VERSION ""

NS_ :

BS_:

BU_: ETH

BO_ 864 VCLEFT_alertMatrix: 8 Vector__XXX
 SG_ VCLEFT_matrixIndex M : 0|4@1+ (1,0) [0|0] "" Vector__XXX
 SG_ VCLEFT_a001_WatchdogReset m0 : 4|1@1+ (1,0) [0|0] "" Vector__XXX
 SG_ VCLEFT_a061_XCPConnected m1 : 4|1@1+ (1,0) [0|0] "" Vector__XXX
 SG_ VCLEFT_a181_rearDoorLatchRehome m3 : 4|1@1+ (1,0) [0|0] "" Vector__XXX
 SG_ VCLEFT_a241_seatHeatMIAFront m4 : 4|1@1+ (1,0) [0|0] "" Vector__XXX
 SG_ VCLEFT_a301_swcOverVoltage m5 : 4|1@1+ (1,0) [0|0] "" Vector__XXX
 SG_ VCLEFT_a361_stationaryThresholdsIncorrect m6 : 4|1@1+ (1,0) [0|0] "" Vector__XXX
 SG_ VCLEFT_a481_vnf1048SelfTestFailure m8 : 4|1@1+ (1,0) [0|0] "" Vector__XXX
 SG_ VCLEFT_a002_PowerLossReset m0 : 5|1@1+ (1,0) [0|0] "" Vector__XXX
 SG_ VCLEFT_a062_XCPWasConnected m1 : 5|1@1+ (1,0) [0|0] "" Vector__XXX
 SG_ VCLEFT_a122_ICR_MIA m2 : 5|1@1+ (1,0) [0|0] "" Vector__XXX
 SG_ VCLEFT_a182_emergencyLatchRel m3 : 5|1@1+ (1,0) [0|0] "" Vector__XXX
 SG_ VCLEFT_a242_seatHeatIRearL m4 : 5|1@1+ (1,0) [0|0] "" Vector__XXX
 SG_ VCLEFT_a302_blowerGeneralFault m5 : 5|1@1+ (1,0) [0|0] "" Vector__XXX
 SG_ VCLEFT_a362_movingThresholdsIncorrect m6 : 5|1@1+ (1,0) [0|0] "" Vector__XXX
 SG_ VCLEFT_a482_NCV77XXFault m8 : 5|1@1+ (1,0) [0|0] "" Vector__XXX
 SG_ VCLEFT_a003_SWAssertion m0 : 6|1@1+ (1,0) [0|0] "" Vector__XXX
 SG_ VCLEFT_a063_SwitchFault m1 : 6|1@1+ (1,0) [0|0] "" Vector__XXX
 SG_ VCLEFT_a123_AID_MIA m2 : 6|1@1+ (1,0) [0|0] "" Vector__XXX
 SG_ VCLEFT_a183_doorStateFactoryTest m3 : 6|1@1+ (1,0) [0|0] "" Vector__XXX
 SG_ VCLEFT_a243_seatHeatShortRearL m4 : 6|1@1+ (1,0) [0|0] "" Vector__XXX
 SG_ VCLEFT_a303_eFuseMgmtWindowLift m5 : 6|1@1+ (1,0) [0|0] "" Vector__XXX
 SG_ VCLEFT_a363_liftgateOpenAngleSetReq m6 : 6|1@1+ (1,0) [0|0] "" Vector__XXX
 SG_ VCLEFT_a483_leftTurnLightFaultUser m8 : 6|1@1+ (1,0) [0|0] "" Vector__XXX
 SG_ VCLEFT_a064_busSleepReqTimeout m1 : 7|1@1+ (1,0) [0|0] "" Vector__XXX
 SG_ VCLEFT_a244_seatHeatMIARearL m4 : 7|1@1+ (1,0) [0|0] "" Vector__XXX
 SG_ VCLEFT_a304_frontIntHandleUnexpectedVoltage m5 : 7|1@1+ (1,0) [0|0] "" Vector__XXX
 SG_ VCLEFT_a484_leftBrakeLightFaultUser m8 : 7|1@1+ (1,0) [0|0] "" Vector__XXX
 SG_ VCLEFT_a005_CANTXError m0 : 8|1@1+ (1,0) [0|0] "" Vector__XXX
 SG_ VCLEFT_a065_emiosIsrRateLimitedDbg m1 : 8|1@1+ (1,0) [0|0] "" Vector__XXX
 SG_ VCLEFT_a185_summonAborted m3 : 8|1@1+ (1,0) [0|0] "" Vector__XXX
 SG_ VCLEFT_a245_seatHeatIRearC m4 : 8|1@1+ (1,0) [0|0] "" Vector__XXX
 SG_ VCLEFT_a305_rearIntHandleUnexpectedVoltage m5 : 8|1@1+ (1,0) [0|0] "" Vector__XXX
 SG_ VCLEFT_a365_pitchUnlatchDisabled m6 : 8|1@1+ (1,0) [0|0] "" Vector__XXX
 SG_ VCLEFT_a545_LVBatteryTypeUnknown m9 : 8|1@1+ (1,0) [0|0] "" Vector__XXX
 SG_ VCLEFT_a006_CANTX_cyclicError m0 : 9|1@1+ (1,0) [0|0] "" Vector__XXX
 SG_ VCLEFT_a066_emiosIsrShortPeriodDetectedDbg m1 : 9|1@1+ (1,0) [0|0] "" Vector__XXX
 SG_ VCLEFT_a186_latchReleaseFailedF m3 : 9|1@1+ (1,0) [0|0] "" Vector__XXX
 SG_ VCLEFT_a246_seatHeatShortRearC m4 : 9|1@1+ (1,0) [0|0] "" Vector__XXX
 SG_ VCLEFT_a306_handleDisconnectedF m5 : 9|1@1+ (1,0) [0|0] "" Vector__XXX
 SG_ VCLEFT_a426_seatAbuseMotorWarn m7 : 9|1@1+ (1,0) [0|0] "" Vector__XXX
 SG_ VCLEFT_a546_mirrorFoldTypeChanged m9 : 9|1@1+ (1,0) [0|0] "" Vector__XXX
 SG_ VCLEFT_a187_latchReleaseFailedR m3 : 10|1@1+ (1,0) [0|0] "" Vector__XXX
 SG_ VCLEFT_a247_seatHeatMIARearC m4 : 10|1@1+ (1,0) [0|0] "" Vector__XXX
 SG_ VCLEFT_a307_handleDisconnectedR m5 : 10|1@1+ (1,0) [0|0] "" Vector__XXX
 SG_ VCLEFT_a427_seatAbuseMotorStop m7 : 10|1@1+ (1,0) [0|0] "" Vector__XXX
 SG_ VCLEFT_a188_latchUnableToRearmF m3 : 11|1@1+ (1,0) [0|0] "" Vector__XXX
 SG_ VCLEFT_a248_seatHeatIRearR m4 : 11|1@1+ (1,0) [0|0] "" Vector__XXX
 SG_ VCLEFT_a308_sirenMIA m5 : 11|1@1+ (1,0) [0|0] "" Vector__XXX
 SG_ VCLEFT_a428_seatAbuseBufferWarn m7 : 11|1@1+ (1,0) [0|0] "" Vector__XXX
 SG_ VCLEFT_a129_blowerICLatchFault m2 : 12|1@1+ (1,0) [0|0] "" Vector__XXX
 SG_ VCLEFT_a189_latchUnableToRearmR m3 : 12|1@1+ (1,0) [0|0] "" Vector__XXX
 SG_ VCLEFT_a249_seatHeatShortRearR m4 : 12|1@1+ (1,0) [0|0] "" Vector__XXX
 SG_ VCLEFT_a309_brakeSwitchFaulted m5 : 12|1@1+ (1,0) [0|0] "" Vector__XXX
 SG_ VCLEFT_a429_seatAbuseBufferFull m7 : 12|1@1+ (1,0) [0|0] "" Vector__XXX
 SG_ VCLEFT_a010_ExtSupplyVoltError m0 : 13|1@1+ (1,0) [0|0] "" Vector__XXX
 SG_ VCLEFT_a130_blowerICWarning m2 : 13|1@1+ (1,0) [0|0] "" Vector__XXX
 SG_ VCLEFT_a190_eFuseMgmtVbatFused m3 : 13|1@1+ (1,0) [0|0] "" Vector__XXX
 SG_ VCLEFT_a250_seatHeatMIARearR m4 : 13|1@1+ (1,0) [0|0] "" Vector__XXX
 SG_ VCLEFT_a310_mirrorFoldStall m5 : 13|1@1+ (1,0) [0|0] "" Vector__XXX
 SG_ VCLEFT_a370_seat2RowPitchUnlatched m6 : 13|1@1+ (1,0) [0|0] "" Vector__XXX
 SG_ VCLEFT_a490_vehicleOccupiedOnOTAStart m8 : 13|1@1+ (1,0) [0|0] "" Vector__XXX
 SG_ VCLEFT_a550_ambientTempDelta m9 : 13|1@1+ (1,0) [0|0] "" Vector__XXX
 SG_ VCLEFT_a131_blowerICTransFault m2 : 14|1@1+ (1,0) [0|0] "" Vector__XXX
 SG_ VCLEFT_a191_TLCOvercurrent m3 : 14|1@1+ (1,0) [0|0] "" Vector__XXX
 SG_ VCLEFT_a251_seatUncalTrack m4 : 14|1@1+ (1,0) [0|0] "" Vector__XXX
 SG_ VCLEFT_a311_leftBrakeLightFault m5 : 14|1@1+ (1,0) [0|0] "" Vector__XXX
 SG_ VCLEFT_a371_seat2RowTrackUnlatched m6 : 14|1@1+ (1,0) [0|0] "" Vector__XXX
 SG_ VCLEFT_a551_interiorDoorRequestInhibited m9 : 14|1@1+ (1,0) [0|0] "" Vector__XXX
 SG_ VCLEFT_a012_CPUReset m0 : 15|1@1+ (1,0) [0|0] "" Vector__XXX
 SG_ VCLEFT_a132_blowerSoftStall m2 : 15|1@1+ (1,0) [0|0] "" Vector__XXX
 SG_ VCLEFT_a192_blowerGeneralFault m3 : 15|1@1+ (1,0) [0|0] "" Vector__XXX
 SG_ VCLEFT_a252_seatUncalBack m4 : 15|1@1+ (1,0) [0|0] "" Vector__XXX
 SG_ VCLEFT_a312_leftTailLightFault m5 : 15|1@1+ (1,0) [0|0] "" Vector__XXX
 SG_ VCLEFT_a372_seat2RowBackrestUnlatched m6 : 15|1@1+ (1,0) [0|0] "" Vector__XXX
 SG_ VCLEFT_a013_AlertManagerFault m0 : 16|1@1+ (1,0) [0|0] "" Vector__XXX
 SG_ VCLEFT_a133_blowerLowRPMCBang m2 : 16|1@1+ (1,0) [0|0] "" Vector__XXX
 SG_ VCLEFT_a193_blowerMIA m3 : 16|1@1+ (1,0) [0|0] "" Vector__XXX
 SG_ VCLEFT_a253_seatUncalTilt m4 : 16|1@1+ (1,0) [0|0] "" Vector__XXX
 SG_ VCLEFT_a313_leftFootwellLightFault m5 : 16|1@1+ (1,0) [0|0] "" Vector__XXX
 SG_ VCLEFT_a373_windowSwOpenReqInDogMode m6 : 16|1@1+ (1,0) [0|0] "" Vector__XXX
 SG_ VCLEFT_a493_12vSocketFrontEFuseTrip m8 : 16|1@1+ (1,0) [0|0] "" Vector__XXX
 SG_ VCLEFT_a134_SteerColUpDownUnCal m2 : 17|1@1+ (1,0) [0|0] "" Vector__XXX
 SG_ VCLEFT_a254_seatUncalLift m4 : 17|1@1+ (1,0) [0|0] "" Vector__XXX
 SG_ VCLEFT_a314_leftMapPocketLightFault m5 : 17|1@1+ (1,0) [0|0] "" Vector__XXX
 SG_ VCLEFT_a374_trailerLightFaultModelY m6 : 17|1@1+ (1,0) [0|0] "" Vector__XXX
 SG_ VCLEFT_a494_12vSocketRearEFuseTrip m8 : 17|1@1+ (1,0) [0|0] "" Vector__XXX
 SG_ VCLEFT_a015_NVMMError m0 : 18|1@1+ (1,0) [0|0] "" Vector__XXX
 SG_ VCLEFT_a135_SteerColInOutUnCal m2 : 18|1@1+ (1,0) [0|0] "" Vector__XXX
 SG_ VCLEFT_a315_leftInteriorTrunkLightFault m5 : 18|1@1+ (1,0) [0|0] "" Vector__XXX
 SG_ VCLEFT_a375_windowPinchOverrideNudge m6 : 18|1@1+ (1,0) [0|0] "" Vector__XXX
 SG_ VCLEFT_a016_NVMMRecordError m0 : 19|1@1+ (1,0) [0|0] "" Vector__XXX
 SG_ VCLEFT_a136_brakeSwitchMismatch m2 : 19|1@1+ (1,0) [0|0] "" Vector__XXX
 SG_ VCLEFT_a196_VEHCANOverterminate m3 : 19|1@1+ (1,0) [0|0] "" Vector__XXX
 SG_ VCLEFT_a316_mirrorPrematureFoldStall m5 : 19|1@1+ (1,0) [0|0] "" Vector__XXX
 SG_ VCLEFT_a376_seat2RowBridgeCurrentExceeded m6 : 19|1@1+ (1,0) [0|0] "" Vector__XXX
 SG_ VCLEFT_a017_NVMMStatusDbg m0 : 20|1@1+ (1,0) [0|0] "" Vector__XXX
 SG_ VCLEFT_a137_VCSECPowerCycled m2 : 20|1@1+ (1,0) [0|0] "" Vector__XXX
 SG_ VCLEFT_a197_VEHCANUndertrminate m3 : 20|1@1+ (1,0) [0|0] "" Vector__XXX
 SG_ VCLEFT_a317_epbmLimpModeEnabled m5 : 20|1@1+ (1,0) [0|0] "" Vector__XXX
 SG_ VCLEFT_a617_APP_MIA m10 : 20|1@1+ (1,0) [0|0] "" Vector__XXX
 SG_ VCLEFT_a138_consoleDoorAssist m2 : 21|1@1+ (1,0) [0|0] "" Vector__XXX
 SG_ VCLEFT_a318_trailerIncorrectConfig m5 : 21|1@1+ (1,0) [0|0] "" Vector__XXX
 SG_ VCLEFT_a139_BLERearPowerCycled m2 : 22|1@1+ (1,0) [0|0] "" Vector__XXX
 SG_ VCLEFT_a259_latchDisarmDelayF m4 : 22|1@1+ (1,0) [0|0] "" Vector__XXX
 SG_ VCLEFT_a499_epbmInvalidateCdp m8 : 22|1@1+ (1,0) [0|0] "" Vector__XXX
 SG_ VCLEFT_a140_BLELeftPowerCycled m2 : 23|1@1+ (1,0) [0|0] "" Vector__XXX
 SG_ VCLEFT_a200_motorPhantomEncoder m3 : 23|1@1+ (1,0) [0|0] "" Vector__XXX
 SG_ VCLEFT_a260_latchDisarmDelayR m4 : 23|1@1+ (1,0) [0|0] "" Vector__XXX
 SG_ VCLEFT_a320_windowReportCrackedAtTrimClear m5 : 23|1@1+ (1,0) [0|0] "" Vector__XXX
 SG_ VCLEFT_a380_steerColThermalLimited m6 : 23|1@1+ (1,0) [0|0] "" Vector__XXX
 SG_ VCLEFT_a500_eFuseASICStateMismatch m8 : 23|1@1+ (1,0) [0|0] "" Vector__XXX
 SG_ VCLEFT_a021_TaskSchedulerError m0 : 24|1@1+ (1,0) [0|0] "" Vector__XXX
 SG_ VCLEFT_a141_12VAuxPowerTrip m2 : 24|1@1+ (1,0) [0|0] "" Vector__XXX
 SG_ VCLEFT_a201_motorDutyEncDisabl m3 : 24|1@1+ (1,0) [0|0] "" Vector__XXX
 SG_ VCLEFT_a261_emergencyLatchRelRear m4 : 24|1@1+ (1,0) [0|0] "" Vector__XXX
 SG_ VCLEFT_a321_windowRezeroedDebugF m5 : 24|1@1+ (1,0) [0|0] "" Vector__XXX
 SG_ VCLEFT_a381_pitchEstimation1 m6 : 24|1@1+ (1,0) [0|0] "" Vector__XXX
 SG_ VCLEFT_a501_vnf1048ConfigurationMismatch m8 : 24|1@1+ (1,0) [0|0] "" Vector__XXX
 SG_ VCLEFT_a022_TaskInitError m0 : 25|1@1+ (1,0) [0|0] "" Vector__XXX
 SG_ VCLEFT_a082_VCRIGHT_IPC_MIA m1 : 25|1@1+ (1,0) [0|0] "" Vector__XXX
 SG_ VCLEFT_a202_epbmUnderIStatic m3 : 25|1@1+ (1,0) [0|0] "" Vector__XXX
 SG_ VCLEFT_a322_windowRezeroedDebugR m5 : 25|1@1+ (1,0) [0|0] "" Vector__XXX
 SG_ VCLEFT_a382_pitchEstimation2 m6 : 25|1@1+ (1,0) [0|0] "" Vector__XXX
 SG_ VCLEFT_a083_VCLEFT_IPC_MIA m1 : 26|1@1+ (1,0) [0|0] "" Vector__XXX
 SG_ VCLEFT_a143_mirrorManuallyFolded m2 : 26|1@1+ (1,0) [0|0] "" Vector__XXX
 SG_ VCLEFT_a203_epbmOverIStatic m3 : 26|1@1+ (1,0) [0|0] "" Vector__XXX
 SG_ VCLEFT_a263_seatTrackStallDebug m4 : 26|1@1+ (1,0) [0|0] "" Vector__XXX
 SG_ VCLEFT_a323_mirrorCalibrated m5 : 26|1@1+ (1,0) [0|0] "" Vector__XXX
 SG_ VCLEFT_a383_steerColInOutMotorStallCurrent m6 : 26|1@1+ (1,0) [0|0] "" Vector__XXX
 SG_ VCLEFT_a084_TPMS_MIA m1 : 27|1@1+ (1,0) [0|0] "" Vector__XXX
 SG_ VCLEFT_a204_epbmUnderIDyn m3 : 27|1@1+ (1,0) [0|0] "" Vector__XXX
 SG_ VCLEFT_a264_seatBackStallDebug m4 : 27|1@1+ (1,0) [0|0] "" Vector__XXX
 SG_ VCLEFT_a324_mirrorHeatFault m5 : 27|1@1+ (1,0) [0|0] "" Vector__XXX
 SG_ VCLEFT_a384_steerColUpDownMotorStallCurrent m6 : 27|1@1+ (1,0) [0|0] "" Vector__XXX
 SG_ VCLEFT_a444_drv8703Fault m7 : 27|1@1+ (1,0) [0|0] "" Vector__XXX
 SG_ VCLEFT_a085_CCCM_MIA m1 : 28|1@1+ (1,0) [0|0] "" Vector__XXX
 SG_ VCLEFT_a145_brakeSwitchStuck m2 : 28|1@1+ (1,0) [0|0] "" Vector__XXX
 SG_ VCLEFT_a205_epbmOverIDyn m3 : 28|1@1+ (1,0) [0|0] "" Vector__XXX
 SG_ VCLEFT_a265_seatTiltStallDebug m4 : 28|1@1+ (1,0) [0|0] "" Vector__XXX
 SG_ VCLEFT_a325_hghtSnsrUnplgdFL m5 : 28|1@1+ (1,0) [0|0] "" Vector__XXX
 SG_ VCLEFT_a385_steerColInOutMotorUnderCurrent m6 : 28|1@1+ (1,0) [0|0] "" Vector__XXX
 SG_ VCLEFT_a445_drv8703SpiFaultDBG m7 : 28|1@1+ (1,0) [0|0] "" Vector__XXX
 SG_ VCLEFT_a086_VCBATT_MIA m1 : 29|1@1+ (1,0) [0|0] "" Vector__XXX
 SG_ VCLEFT_a206_epbWrongDirection m3 : 29|1@1+ (1,0) [0|0] "" Vector__XXX
 SG_ VCLEFT_a266_seatLiftStallDebug m4 : 29|1@1+ (1,0) [0|0] "" Vector__XXX
 SG_ VCLEFT_a326_hghtSnsrUnplgdRL m5 : 29|1@1+ (1,0) [0|0] "" Vector__XXX
 SG_ VCLEFT_a386_steerColUpDownMotorUnderCurrent m6 : 29|1@1+ (1,0) [0|0] "" Vector__XXX
 SG_ VCLEFT_a446_trailerAuxReversePower m7 : 29|1@1+ (1,0) [0|0] "" Vector__XXX
 SG_ VCLEFT_a087_DIREL_MIA m1 : 30|1@1+ (1,0) [0|0] "" Vector__XXX
 SG_ VCLEFT_a207_epbmEnableWrong m3 : 30|1@1+ (1,0) [0|0] "" Vector__XXX
 SG_ VCLEFT_a267_seatTrackHCEncStlDbg m4 : 30|1@1+ (1,0) [0|0] "" Vector__XXX
 SG_ VCLEFT_a327_hghtSnsrFaultFL m5 : 30|1@1+ (1,0) [0|0] "" Vector__XXX
 SG_ VCLEFT_a387_steerColInOutMotorEncoderStalled m6 : 30|1@1+ (1,0) [0|0] "" Vector__XXX
 SG_ VCLEFT_a447_steeringColInOutEndstopCal m7 : 30|1@1+ (1,0) [0|0] "" Vector__XXX
 SG_ VCLEFT_a088_DIRER_MIA m1 : 31|1@1+ (1,0) [0|0] "" Vector__XXX
 SG_ VCLEFT_a208_epbFaulted m3 : 31|1@1+ (1,0) [0|0] "" Vector__XXX
 SG_ VCLEFT_a268_seatBackHCEncStlDbg m4 : 31|1@1+ (1,0) [0|0] "" Vector__XXX
 SG_ VCLEFT_a328_hghtSnsrFaultRL m5 : 31|1@1+ (1,0) [0|0] "" Vector__XXX
 SG_ VCLEFT_a388_steerColUpDownMotorEncoderStalled m6 : 31|1@1+ (1,0) [0|0] "" Vector__XXX
 SG_ VCLEFT_a448_steeringColUpDownEndstopCal m7 : 31|1@1+ (1,0) [0|0] "" Vector__XXX
 SG_ VCLEFT_a029_CoreDump m0 : 32|1@1+ (1,0) [0|0] "" Vector__XXX
 SG_ VCLEFT_a089_IBST_MIA m1 : 32|1@1+ (1,0) [0|0] "" Vector__XXX
 SG_ VCLEFT_a209_epbStateMisTime m3 : 32|1@1+ (1,0) [0|0] "" Vector__XXX
 SG_ VCLEFT_a269_seatTiltHCEncStlDbg m4 : 32|1@1+ (1,0) [0|0] "" Vector__XXX
 SG_ VCLEFT_a329_noRideHeightCalib m5 : 32|1@1+ (1,0) [0|0] "" Vector__XXX
 SG_ VCLEFT_a389_steerColInOutEncoderOutOfRange m6 : 32|1@1+ (1,0) [0|0] "" Vector__XXX
 SG_ VCLEFT_a030_ECULogUploadRequest m0 : 33|1@1+ (1,0) [0|0] "" Vector__XXX
 SG_ VCLEFT_a090_APS_MIA m1 : 33|1@1+ (1,0) [0|0] "" Vector__XXX
 SG_ VCLEFT_a150_windowPinchFront m2 : 33|1@1+ (1,0) [0|0] "" Vector__XXX
 SG_ VCLEFT_a210_epbStateTime m3 : 33|1@1+ (1,0) [0|0] "" Vector__XXX
 SG_ VCLEFT_a270_seatLiftHCEncStlDbg m4 : 33|1@1+ (1,0) [0|0] "" Vector__XXX
 SG_ VCLEFT_a330_shortDropFailedF m5 : 33|1@1+ (1,0) [0|0] "" Vector__XXX
 SG_ VCLEFT_a390_steerColUpDownEncoderOutOfRange m6 : 33|1@1+ (1,0) [0|0] "" Vector__XXX
 SG_ VCLEFT_a570_seatHeatDisabledF m9 : 33|1@1+ (1,0) [0|0] "" Vector__XXX
 SG_ VCLEFT_a031_UDSActive m0 : 34|1@1+ (1,0) [0|0] "" Vector__XXX
 SG_ VCLEFT_a091_CMPD_MIA m1 : 34|1@1+ (1,0) [0|0] "" Vector__XXX
 SG_ VCLEFT_a151_windowPinchRear m2 : 34|1@1+ (1,0) [0|0] "" Vector__XXX
 SG_ VCLEFT_a211_epbmUnderIStaticNew m3 : 34|1@1+ (1,0) [0|0] "" Vector__XXX
 SG_ VCLEFT_a331_shortDropFailedR m5 : 34|1@1+ (1,0) [0|0] "" Vector__XXX
 SG_ VCLEFT_a391_pitchEstimationImplausible m6 : 34|1@1+ (1,0) [0|0] "" Vector__XXX
 SG_ VCLEFT_a451_wirelessChargerMIA m7 : 34|1@1+ (1,0) [0|0] "" Vector__XXX
 SG_ VCLEFT_a571_seatHeatDisabledRearL m9 : 34|1@1+ (1,0) [0|0] "" Vector__XXX
 SG_ VCLEFT_a092_VCSEATD_MIA m1 : 35|1@1+ (1,0) [0|0] "" Vector__XXX
 SG_ VCLEFT_a152_windowUncalFront m2 : 35|1@1+ (1,0) [0|0] "" Vector__XXX
 SG_ VCLEFT_a212_epbmOverIStaticNew m3 : 35|1@1+ (1,0) [0|0] "" Vector__XXX
 SG_ VCLEFT_a272_vhclPwrStateMsmtch m4 : 35|1@1+ (1,0) [0|0] "" Vector__XXX
 SG_ VCLEFT_a332_intrusionSensorMIA m5 : 35|1@1+ (1,0) [0|0] "" Vector__XXX
 SG_ VCLEFT_a392_pitchEstimationGPSImprovedReinit m6 : 35|1@1+ (1,0) [0|0] "" Vector__XXX
 SG_ VCLEFT_a572_seatHeatDisabledRearC m9 : 35|1@1+ (1,0) [0|0] "" Vector__XXX
 SG_ VCLEFT_a093_VCSEATP_MIA m1 : 36|1@1+ (1,0) [0|0] "" Vector__XXX
 SG_ VCLEFT_a153_windowUncalRear m2 : 36|1@1+ (1,0) [0|0] "" Vector__XXX
 SG_ VCLEFT_a213_epbmUnderIDynNew m3 : 36|1@1+ (1,0) [0|0] "" Vector__XXX
 SG_ VCLEFT_a273_handleStuckActiveF m4 : 36|1@1+ (1,0) [0|0] "" Vector__XXX
 SG_ VCLEFT_a333_overheadConsoleMIA m5 : 36|1@1+ (1,0) [0|0] "" Vector__XXX
 SG_ VCLEFT_a393_pitchEstimationNoGPSFusion m6 : 36|1@1+ (1,0) [0|0] "" Vector__XXX
 SG_ VCLEFT_a453_liftgatePinchDetected m7 : 36|1@1+ (1,0) [0|0] "" Vector__XXX
 SG_ VCLEFT_a573_seatHeatDisabledRearR m9 : 36|1@1+ (1,0) [0|0] "" Vector__XXX
 SG_ VCLEFT_a094_EPAS3P_MIA m1 : 37|1@1+ (1,0) [0|0] "" Vector__XXX
 SG_ VCLEFT_a154_windowThermalFront m2 : 37|1@1+ (1,0) [0|0] "" Vector__XXX
 SG_ VCLEFT_a214_epbmOverIDynNew m3 : 37|1@1+ (1,0) [0|0] "" Vector__XXX
 SG_ VCLEFT_a274_handleStuckActiveR m4 : 37|1@1+ (1,0) [0|0] "" Vector__XXX
 SG_ VCLEFT_a334_overheadConsoleInternalFault m5 : 37|1@1+ (1,0) [0|0] "" Vector__XXX
 SG_ VCLEFT_a454_wirelessChargerFault m7 : 37|1@1+ (1,0) [0|0] "" Vector__XXX
 SG_ VCLEFT_a095_CHG_MIA m1 : 38|1@1+ (1,0) [0|0] "" Vector__XXX
 SG_ VCLEFT_a155_windowThermalRear m2 : 38|1@1+ (1,0) [0|0] "" Vector__XXX
 SG_ VCLEFT_a215_currentDesyncWarning m3 : 38|1@1+ (1,0) [0|0] "" Vector__XXX
 SG_ VCLEFT_a275_leftTurnLightFault m4 : 38|1@1+ (1,0) [0|0] "" Vector__XXX
 SG_ VCLEFT_a335_intrusionSensorInternalFault m5 : 38|1@1+ (1,0) [0|0] "" Vector__XXX
 SG_ VCLEFT_a455_liftgateUnexpectedShutfaceSwPressed m7 : 38|1@1+ (1,0) [0|0] "" Vector__XXX
 SG_ VCLEFT_a096_OCS1P_MIA m1 : 39|1@1+ (1,0) [0|0] "" Vector__XXX
 SG_ VCLEFT_a156_windowNoInputFront m2 : 39|1@1+ (1,0) [0|0] "" Vector__XXX
 SG_ VCLEFT_a216_SPI_MIA_debugData1 m3 : 39|1@1+ (1,0) [0|0] "" Vector__XXX
 SG_ VCLEFT_a276_mirrorDebug m4 : 39|1@1+ (1,0) [0|0] "" Vector__XXX
 SG_ VCLEFT_a336_windowDropRevThermalF m5 : 39|1@1+ (1,0) [0|0] "" Vector__XXX
 SG_ VCLEFT_a097_CMP_MIA m1 : 40|1@1+ (1,0) [0|0] "" Vector__XXX
 SG_ VCLEFT_a157_windowNoInputRear m2 : 40|1@1+ (1,0) [0|0] "" Vector__XXX
 SG_ VCLEFT_a217_SPI_MIA_debugData2 m3 : 40|1@1+ (1,0) [0|0] "" Vector__XXX
 SG_ VCLEFT_a277_BLELeftUnderVoltage m4 : 40|1@1+ (1,0) [0|0] "" Vector__XXX
 SG_ VCLEFT_a337_windowDropRevThermalR m5 : 40|1@1+ (1,0) [0|0] "" Vector__XXX
 SG_ VCLEFT_a098_DIR_MIA m1 : 41|1@1+ (1,0) [0|0] "" Vector__XXX
 SG_ VCLEFT_a158_windowPinchOverideF m2 : 41|1@1+ (1,0) [0|0] "" Vector__XXX
 SG_ VCLEFT_a218_motorDriverFault m3 : 41|1@1+ (1,0) [0|0] "" Vector__XXX
 SG_ VCLEFT_a278_BLERearUnderVoltage m4 : 41|1@1+ (1,0) [0|0] "" Vector__XXX
 SG_ VCLEFT_a338_trailerLightControllerMIA m5 : 41|1@1+ (1,0) [0|0] "" Vector__XXX
 SG_ VCLEFT_a099_PARK_MIA m1 : 42|1@1+ (1,0) [0|0] "" Vector__XXX
 SG_ VCLEFT_a159_windowPinchOverideR m2 : 42|1@1+ (1,0) [0|0] "" Vector__XXX
 SG_ VCLEFT_a219_motorCurrentDropout m3 : 42|1@1+ (1,0) [0|0] "" Vector__XXX
 SG_ VCLEFT_a279_VCSECUnderVoltage m4 : 42|1@1+ (1,0) [0|0] "" Vector__XXX
 SG_ VCLEFT_a339_trailerLeftTurnLightNotDetected m5 : 42|1@1+ (1,0) [0|0] "" Vector__XXX
 SG_ VCLEFT_a100_CANbus_MIA m1 : 43|1@1+ (1,0) [0|0] "" Vector__XXX
 SG_ VCLEFT_a160_windowUndercurrentF m2 : 43|1@1+ (1,0) [0|0] "" Vector__XXX
 SG_ VCLEFT_a280_latchDidNotDisarmF m4 : 43|1@1+ (1,0) [0|0] "" Vector__XXX
 SG_ VCLEFT_a340_trailerRightTurnLightNotDetected m5 : 43|1@1+ (1,0) [0|0] "" Vector__XXX
 SG_ VCLEFT_a520_configMismatch m8 : 43|1@1+ (1,0) [0|0] "" Vector__XXX
 SG_ VCLEFT_a041_HighCPULoad m0 : 44|1@1+ (1,0) [0|0] "" Vector__XXX
 SG_ VCLEFT_a101_PM_MIA m1 : 44|1@1+ (1,0) [0|0] "" Vector__XXX
 SG_ VCLEFT_a161_windowUndercurrentR m2 : 44|1@1+ (1,0) [0|0] "" Vector__XXX
 SG_ VCLEFT_a281_latchDidNotDisarmR m4 : 44|1@1+ (1,0) [0|0] "" Vector__XXX
 SG_ VCLEFT_a341_trailerLightFault m5 : 44|1@1+ (1,0) [0|0] "" Vector__XXX
 SG_ VCLEFT_a521_seatHeatPadUnexpectedVoltage m8 : 44|1@1+ (1,0) [0|0] "" Vector__XXX
 SG_ VCLEFT_a042_HighStackUsage m0 : 45|1@1+ (1,0) [0|0] "" Vector__XXX
 SG_ VCLEFT_a102_PTC_MIA m1 : 45|1@1+ (1,0) [0|0] "" Vector__XXX
 SG_ VCLEFT_a162_windowEncoderStallF m2 : 45|1@1+ (1,0) [0|0] "" Vector__XXX
 SG_ VCLEFT_a282_latchUnexpectedArmF m4 : 45|1@1+ (1,0) [0|0] "" Vector__XXX
 SG_ VCLEFT_a342_trailerLightControllerFault m5 : 45|1@1+ (1,0) [0|0] "" Vector__XXX
 SG_ VCLEFT_a522_trailerLightUnexpectedVoltage m8 : 45|1@1+ (1,0) [0|0] "" Vector__XXX
 SG_ VCLEFT_a043_Task1msError m0 : 46|1@1+ (1,0) [0|0] "" Vector__XXX
 SG_ VCLEFT_a103_CP_MIA m1 : 46|1@1+ (1,0) [0|0] "" Vector__XXX
 SG_ VCLEFT_a163_windowEncoderStallR m2 : 46|1@1+ (1,0) [0|0] "" Vector__XXX
 SG_ VCLEFT_a283_latchUnexpectedArmR m4 : 46|1@1+ (1,0) [0|0] "" Vector__XXX
 SG_ VCLEFT_a523_eFuseThresholdsIncorrect m8 : 46|1@1+ (1,0) [0|0] "" Vector__XXX
 SG_ VCLEFT_a583_doorRemoteUnlatchedFront m9 : 46|1@1+ (1,0) [0|0] "" Vector__XXX
 SG_ VCLEFT_a044_Task10msError m0 : 47|1@1+ (1,0) [0|0] "" Vector__XXX
 SG_ VCLEFT_a104_DAS_MIA m1 : 47|1@1+ (1,0) [0|0] "" Vector__XXX
 SG_ VCLEFT_a164_windowFactoryTest m2 : 47|1@1+ (1,0) [0|0] "" Vector__XXX
 SG_ VCLEFT_a224_seatEncStallTrack m3 : 47|1@1+ (1,0) [0|0] "" Vector__XXX
 SG_ VCLEFT_a284_blowerFbkSanity m4 : 47|1@1+ (1,0) [0|0] "" Vector__XXX
 SG_ VCLEFT_a584_doorRemoteUnlatchedRear m9 : 47|1@1+ (1,0) [0|0] "" Vector__XXX
 SG_ VCLEFT_a045_Task100msError m0 : 48|1@1+ (1,0) [0|0] "" Vector__XXX
 SG_ VCLEFT_a105_TAS_MIA m1 : 48|1@1+ (1,0) [0|0] "" Vector__XXX
 SG_ VCLEFT_a165_windowFactoryTest2 m2 : 48|1@1+ (1,0) [0|0] "" Vector__XXX
 SG_ VCLEFT_a225_seatEncStallBack m3 : 48|1@1+ (1,0) [0|0] "" Vector__XXX
 SG_ VCLEFT_a285_blowerChipComms m4 : 48|1@1+ (1,0) [0|0] "" Vector__XXX
 SG_ VCLEFT_a345_chargePortPowerCycling m5 : 48|1@1+ (1,0) [0|0] "" Vector__XXX
 SG_ VCLEFT_a525_LVBatterySWMisconfiguration m8 : 48|1@1+ (1,0) [0|0] "" Vector__XXX
 SG_ VCLEFT_a585_doorRemoteUnlatchFailedFront m9 : 48|1@1+ (1,0) [0|0] "" Vector__XXX
 SG_ VCLEFT_a046_Task1000msError m0 : 49|1@1+ (1,0) [0|0] "" Vector__XXX
 SG_ VCLEFT_a106_PCS_MIA m1 : 49|1@1+ (1,0) [0|0] "" Vector__XXX
 SG_ VCLEFT_a166_windowDebug m2 : 49|1@1+ (1,0) [0|0] "" Vector__XXX
 SG_ VCLEFT_a226_seatEncStallTilt m3 : 49|1@1+ (1,0) [0|0] "" Vector__XXX
 SG_ VCLEFT_a286_windowSpeedInvalidF m4 : 49|1@1+ (1,0) [0|0] "" Vector__XXX
 SG_ VCLEFT_a346_eFuseMgmtVbatFused2 m5 : 49|1@1+ (1,0) [0|0] "" Vector__XXX
 SG_ VCLEFT_a526_pcbaOverTemperature m8 : 49|1@1+ (1,0) [0|0] "" Vector__XXX
 SG_ VCLEFT_a586_doorRemoteUnlatchFailedRear m9 : 49|1@1+ (1,0) [0|0] "" Vector__XXX
 SG_ VCLEFT_a107_BMS_MIA m1 : 50|1@1+ (1,0) [0|0] "" Vector__XXX
 SG_ VCLEFT_a167_windowDebugPinchF m2 : 50|1@1+ (1,0) [0|0] "" Vector__XXX
 SG_ VCLEFT_a227_seatEncStallLift m3 : 50|1@1+ (1,0) [0|0] "" Vector__XXX
 SG_ VCLEFT_a287_windowSpeedInvalidR m4 : 50|1@1+ (1,0) [0|0] "" Vector__XXX
 SG_ VCLEFT_a347_nonContMonitorClearedDBG m5 : 50|1@1+ (1,0) [0|0] "" Vector__XXX
 SG_ VCLEFT_a527_continuousFeedUnexpectedVoltage m8 : 50|1@1+ (1,0) [0|0] "" Vector__XXX
 SG_ VCLEFT_a108_DIF_MIA m1 : 51|1@1+ (1,0) [0|0] "" Vector__XXX
 SG_ VCLEFT_a168_windowDebugPinchR m2 : 51|1@1+ (1,0) [0|0] "" Vector__XXX
 SG_ VCLEFT_a228_seatEncOverTrack m3 : 51|1@1+ (1,0) [0|0] "" Vector__XXX
 SG_ VCLEFT_a288_handlePWMPeriodF m4 : 51|1@1+ (1,0) [0|0] "" Vector__XXX
 SG_ VCLEFT_a348_CPSleepOvercurrent m5 : 51|1@1+ (1,0) [0|0] "" Vector__XXX
 SG_ VCLEFT_a528_unableToRunStuckOnTest m8 : 51|1@1+ (1,0) [0|0] "" Vector__XXX
 SG_ VCLEFT_a109_RCM_MIA m1 : 52|1@1+ (1,0) [0|0] "" Vector__XXX
 SG_ VCLEFT_a169_windowCurrentPeakF m2 : 52|1@1+ (1,0) [0|0] "" Vector__XXX
 SG_ VCLEFT_a229_seatEncOverBack m3 : 52|1@1+ (1,0) [0|0] "" Vector__XXX
 SG_ VCLEFT_a289_handlePWMPeriodR m4 : 52|1@1+ (1,0) [0|0] "" Vector__XXX
 SG_ VCLEFT_a349_CPSleepUndervoltage m5 : 52|1@1+ (1,0) [0|0] "" Vector__XXX
 SG_ VCLEFT_a110_GTW_MIA m1 : 53|1@1+ (1,0) [0|0] "" Vector__XXX
 SG_ VCLEFT_a170_windowCurrentPeakR m2 : 53|1@1+ (1,0) [0|0] "" Vector__XXX
 SG_ VCLEFT_a230_seatEncOverTilt m3 : 53|1@1+ (1,0) [0|0] "" Vector__XXX
 SG_ VCLEFT_a290_occupancyFaultedFront m4 : 53|1@1+ (1,0) [0|0] "" Vector__XXX
 SG_ VCLEFT_a350_ensOutOfRange m5 : 53|1@1+ (1,0) [0|0] "" Vector__XXX
 SG_ VCLEFT_a111_EPBR_MIA m1 : 54|1@1+ (1,0) [0|0] "" Vector__XXX
 SG_ VCLEFT_a231_seatEncOverLift m3 : 54|1@1+ (1,0) [0|0] "" Vector__XXX
 SG_ VCLEFT_a291_buckleFaultedFront m4 : 54|1@1+ (1,0) [0|0] "" Vector__XXX
 SG_ VCLEFT_a351_debugLiftgateCurrentSpike m5 : 54|1@1+ (1,0) [0|0] "" Vector__XXX
 SG_ VCLEFT_a112_EPBL_MIA m1 : 55|1@1+ (1,0) [0|0] "" Vector__XXX
 SG_ VCLEFT_a172_SPI_MIA m2 : 55|1@1+ (1,0) [0|0] "" Vector__XXX
 SG_ VCLEFT_a232_seatCurrUnderTrack m3 : 55|1@1+ (1,0) [0|0] "" Vector__XXX
 SG_ VCLEFT_a292_occupancyFaultedRearL m4 : 55|1@1+ (1,0) [0|0] "" Vector__XXX
 SG_ VCLEFT_a352_liftgateClosingLatchEntryFailed m5 : 55|1@1+ (1,0) [0|0] "" Vector__XXX
 SG_ VCLEFT_a113_UI_MIA m1 : 56|1@1+ (1,0) [0|0] "" Vector__XXX
 SG_ VCLEFT_a173_windowBtnDoorOpen m2 : 56|1@1+ (1,0) [0|0] "" Vector__XXX
 SG_ VCLEFT_a233_seatCurrUnderBack m3 : 56|1@1+ (1,0) [0|0] "" Vector__XXX
 SG_ VCLEFT_a293_occupancyFaultedRearC m4 : 56|1@1+ (1,0) [0|0] "" Vector__XXX
 SG_ VCLEFT_a353_eFuseMgmtSteeringColumn m5 : 56|1@1+ (1,0) [0|0] "" Vector__XXX
 SG_ VCLEFT_a114_ESP_MIA m1 : 57|1@1+ (1,0) [0|0] "" Vector__XXX
 SG_ VCLEFT_a234_seatCurrUnderTilt m3 : 57|1@1+ (1,0) [0|0] "" Vector__XXX
 SG_ VCLEFT_a294_occupancyFaultedRearR m4 : 57|1@1+ (1,0) [0|0] "" Vector__XXX
 SG_ VCLEFT_a354_eFuseMgmtLiftGate m5 : 57|1@1+ (1,0) [0|0] "" Vector__XXX
 SG_ VCLEFT_a115_VCSEC_MIA m1 : 58|1@1+ (1,0) [0|0] "" Vector__XXX
 SG_ VCLEFT_a175_windowSealDefectFront m2 : 58|1@1+ (1,0) [0|0] "" Vector__XXX
 SG_ VCLEFT_a235_seatCurrUnderLift m3 : 58|1@1+ (1,0) [0|0] "" Vector__XXX
 SG_ VCLEFT_a295_buckleFaultedRearL m4 : 58|1@1+ (1,0) [0|0] "" Vector__XXX
 SG_ VCLEFT_a355_liftgateUnexpectedStop m5 : 58|1@1+ (1,0) [0|0] "" Vector__XXX
 SG_ VCLEFT_a116_VCRIGHT_MIA m1 : 59|1@1+ (1,0) [0|0] "" Vector__XXX
 SG_ VCLEFT_a176_windowSealDefectRear m2 : 59|1@1+ (1,0) [0|0] "" Vector__XXX
 SG_ VCLEFT_a236_lumbarOverPresA m3 : 59|1@1+ (1,0) [0|0] "" Vector__XXX
 SG_ VCLEFT_a296_buckleFaultedRearC m4 : 59|1@1+ (1,0) [0|0] "" Vector__XXX
 SG_ VCLEFT_a356_liftgateFactoryTest m5 : 59|1@1+ (1,0) [0|0] "" Vector__XXX
 SG_ VCLEFT_a536_trunkFoldFlatSwitchFault m8 : 59|1@1+ (1,0) [0|0] "" Vector__XXX
 SG_ VCLEFT_a057_HVP_MIA m0 : 60|1@1+ (1,0) [0|0] "" Vector__XXX
 SG_ VCLEFT_a117_VCLEFT_MIA m1 : 60|1@1+ (1,0) [0|0] "" Vector__XXX
 SG_ VCLEFT_a237_lumbarOverPresB m3 : 60|1@1+ (1,0) [0|0] "" Vector__XXX
 SG_ VCLEFT_a297_seatBelowMinPumpTmp m4 : 60|1@1+ (1,0) [0|0] "" Vector__XXX
 SG_ VCLEFT_a357_liftgateUncalibrated m5 : 60|1@1+ (1,0) [0|0] "" Vector__XXX
 SG_ VCLEFT_a058_inputRHighSyncDebug m0 : 61|1@1+ (1,0) [0|0] "" Vector__XXX
 SG_ VCLEFT_a118_VCFRONT_MIA m1 : 61|1@1+ (1,0) [0|0] "" Vector__XXX
 SG_ VCLEFT_a238_lumbarValveMIA m3 : 61|1@1+ (1,0) [0|0] "" Vector__XXX
 SG_ VCLEFT_a358_debugLiftgateCurrentDropout m5 : 61|1@1+ (1,0) [0|0] "" Vector__XXX
 SG_ VCLEFT_a478_BPillarCameraHeaterFault m7 : 61|1@1+ (1,0) [0|0] "" Vector__XXX
 SG_ VCLEFT_a059_inputResistanceHigh m0 : 62|1@1+ (1,0) [0|0] "" Vector__XXX
 SG_ VCLEFT_a119_SCCM_MIA m1 : 62|1@1+ (1,0) [0|0] "" Vector__XXX
 SG_ VCLEFT_a239_seatHeatIFront m3 : 62|1@1+ (1,0) [0|0] "" Vector__XXX
 SG_ VCLEFT_a299_swcMIA m4 : 62|1@1+ (1,0) [0|0] "" Vector__XXX
 SG_ VCLEFT_a359_liftgateLatchExitNoPositionChange m5 : 62|1@1+ (1,0) [0|0] "" Vector__XXX
 SG_ VCLEFT_a599_LVBatteryTypeUnsupported m9 : 62|1@1+ (1,0) [0|0] "" Vector__XXX
 SG_ VCLEFT_a060_engineeringBuild m0 : 63|1@1+ (1,0) [0|0] "" Vector__XXX
 SG_ VCLEFT_a120_DI_DRIVE_MIA m1 : 63|1@1+ (1,0) [0|0] "" Vector__XXX
 SG_ VCLEFT_a180_frontDoorLatchRehome m2 : 63|1@1+ (1,0) [0|0] "" Vector__XXX
 SG_ VCLEFT_a240_seatHeatShortFront m3 : 63|1@1+ (1,0) [0|0] "" Vector__XXX
 SG_ VCLEFT_a300_swcUnderVoltage m4 : 63|1@1+ (1,0) [0|0] "" Vector__XXX
 SG_ VCLEFT_a360_detectedStationaryWhileMoving m5 : 63|1@1+ (1,0) [0|0] "" Vector__XXX
 SG_ VCLEFT_a480_vnf1048Fault m7 : 63|1@1+ (1,0) [0|0] "" Vector__XXX

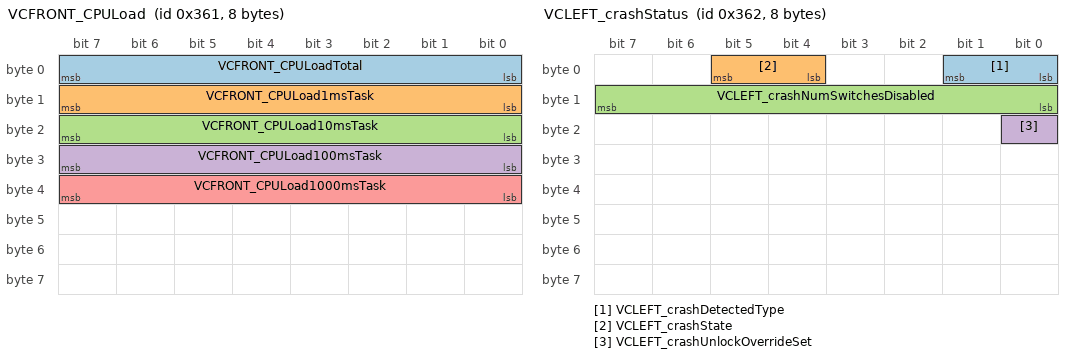
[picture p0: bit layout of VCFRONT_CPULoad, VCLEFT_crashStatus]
BO_ 865 VCFRONT_CPULoad: 8 Vector__XXX
 SG_ VCFRONT_CPULoadTotal : 0|8@1+ (1,0) [0|0] "" Vector__XXX
 SG_ VCFRONT_CPULoad1msTask : 8|8@1+ (1,0) [0|0] "" Vector__XXX
 SG_ VCFRONT_CPULoad10msTask : 16|8@1+ (1,0) [0|0] "" Vector__XXX
 SG_ VCFRONT_CPULoad100msTask : 24|8@1+ (1,0) [0|0] "" Vector__XXX
 SG_ VCFRONT_CPULoad1000msTask : 32|8@1+ (1,0) [0|0] "" Vector__XXX

BO_ 866 VCLEFT_crashStatus: 8 Vector__XXX
 SG_ VCLEFT_crashDetectedType : 0|2@1+ (1,0) [0|0] "" Vector__XXX
 SG_ VCLEFT_crashState : 4|2@1+ (1,0) [0|0] "" Vector__XXX
 SG_ VCLEFT_crashNumSwitchesDisabled : 8|8@1+ (1,0) [0|0] "" Vector__XXX
 SG_ VCLEFT_crashUnlockOverrideSet : 16|1@1+ (1,0) [0|0] "" Vector__XXX

BO_ 867 CMP_info: 8 Vector__XXX
 SG_ CMP_infoIndex M : 0|8@1+ (1,0) [0|0] "" Vector__XXX
 SG_ CMP_infoBootUdsProtoVersion m20 : 8|8@1+ (1,0) [0|0] "" Vector__XXX
 SG_ CMP_infoBuildType m10 : 8|8@1+ (1,0) [0|0] "" Vector__XXX
 SG_ CMP_infoPlatformType m13 : 8|8@1+ (1,0) [0|0] "" Vector__XXX
 SG_ CMP_infoBuildConfigId m10 : 16|16@1+ (1,0) [0|0] "" Vector__XXX
 SG_ CMP_infoPcbaId m11 : 16|8@1+ (1,0) [0|0] "" Vector__XXX
 SG_ CMP_infoAssemblyId m11 : 24|8@1+ (1,0) [0|0] "" Vector__XXX
 SG_ CMP_infoAppCrc m13 : 32|32@1+ (1,0) [0|0] "" Vector__XXX
 SG_ CMP_infoBootCrc m20 : 32|32@1+ (1,0) [0|0] "" Vector__XXX
 SG_ CMP_infoHardwareId m10 : 32|16@1+ (1,0) [0|0] "" Vector__XXX
 SG_ CMP_infoUsageId m11 : 32|16@1+ (1,0) [0|0] "" Vector__XXX
 SG_ CMP_infoComponentId m10 : 48|16@1+ (1,0) [0|0] "" Vector__XXX
 SG_ CMP_infoSubUsageId m11 : 48|16@1+ (1,0) [0|0] "" Vector__XXX

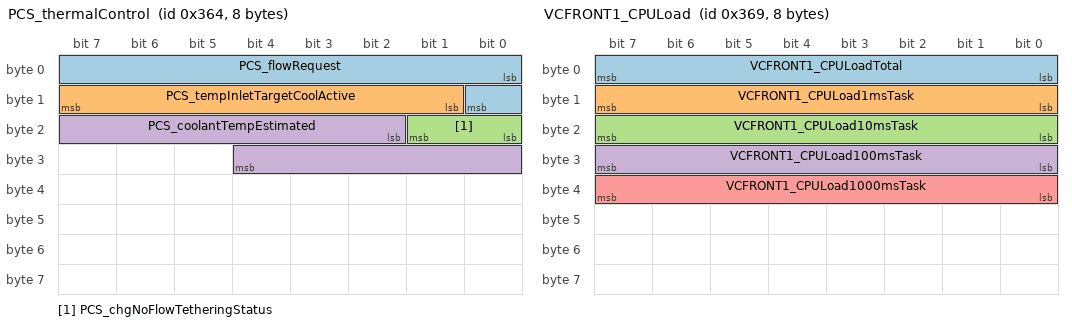
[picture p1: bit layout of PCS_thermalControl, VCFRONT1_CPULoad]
BO_ 868 PCS_thermalControl: 8 Vector__XXX
 SG_ PCS_flowRequest : 0|9@1+ (0.1,0) [0|0] "" Vector__XXX
 SG_ PCS_tempInletTargetCoolActive : 9|7@1+ (1,0) [0|0] "" Vector__XXX
 SG_ PCS_chgNoFlowTetheringStatus : 16|2@1+ (1,0) [0|0] "" Vector__XXX
 SG_ PCS_coolantTempEstimated : 18|11@1- (0.1,40) [0|0] "" Vector__XXX

BO_ 869 SCS_alertMatrix1: 8 Vector__XXX
 SG_ SCS_a001_hwDSPfault : 0|1@1+ (1,0) [0|0] "" Vector__XXX
 SG_ SCS_a002_hwIbatOC : 1|1@1+ (1,0) [0|0] "" Vector__XXX
 SG_ SCS_a003_hwCordOT : 2|1@1+ (1,0) [0|0] "" Vector__XXX
 SG_ SCS_a004_hwVbusOV : 3|1@1+ (1,0) [0|0] "" Vector__XXX
 SG_ SCS_a005_hwHVIL : 4|1@1+ (1,0) [0|0] "" Vector__XXX
 SG_ SCS_a006_hwWeld_V1 : 5|1@1+ (1,0) [0|0] "" Vector__XXX
 SG_ SCS_a007_hwWeld_V2 : 6|1@1+ (1,0) [0|0] "" Vector__XXX
 SG_ SCS_a008_hwIllegalCntrShoot : 7|1@1+ (1,0) [0|0] "" Vector__XXX
 SG_ SCS_a009_hwOpen_V1 : 8|1@1+ (1,0) [0|0] "" Vector__XXX
 SG_ SCS_a010_hwOpen_V2 : 9|1@1+ (1,0) [0|0] "" Vector__XXX
 SG_ SCS_a011_hwIllegalCntrCmdV1 : 10|1@1+ (1,0) [0|0] "" Vector__XXX
 SG_ SCS_a012_hwIllegalCntrCmdV2 : 11|1@1+ (1,0) [0|0] "" Vector__XXX
 SG_ SCS_a013_cordTempHiFoldBk : 12|1@1+ (1,0) [0|0] "" Vector__XXX
 SG_ SCS_a014_coolantTempHiFoldBk : 13|1@1+ (1,0) [0|0] "" Vector__XXX
 SG_ SCS_a015_cpldRationality : 14|1@1+ (1,0) [0|0] "" Vector__XXX
 SG_ SCS_a016_unusedHW16 : 15|1@1+ (1,0) [0|0] "" Vector__XXX
 SG_ SCS_a017_unusedHW17 : 16|1@1+ (1,0) [0|0] "" Vector__XXX
 SG_ SCS_a018_unusedHW18 : 17|1@1+ (1,0) [0|0] "" Vector__XXX
 SG_ SCS_a019_unusedHW19 : 18|1@1+ (1,0) [0|0] "" Vector__XXX
 SG_ SCS_a020_unusedHW20 : 19|1@1+ (1,0) [0|0] "" Vector__XXX
 SG_ SCS_a021_unusedHW21 : 20|1@1+ (1,0) [0|0] "" Vector__XXX
 SG_ SCS_a024_emergencyShutdown : 23|1@1+ (1,0) [0|0] "" Vector__XXX
 SG_ SCS_a025_internalIsolationFault : 24|1@1+ (1,0) [0|0] "" Vector__XXX
 SG_ SCS_a026_internalIsolationLow : 25|1@1+ (1,0) [0|0] "" Vector__XXX
 SG_ SCS_a027_externalIsolationLow : 26|1@1+ (1,0) [0|0] "" Vector__XXX
 SG_ SCS_a028_isolationRationality : 27|1@1+ (1,0) [0|0] "" Vector__XXX
 SG_ SCS_a029_VbatOV : 28|1@1+ (1,0) [0|0] "" Vector__XXX
 SG_ SCS_a030_VbusOV : 29|1@1+ (1,0) [0|0] "" Vector__XXX
 SG_ SCS_a031_IbatOC : 30|1@1+ (1,0) [0|0] "" Vector__XXX
 SG_ SCS_a032_VBatRationality : 31|1@1+ (1,0) [0|0] "" Vector__XXX
 SG_ SCS_a033_VBusRationality : 32|1@1+ (1,0) [0|0] "" Vector__XXX
 SG_ SCS_a034_IBatRationality : 33|1@1+ (1,0) [0|0] "" Vector__XXX
 SG_ SCS_a035_unexpectedVbusBehavior : 34|1@1+ (1,0) [0|0] "" Vector__XXX
 SG_ SCS_a036_internalContactorWelded : 35|1@1+ (1,0) [0|0] "" Vector__XXX
 SG_ SCS_a037_outputContactorWelded : 36|1@1+ (1,0) [0|0] "" Vector__XXX
 SG_ SCS_a038_contactorFailedOpen : 37|1@1+ (1,0) [0|0] "" Vector__XXX
 SG_ SCS_a039_ibatRegulation : 38|1@1+ (1,0) [0|0] "" Vector__XXX
 SG_ SCS_a040_plus12VOutOfRange : 39|1@1+ (1,0) [0|0] "" Vector__XXX
 SG_ SCS_a041_minus12VOutOfRange : 40|1@1+ (1,0) [0|0] "" Vector__XXX
 SG_ SCS_a042_pilotOutOfRange : 41|1@1+ (1,0) [0|0] "" Vector__XXX
 SG_ SCS_a043_pilotRationality : 42|1@1+ (1,0) [0|0] "" Vector__XXX
 SG_ SCS_a044_proximityRationality : 43|1@1+ (1,0) [0|0] "" Vector__XXX
 SG_ SCS_a045_pcbaOT : 44|1@1+ (1,0) [0|0] "" Vector__XXX
 SG_ SCS_a046_coolantOT : 45|1@1+ (1,0) [0|0] "" Vector__XXX
 SG_ SCS_a047_cordOT : 46|1@1+ (1,0) [0|0] "" Vector__XXX
 SG_ SCS_a048_ambientOT : 47|1@1+ (1,0) [0|0] "" Vector__XXX
 SG_ SCS_a049_pcbaTempRationality : 48|1@1+ (1,0) [0|0] "" Vector__XXX
 SG_ SCS_a050_coolantTempRationality : 49|1@1+ (1,0) [0|0] "" Vector__XXX
 SG_ SCS_a051_cordTempRationality : 50|1@1+ (1,0) [0|0] "" Vector__XXX
 SG_ SCS_a052_ambientTempRationality : 51|1@1+ (1,0) [0|0] "" Vector__XXX
 SG_ SCS_a053_unexpectedThermalBehavi : 52|1@1+ (1,0) [0|0] "" Vector__XXX
 SG_ SCS_a054_pumpRegulation : 53|1@1+ (1,0) [0|0] "" Vector__XXX
 SG_ SCS_a055_coolantLevelLow : 54|1@1+ (1,0) [0|0] "" Vector__XXX
 SG_ SCS_a056_stateTransitionDenied : 55|1@1+ (1,0) [0|0] "" Vector__XXX
 SG_ SCS_a057_watchdogReset : 56|1@1+ (1,0) [0|0] "" Vector__XXX
 SG_ SCS_a058_adcRef : 57|1@1+ (1,0) [0|0] "" Vector__XXX
 SG_ SCS_a059_memoryError : 58|1@1+ (1,0) [0|0] "" Vector__XXX
 SG_ SCS_a060_swHVIL : 59|1@1+ (1,0) [0|0] "" Vector__XXX
 SG_ SCS_a061_postOutOfService : 60|1@1+ (1,0) [0|0] "" Vector__XXX
 SG_ SCS_a062_unused : 61|1@1+ (1,0) [0|0] "" Vector__XXX
 SG_ SCS_a063_canRationality : 62|1@1+ (1,0) [0|0] "" Vector__XXX
 SG_ SCS_a064_vehicleCommandTimeout : 63|1@1+ (1,0) [0|0] "" Vector__XXX

BO_ 870 CMPD_info: 12 Vector__XXX
 SG_ CMPD_infoIndex M : 0|8@1+ (1,0) [0|0] "" Vector__XXX
 SG_ CMPD_infoBootUdsProtoVersion m20 : 8|8@1+ (1,0) [0|0] "" Vector__XXX
 SG_ CMPD_infoBuildType m10 : 8|8@1+ (1,0) [0|0] "" Vector__XXX
 SG_ CMPD_infoPlatformType m13 : 8|8@1+ (1,0) [0|0] "" Vector__XXX
 SG_ CMPD_infoBuildConfigId m10 : 16|16@1+ (1,0) [0|0] "" Vector__XXX
 SG_ CMPD_infoPcbaId m11 : 16|8@1+ (1,0) [0|0] "" Vector__XXX
 SG_ CMPD_infoAssemblyId m11 : 24|8@1+ (1,0) [0|0] "" Vector__XXX
 SG_ CMPD_infoBootCrc m20 : 32|32@1+ (1,0) [0|0] "" Vector__XXX
 SG_ CMPD_infoHardwareId m10 : 32|16@1+ (1,0) [0|0] "" Vector__XXX
 SG_ CMPD_infoUsageId m11 : 32|16@1+ (1,0) [0|0] "" Vector__XXX
 SG_ CMPD_infoAppCrc m13 : 39|32@0+ (1,0) [0|0] "" Vector__XXX
 SG_ CMPD_infoComponentId m10 : 48|16@1+ (1,0) [0|0] "" Vector__XXX
 SG_ CMPD_infoSubUsageId m11 : 48|16@1+ (1,0) [0|0] "" Vector__XXX

BO_ 871 DI_alertMatrix1: 8 Vector__XXX
 SG_ DI_a001_frunkSpeedLimitActive : 0|1@1+ (1,0) [0|0] "" Vector__XXX
 SG_ DI_a002_parkButtonDuringStalkReq : 1|1@1+ (1,0) [0|0] "" Vector__XXX
 SG_ DI_a005_stalkPanicked : 4|1@1+ (1,0) [0|0] "" Vector__XXX
 SG_ DI_a010_unintendedReset : 9|1@1+ (1,0) [0|0] "" Vector__XXX
 SG_ DI_a012_accel5VSupply : 11|1@1+ (1,0) [0|0] "" Vector__XXX
 SG_ DI_a013_eccError : 12|1@1+ (1,0) [0|0] "" Vector__XXX
 SG_ DI_a015_immobilizer : 14|1@1+ (1,0) [0|0] "" Vector__XXX
 SG_ DI_a016_parkRequestByPM : 15|1@1+ (1,0) [0|0] "" Vector__XXX
 SG_ DI_a017_hwPedalMonitor : 16|1@1+ (1,0) [0|0] "" Vector__XXX
 SG_ DI_a018_hwLVSupplyUV : 17|1@1+ (1,0) [0|0] "" Vector__XXX
 SG_ DI_a019_hwAccelPedalPower : 18|1@1+ (1,0) [0|0] "" Vector__XXX
 SG_ DI_a021_packOvervoltage : 20|1@1+ (1,0) [0|0] "" Vector__XXX
 SG_ DI_a022_hw5vSupplyUV : 21|1@1+ (1,0) [0|0] "" Vector__XXX
 SG_ DI_a023_carNotParked : 22|1@1+ (1,0) [0|0] "" Vector__XXX
 SG_ DI_a024_holdNForNeutral : 23|1@1+ (1,0) [0|0] "" Vector__XXX
 SG_ DI_a025_regenBackfillUnavailable : 24|1@1+ (1,0) [0|0] "" Vector__XXX
 SG_ DI_a026_parkPressedWithHighAPedal : 25|1@1+ (1,0) [0|0] "" Vector__XXX
 SG_ DI_a027_steeringAngleOffsetService : 26|1@1+ (1,0) [0|0] "" Vector__XXX
 SG_ DI_a031_closureAccelerationLimit : 30|1@1+ (1,0) [0|0] "" Vector__XXX
 SG_ DI_a036_sysStandbyUnitLimitedWait : 35|1@1+ (1,0) [0|0] "" Vector__XXX
 SG_ DI_a040_difMIA : 39|1@1+ (1,0) [0|0] "" Vector__XXX
 SG_ DI_a041_driverBrakeApplyStuck : 40|1@1+ (1,0) [0|0] "" Vector__XXX
 SG_ DI_a042_pmfMIA : 41|1@1+ (1,0) [0|0] "" Vector__XXX
 SG_ DI_a043_pmrMIA : 42|1@1+ (1,0) [0|0] "" Vector__XXX
 SG_ DI_a048_ecuLogAvailable : 47|1@1+ (1,0) [0|0] "" Vector__XXX
 SG_ DI_a051_batteryOvercurrent : 50|1@1+ (1,0) [0|0] "" Vector__XXX
 SG_ DI_a052_dirMIA : 51|1@1+ (1,0) [0|0] "" Vector__XXX
 SG_ DI_a053_canDataBusC : 52|1@1+ (1,0) [0|0] "" Vector__XXX
 SG_ DI_a054_canOverrunBusC : 53|1@1+ (1,0) [0|0] "" Vector__XXX
 SG_ DI_a055_canHardwareBusC : 54|1@1+ (1,0) [0|0] "" Vector__XXX
 SG_ DI_a056_canDataBusD : 55|1@1+ (1,0) [0|0] "" Vector__XXX
 SG_ DI_a057_canOverrunBusD : 56|1@1+ (1,0) [0|0] "" Vector__XXX
 SG_ DI_a058_canHardwareBusD : 57|1@1+ (1,0) [0|0] "" Vector__XXX
 SG_ DI_a059_canDataBusE : 58|1@1+ (1,0) [0|0] "" Vector__XXX
 SG_ DI_a060_canOverrunBusE : 59|1@1+ (1,0) [0|0] "" Vector__XXX
 SG_ DI_a061_canHardwareBusE : 60|1@1+ (1,0) [0|0] "" Vector__XXX
 SG_ DI_a062_systemLimpMode : 61|1@1+ (1,0) [0|0] "" Vector__XXX
 SG_ DI_a063_systemGracefulPowerOff : 62|1@1+ (1,0) [0|0] "" Vector__XXX
 SG_ DI_a064_pmsrmUnitMiaWithHvDown : 63|1@1+ (1,0) [0|0] "" Vector__XXX

BO_ 872 DI_alertMatrix2: 8 Vector__XXX
 SG_ DI_a065_canHardwareBusB : 0|1@1+ (1,0) [0|0] "" Vector__XXX
 SG_ DI_a066_canDataBusB : 1|1@1+ (1,0) [0|0] "" Vector__XXX
 SG_ DI_a067_canOverrunBusB : 2|1@1+ (1,0) [0|0] "" Vector__XXX
 SG_ DI_a068_secondaryWheelSpeedIrrational : 3|1@1+ (1,0) [0|0] "" Vector__XXX
 SG_ DI_a070_udsTransactionInitiated : 5|1@1+ (1,0) [0|0] "" Vector__XXX
 SG_ DI_a074_unintendedResetAutoshift : 9|1@1+ (1,0) [0|0] "" Vector__XXX
 SG_ DI_a076_lvSupplyOV : 11|1@1+ (1,0) [0|0] "" Vector__XXX
 SG_ DI_a077_lvSupplyUV : 12|1@1+ (1,0) [0|0] "" Vector__XXX
 SG_ DI_a078_adcRefLow : 13|1@1+ (1,0) [0|0] "" Vector__XXX
 SG_ DI_a079_adcRefHigh : 14|1@1+ (1,0) [0|0] "" Vector__XXX
 SG_ DI_a080_accelSynch : 15|1@1+ (1,0) [0|0] "" Vector__XXX
 SG_ DI_a081_accelTrack1 : 16|1@1+ (1,0) [0|0] "" Vector__XXX
 SG_ DI_a082_accelTrack2 : 17|1@1+ (1,0) [0|0] "" Vector__XXX
 SG_ DI_a083_brakePedalSensor : 18|1@1+ (1,0) [0|0] "" Vector__XXX
 SG_ DI_a084_eccTestData0 : 19|1@1+ (1,0) [0|0] "" Vector__XXX
 SG_ DI_a085_proximityInEnable : 20|1@1+ (1,0) [0|0] "" Vector__XXX
 SG_ DI_a087_gtwMIA : 22|1@1+ (1,0) [0|0] "" Vector__XXX
 SG_ DI_a088_uiMIA : 23|1@1+ (1,0) [0|0] "" Vector__XXX
 SG_ DI_a089_sccmMIA : 24|1@1+ (1,0) [0|0] "" Vector__XXX
 SG_ DI_a090_pmMIA : 25|1@1+ (1,0) [0|0] "" Vector__XXX
 SG_ DI_a091_espMIA : 26|1@1+ (1,0) [0|0] "" Vector__XXX
 SG_ DI_a092_bmsMIA : 27|1@1+ (1,0) [0|0] "" Vector__XXX
 SG_ DI_a093_canHardwareBusA : 28|1@1+ (1,0) [0|0] "" Vector__XXX
 SG_ DI_a094_canDataBusA : 29|1@1+ (1,0) [0|0] "" Vector__XXX
 SG_ DI_a095_canOverrunBusA : 30|1@1+ (1,0) [0|0] "" Vector__XXX
 SG_ DI_a096_memoryError : 31|1@1+ (1,0) [0|0] "" Vector__XXX
 SG_ DI_a097_eepromError : 32|1@1+ (1,0) [0|0] "" Vector__XXX
 SG_ DI_a098_eepromManagerError : 33|1@1+ (1,0) [0|0] "" Vector__XXX
 SG_ DI_a099_threadOverrun : 34|1@1+ (1,0) [0|0] "" Vector__XXX
 SG_ DI_a100_nvramError : 35|1@1+ (1,0) [0|0] "" Vector__XXX
 SG_ DI_a101_eccTestData1 : 36|1@1+ (1,0) [0|0] "" Vector__XXX
 SG_ DI_a104_proximityIrrational : 39|1@1+ (1,0) [0|0] "" Vector__XXX
 SG_ DI_a105_cpMIA : 40|1@1+ (1,0) [0|0] "" Vector__XXX
 SG_ DI_a108_appMIA : 43|1@1+ (1,0) [0|0] "" Vector__XXX
 SG_ DI_a110_brakeMIA : 45|1@1+ (1,0) [0|0] "" Vector__XXX
 SG_ DI_a112_accelTrack1Incons : 47|1@1+ (1,0) [0|0] "" Vector__XXX
 SG_ DI_a113_lowBrakeMCPressure : 48|1@1+ (1,0) [0|0] "" Vector__XXX
 SG_ DI_a118_diImmobilizedForFactoryFailsafe : 53|1@1+ (1,0) [0|0] "" Vector__XXX
 SG_ DI_a122_highStackUsage : 57|1@1+ (1,0) [0|0] "" Vector__XXX
 SG_ DI_a124_cruiseFault : 59|1@1+ (1,0) [0|0] "" Vector__XXX
 SG_ DI_a125_noBatteryPower : 60|1@1+ (1,0) [0|0] "" Vector__XXX

BO_ 873 VCFRONT1_CPULoad: 8 Vector__XXX
 SG_ VCFRONT1_CPULoadTotal : 0|8@1+ (1,0) [0|0] "" Vector__XXX
 SG_ VCFRONT1_CPULoad1msTask : 8|8@1+ (1,0) [0|0] "" Vector__XXX
 SG_ VCFRONT1_CPULoad10msTask : 16|8@1+ (1,0) [0|0] "" Vector__XXX
 SG_ VCFRONT1_CPULoad100msTask : 24|8@1+ (1,0) [0|0] "" Vector__XXX
 SG_ VCFRONT1_CPULoad1000msTask : 32|8@1+ (1,0) [0|0] "" Vector__XXX

BO_ 875 DI_alertMatrix3: 8 Vector__XXX
 SG_ DI_a129_epbNotApplied : 0|1@1+ (1,0) [0|0] "" Vector__XXX
 SG_ DI_a130_aebFault : 1|1@1+ (1,0) [0|0] "" Vector__XXX
 SG_ DI_a131_highSpeedWearLimit : 2|1@1+ (1,0) [0|0] "" Vector__XXX
 SG_ DI_a133_vehicleHoldTimedOut : 4|1@1+ (1,0) [0|0] "" Vector__XXX
 SG_ DI_a134_wheelSpeedIrrational : 5|1@1+ (1,0) [0|0] "" Vector__XXX
 SG_ DI_a135_vehicleHoldFault : 6|1@1+ (1,0) [0|0] "" Vector__XXX
 SG_ DI_a137_noCapableDriveUnits : 8|1@1+ (1,0) [0|0] "" Vector__XXX
 SG_ DI_a138_frontUnitDisabled : 9|1@1+ (1,0) [0|0] "" Vector__XXX
 SG_ DI_a139_rearUnitDisabled : 10|1@1+ (1,0) [0|0] "" Vector__XXX
 SG_ DI_a140_ptcMIA : 11|1@1+ (1,0) [0|0] "" Vector__XXX
 SG_ DI_a141_dasMIA : 12|1@1+ (1,0) [0|0] "" Vector__XXX
 SG_ DI_a142_potholeDetected : 13|1@1+ (1,0) [0|0] "" Vector__XXX
 SG_ DI_a143_mcuLimitActive : 14|1@1+ (1,0) [0|0] "" Vector__XXX
 SG_ DI_a144_configMismatch : 15|1@1+ (1,0) [0|0] "" Vector__XXX
 SG_ DI_a146_pbrkPanicEpbFault : 17|1@1+ (1,0) [0|0] "" Vector__XXX
 SG_ DI_a154_vdcRearSteering : 25|1@1+ (1,0) [0|0] "" Vector__XXX
 SG_ DI_a155_vcfrontMIA : 26|1@1+ (1,0) [0|0] "" Vector__XXX
 SG_ DI_a157_rcmMIA : 28|1@1+ (1,0) [0|0] "" Vector__XXX
 SG_ DI_a158_ibstMIA : 29|1@1+ (1,0) [0|0] "" Vector__XXX
 SG_ DI_a159_cruiseSelfCheck : 30|1@1+ (1,0) [0|0] "" Vector__XXX
 SG_ DI_a160_fastLearnComplete : 31|1@1+ (1,0) [0|0] "" Vector__XXX
 SG_ DI_a161_epas3pMIA : 32|1@1+ (1,0) [0|0] "" Vector__XXX
 SG_ DI_a162_shiftDenied : 33|1@1+ (1,0) [0|0] "" Vector__XXX
 SG_ DI_a163_shiftMotorSpeed : 34|1@1+ (1,0) [0|0] "" Vector__XXX
 SG_ DI_a164_brakeOverride : 35|1@1+ (1,0) [0|0] "" Vector__XXX
 SG_ DI_a165_cruiseCancelled : 36|1@1+ (1,0) [0|0] "" Vector__XXX
 SG_ DI_a166_driverLeft : 37|1@1+ (1,0) [0|0] "" Vector__XXX
 SG_ DI_a167_keyNotAuthenticated : 38|1@1+ (1,0) [0|0] "" Vector__XXX
 SG_ DI_a168_proximityDriveDenial : 39|1@1+ (1,0) [0|0] "" Vector__XXX
 SG_ DI_a169_regenOffOverride : 40|1@1+ (1,0) [0|0] "" Vector__XXX
 SG_ DI_a170_tireConfigUpdated : 41|1@1+ (1,0) [0|0] "" Vector__XXX
 SG_ DI_a171_driveRailNotRequested : 42|1@1+ (1,0) [0|0] "" Vector__XXX
 SG_ DI_a172_accelPressedInNP : 43|1@1+ (1,0) [0|0] "" Vector__XXX
 SG_ DI_a173_bothPedalsPressed : 44|1@1+ (1,0) [0|0] "" Vector__XXX
 SG_ DI_a174_notOkToStartDrive : 45|1@1+ (1,0) [0|0] "" Vector__XXX
 SG_ DI_a175_crsNotAvailable : 46|1@1+ (1,0) [0|0] "" Vector__XXX
 SG_ DI_a176_EBRreleased : 47|1@1+ (1,0) [0|0] "" Vector__XXX
 SG_ DI_a177_tireFitmentChanged : 48|1@1+ (1,0) [0|0] "" Vector__XXX
 SG_ DI_a178_steeringAngleOffsetFault : 49|1@1+ (1,0) [0|0] "" Vector__XXX
 SG_ DI_a179_steeringAngleOffsetWarning : 50|1@1+ (1,0) [0|0] "" Vector__XXX
 SG_ DI_a180_crsSeatbeltUnbuckled : 51|1@1+ (1,0) [0|0] "" Vector__XXX
 SG_ DI_a181_rearMotorMode : 52|1@1+ (1,0) [0|0] "" Vector__XXX
 SG_ DI_a182_frontMotorMode : 53|1@1+ (1,0) [0|0] "" Vector__XXX
 SG_ DI_a183_holdReleaseRqrd : 54|1@1+ (1,0) [0|0] "" Vector__XXX
 SG_ DI_a184_autoparkCanceled : 55|1@1+ (1,0) [0|0] "" Vector__XXX
 SG_ DI_a185_autoparkAborted : 56|1@1+ (1,0) [0|0] "" Vector__XXX
 SG_ DI_a186_brakeStand : 57|1@1+ (1,0) [0|0] "" Vector__XXX
 SG_ DI_a187_pedalMisapplication : 58|1@1+ (1,0) [0|0] "" Vector__XXX
 SG_ DI_a188_tireRotationRecommendedGhosted : 59|1@1+ (1,0) [0|0] "" Vector__XXX
 SG_ DI_a189_garageShiftWithPedal : 60|1@1+ (1,0) [0|0] "" Vector__XXX
 SG_ DI_a190_tireRotationRecommended : 61|1@1+ (1,0) [0|0] "" Vector__XXX
 SG_ DI_a191_brakeShiftReq : 62|1@1+ (1,0) [0|0] "" Vector__XXX
 SG_ DI_a192_invalidOdometer : 63|1@1+ (1,0) [0|0] "" Vector__XXX

BO_ 878 DI_alertMatrix4: 8 Vector__XXX
 SG_ DI_a193_vdcBrakeTorqueFr : 0|1@1+ (1,0) [0|0] "" Vector__XXX
 SG_ DI_a194_vdcBrakeTorqueRe : 1|1@1+ (1,0) [0|0] "" Vector__XXX
 SG_ DI_a195_vdcEspSlipFr : 2|1@1+ (1,0) [0|0] "" Vector__XXX
 SG_ DI_a196_vdcEspSlipRe : 3|1@1+ (1,0) [0|0] "" Vector__XXX
 SG_ DI_a197_vdcEspWheelSaturations : 4|1@1+ (1,0) [0|0] "" Vector__XXX
 SG_ DI_a198_vdcEspMCPressAndSteering : 5|1@1+ (1,0) [0|0] "" Vector__XXX
 SG_ DI_a199_vdcFaulted : 6|1@1+ (1,0) [0|0] "" Vector__XXX
 SG_ DI_a200_vdcModelBasedPlausibility : 7|1@1+ (1,0) [0|0] "" Vector__XXX
 SG_ DI_a201_decelTorqueLimited : 8|1@1+ (1,0) [0|0] "" Vector__XXX
 SG_ DI_a202_excessHeatUnavailable : 9|1@1+ (1,0) [0|0] "" Vector__XXX
 SG_ DI_a203_TCReducedByADD : 10|1@1+ (1,0) [0|0] "" Vector__XXX
 SG_ DI_a204_vdcRcmLongitudinal : 11|1@1+ (1,0) [0|0] "" Vector__XXX
 SG_ DI_a205_vdcRcmLateral : 12|1@1+ (1,0) [0|0] "" Vector__XXX
 SG_ DI_a206_vdcRcmVertical : 13|1@1+ (1,0) [0|0] "" Vector__XXX
 SG_ DI_a207_vdcPowertrainTorque_dif : 14|1@1+ (1,0) [0|0] "" Vector__XXX
 SG_ DI_a208_vdcPowertrainTorque_dir : 15|1@1+ (1,0) [0|0] "" Vector__XXX
 SG_ DI_a210_vdcOtherControllerStates : 17|1@1+ (1,0) [0|0] "" Vector__XXX
 SG_ DI_a211_vdcMotorSpeed_dif : 18|1@1+ (1,0) [0|0] "" Vector__XXX
 SG_ DI_a212_vdcWheelRotations : 19|1@1+ (1,0) [0|0] "" Vector__XXX
 SG_ DI_a213_lowMuProbabilityChange : 20|1@1+ (1,0) [0|0] "" Vector__XXX
 SG_ DI_a214_vdcWheelSpeedFr : 21|1@1+ (1,0) [0|0] "" Vector__XXX
 SG_ DI_a215_vdcWheelSpeedRe : 22|1@1+ (1,0) [0|0] "" Vector__XXX
 SG_ DI_a216_vdcMBPAlmostTripped : 23|1@1+ (1,0) [0|0] "" Vector__XXX
 SG_ DI_a217_vdcOutputIrrational : 24|1@1+ (1,0) [0|0] "" Vector__XXX
 SG_ DI_a218_vdcOSPreControlActive : 25|1@1+ (1,0) [0|0] "" Vector__XXX
 SG_ DI_a219_vdcOversteerdMzActive : 26|1@1+ (1,0) [0|0] "" Vector__XXX
 SG_ DI_a220_vdcUndersteerDecelActive : 27|1@1+ (1,0) [0|0] "" Vector__XXX
 SG_ DI_a221_vdcUndersteerdMzActive : 28|1@1+ (1,0) [0|0] "" Vector__XXX
 SG_ DI_a222_vdcDisabled : 29|1@1+ (1,0) [0|0] "" Vector__XXX
 SG_ DI_a223_tractionControlDisabled : 30|1@1+ (1,0) [0|0] "" Vector__XXX
 SG_ DI_a224_brakeOverTemp : 31|1@1+ (1,0) [0|0] "" Vector__XXX
 SG_ DI_a226_sysStartConditionNotMet : 33|1@1+ (1,0) [0|0] "" Vector__XXX
 SG_ DI_a227_contactorsNotClosed : 34|1@1+ (1,0) [0|0] "" Vector__XXX
 SG_ DI_a228_brakeTempEstUnavailable : 35|1@1+ (1,0) [0|0] "" Vector__XXX
 SG_ DI_a230_cmpMIA : 37|1@1+ (1,0) [0|0] "" Vector__XXX
 SG_ DI_a231_softSystemLimpMode : 38|1@1+ (1,0) [0|0] "" Vector__XXX
 SG_ DI_a232_velocityEstimatorDegraded : 39|1@1+ (1,0) [0|0] "" Vector__XXX
 SG_ DI_a233_frontWheelImpactDetected : 40|1@1+ (1,0) [0|0] "" Vector__XXX
 SG_ DI_a235_trackModeActive : 42|1@1+ (1,0) [0|0] "" Vector__XXX
 SG_ DI_a236_tasMIA : 43|1@1+ (1,0) [0|0] "" Vector__XXX
 SG_ DI_a237_undersideAbuse : 44|1@1+ (1,0) [0|0] "" Vector__XXX
 SG_ DI_a238_secondaryCollisionMitigationActive : 45|1@1+ (1,0) [0|0] "" Vector__XXX
 SG_ DI_a239_neutralRequestByPM : 46|1@1+ (1,0) [0|0] "" Vector__XXX
 SG_ DI_a240_torqueSplitStuck : 47|1@1+ (1,0) [0|0] "" Vector__XXX
 SG_ DI_a241_vdcMotorSpeed_dir : 48|1@1+ (1,0) [0|0] "" Vector__XXX
 SG_ DI_a242_vdcTrailerSwayDetected : 49|1@1+ (1,0) [0|0] "" Vector__XXX
 SG_ DI_a244_vseRLSMassMismatch : 51|1@1+ (1,0) [0|0] "" Vector__XXX
 SG_ DI_a245_opdReducedWithoutEbr : 52|1@1+ (1,0) [0|0] "" Vector__XXX
 SG_ DI_a246_opdUnavailable : 53|1@1+ (1,0) [0|0] "" Vector__XXX
 SG_ DI_a248_vdcPreControlHighDynamicActive : 55|1@1+ (1,0) [0|0] "" Vector__XXX
 SG_ DI_a249_spinDownLearningInProgress : 56|1@1+ (1,0) [0|0] "" Vector__XXX
 SG_ DI_a250_tasSpeedLimitActive : 57|1@1+ (1,0) [0|0] "" Vector__XXX
 SG_ DI_a251_diPowerOnStateMismatch : 58|1@1+ (1,0) [0|0] "" Vector__XXX
 SG_ DI_a253_accelSynchWarn : 60|1@1+ (1,0) [0|0] "" Vector__XXX
 SG_ DI_a254_vehicleStuckDetected : 61|1@1+ (1,0) [0|0] "" Vector__XXX
 SG_ DI_a255_manualRecoveryMode : 62|1@1+ (1,0) [0|0] "" Vector__XXX

BO_ 880 SCS_alertMatrix2: 8 Vector__XXX
 SG_ SCS_a065_vBatRationalityStage1 : 0|1@1+ (1,0) [0|0] "" Vector__XXX
 SG_ SCS_a066_vBatRationalityStage2 : 1|1@1+ (1,0) [0|0] "" Vector__XXX
 SG_ SCS_a067_vBatRationalityStage3 : 2|1@1+ (1,0) [0|0] "" Vector__XXX
 SG_ SCS_a068_vBatRationalityStage4 : 3|1@1+ (1,0) [0|0] "" Vector__XXX
 SG_ SCS_a069_vStageRationalityV1 : 4|1@1+ (1,0) [0|0] "" Vector__XXX
 SG_ SCS_a070_vStageRationalityV2 : 5|1@1+ (1,0) [0|0] "" Vector__XXX
 SG_ SCS_a071_chargerMIA : 6|1@1+ (1,0) [0|0] "" Vector__XXX
 SG_ SCS_a072_gtwMIA : 7|1@1+ (1,0) [0|0] "" Vector__XXX
 SG_ SCS_a073_lccMIA : 8|1@1+ (1,0) [0|0] "" Vector__XXX
 SG_ SCS_a074_isoVDiffHi : 9|1@1+ (1,0) [0|0] "" Vector__XXX
 SG_ SCS_a075_unused75 : 10|1@1+ (1,0) [0|0] "" Vector__XXX
 SG_ SCS_a076_bmsMIA : 11|1@1+ (1,0) [0|0] "" Vector__XXX
 SG_ SCS_a077_unexpectedVbatBehavior : 12|1@1+ (1,0) [0|0] "" Vector__XXX
 SG_ SCS_a078_voltageMatchTimeout : 13|1@1+ (1,0) [0|0] "" Vector__XXX
 SG_ SCS_a079_unexpectedVbat : 14|1@1+ (1,0) [0|0] "" Vector__XXX
 SG_ SCS_a080_lccFaulted : 15|1@1+ (1,0) [0|0] "" Vector__XXX
 SG_ SCS_a081_rmsInputVoltageHigh : 16|1@1+ (1,0) [0|0] "" Vector__XXX
 SG_ SCS_a082_VbatUV : 17|1@1+ (1,0) [0|0] "" Vector__XXX
 SG_ SCS_a083_chargeCurrentLimited : 18|1@1+ (1,0) [0|0] "" Vector__XXX
 SG_ SCS_a084_unused84 : 19|1@1+ (1,0) [0|0] "" Vector__XXX
 SG_ SCS_a085_unused85 : 20|1@1+ (1,0) [0|0] "" Vector__XXX
 SG_ SCS_a086_lccResetDetected : 21|1@1+ (1,0) [0|0] "" Vector__XXX
 SG_ SCS_a087_posCordTempRationality : 22|1@1+ (1,0) [0|0] "" Vector__XXX
 SG_ SCS_a088_negCordTempRationality : 23|1@1+ (1,0) [0|0] "" Vector__XXX
 SG_ SCS_a089_posCordOT : 24|1@1+ (1,0) [0|0] "" Vector__XXX
 SG_ SCS_a090_negCordOT : 25|1@1+ (1,0) [0|0] "" Vector__XXX
 SG_ SCS_a091_voltageRiseDetection : 26|1@1+ (1,0) [0|0] "" Vector__XXX
 SG_ SCS_a092_cabEnableDeasserted : 27|1@1+ (1,0) [0|0] "" Vector__XXX
 SG_ SCS_a093_unused93 : 28|1@1+ (1,0) [0|0] "" Vector__XXX
 SG_ SCS_a094_unused94 : 29|1@1+ (1,0) [0|0] "" Vector__XXX
 SG_ SCS_a095_unused95 : 30|1@1+ (1,0) [0|0] "" Vector__XXX
 SG_ SCS_a096_unused96 : 31|1@1+ (1,0) [0|0] "" Vector__XXX
 SG_ SCS_a097_unused97 : 32|1@1+ (1,0) [0|0] "" Vector__XXX
 SG_ SCS_a098_unused98 : 33|1@1+ (1,0) [0|0] "" Vector__XXX
 SG_ SCS_a099_unused99 : 34|1@1+ (1,0) [0|0] "" Vector__XXX
 SG_ SCS_a100_unused100 : 35|1@1+ (1,0) [0|0] "" Vector__XXX
 SG_ SCS_a101_unused101 : 36|1@1+ (1,0) [0|0] "" Vector__XXX
 SG_ SCS_a102_unused102 : 37|1@1+ (1,0) [0|0] "" Vector__XXX
 SG_ SCS_a103_unused103 : 38|1@1+ (1,0) [0|0] "" Vector__XXX
 SG_ SCS_a104_unused104 : 39|1@1+ (1,0) [0|0] "" Vector__XXX
 SG_ SCS_a105_unused105 : 40|1@1+ (1,0) [0|0] "" Vector__XXX
 SG_ SCS_a106_unused106 : 41|1@1+ (1,0) [0|0] "" Vector__XXX
 SG_ SCS_a107_unused107 : 42|1@1+ (1,0) [0|0] "" Vector__XXX
 SG_ SCS_a108_unused108 : 43|1@1+ (1,0) [0|0] "" Vector__XXX
 SG_ SCS_a109_unused109 : 44|1@1+ (1,0) [0|0] "" Vector__XXX
 SG_ SCS_a110_unused110 : 45|1@1+ (1,0) [0|0] "" Vector__XXX
 SG_ SCS_a111_unused111 : 46|1@1+ (1,0) [0|0] "" Vector__XXX
 SG_ SCS_a112_unused112 : 47|1@1+ (1,0) [0|0] "" Vector__XXX
 SG_ SCS_a113_unused113 : 48|1@1+ (1,0) [0|0] "" Vector__XXX
 SG_ SCS_a114_unused114 : 49|1@1+ (1,0) [0|0] "" Vector__XXX
 SG_ SCS_a115_unused115 : 50|1@1+ (1,0) [0|0] "" Vector__XXX
 SG_ SCS_a116_unused116 : 51|1@1+ (1,0) [0|0] "" Vector__XXX
 SG_ SCS_a117_unused117 : 52|1@1+ (1,0) [0|0] "" Vector__XXX
 SG_ SCS_a118_unused118 : 53|1@1+ (1,0) [0|0] "" Vector__XXX
 SG_ SCS_a119_unused119 : 54|1@1+ (1,0) [0|0] "" Vector__XXX
 SG_ SCS_a120_unused120 : 55|1@1+ (1,0) [0|0] "" Vector__XXX
 SG_ SCS_a121_unused121 : 56|1@1+ (1,0) [0|0] "" Vector__XXX
 SG_ SCS_a122_unused122 : 57|1@1+ (1,0) [0|0] "" Vector__XXX
 SG_ SCS_a123_unused123 : 58|1@1+ (1,0) [0|0] "" Vector__XXX
 SG_ SCS_a124_unused124 : 59|1@1+ (1,0) [0|0] "" Vector__XXX
 SG_ SCS_a125_unused125 : 60|1@1+ (1,0) [0|0] "" Vector__XXX
 SG_ SCS_a126_unused126 : 61|1@1+ (1,0) [0|0] "" Vector__XXX
 SG_ SCS_a127_unused127 : 62|1@1+ (1,0) [0|0] "" Vector__XXX
 SG_ SCS_a128_unused128 : 63|1@1+ (1,0) [0|0] "" Vector__XXX

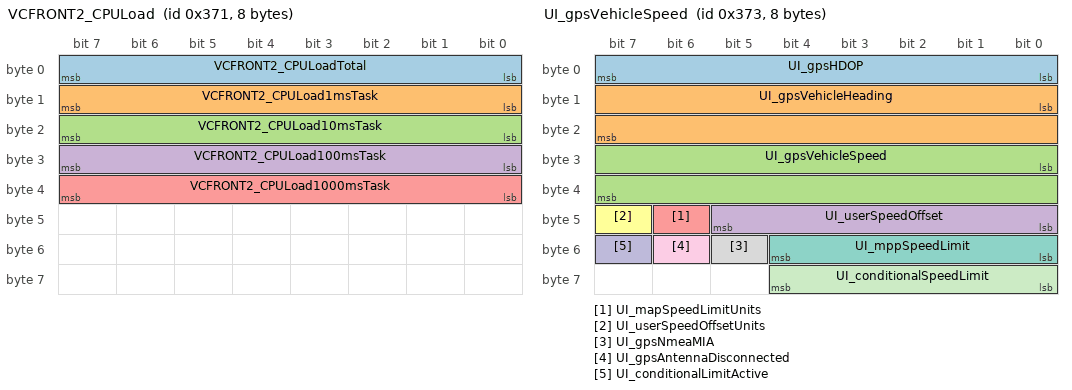
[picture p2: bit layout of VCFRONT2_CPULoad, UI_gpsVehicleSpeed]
BO_ 881 VCFRONT2_CPULoad: 8 Vector__XXX
 SG_ VCFRONT2_CPULoadTotal : 0|8@1+ (1,0) [0|0] "" Vector__XXX
 SG_ VCFRONT2_CPULoad1msTask : 8|8@1+ (1,0) [0|0] "" Vector__XXX
 SG_ VCFRONT2_CPULoad10msTask : 16|8@1+ (1,0) [0|0] "" Vector__XXX
 SG_ VCFRONT2_CPULoad100msTask : 24|8@1+ (1,0) [0|0] "" Vector__XXX
 SG_ VCFRONT2_CPULoad1000msTask : 32|8@1+ (1,0) [0|0] "" Vector__XXX

BO_ 882 BMS_log1: 8 Vector__XXX
 SG_ BMS_log1MuxId M : 0|8@1+ (1,0) [0|0] "" Vector__XXX
 SG_ BMS_1HzTask_cpuUsage m0 : 8|14@1+ (0.01,0) [0|0] "" Vector__XXX
 SG_ BMS_appIdleTask_cpuUsage m2 : 8|14@1+ (0.01,0) [0|0] "" Vector__XXX
 SG_ BMS_avgSleepCurrent m12 : 8|15@1- (0.2,0) [0|0] "" Vector__XXX
 SG_ BMS_balanceState m3 : 8|4@1+ (1,0) [0|0] "" Vector__XXX
 SG_ BMS_chgEndEvseChargeType m9 : 8|2@1+ (1,0) [0|0] "" Vector__XXX
 SG_ BMS_chgTerminationVMode m10 : 8|1@1+ (1,0) [0|0] "" Vector__XXX
 SG_ BMS_cpuLoad m1 : 8|14@1+ (0.01,0) [0|0] "" Vector__XXX
 SG_ BMS_dcChargeVoltageLimit m5 : 8|12@1+ (0.14650226075946277,0) [0|0] "" Vector__XXX
 SG_ BMS_energyMaxPredictedBrickTemp m13 : 8|8@1+ (1,-50) [0|0] "" Vector__XXX
 SG_ BMS_energyWalkMaxPackCurrent m14 : 8|16@1- (0.1,0) [0|0] "" Vector__XXX
 SG_ BMS_minModeledPackTemp m6 : 8|11@1+ (0.1,-50) [0|0] "" Vector__XXX
 SG_ BMS_modeledThermistorTemp1 m7 : 8|11@1+ (0.1,-50) [0|0] "" Vector__XXX
 SG_ BMS_modeledThermistorTemp6 m8 : 8|11@1+ (0.1,-50) [0|0] "" Vector__XXX
 SG_ BMS_packPower m11 : 8|16@1- (0.02,0) [0|0] "" Vector__XXX
 SG_ BMS_chgPhase m10 : 9|2@1+ (1,0) [0|0] "" Vector__XXX
 SG_ BMS_chgRequestTerminatedCount m9 : 10|4@1+ (1,0) [0|0] "" Vector__XXX
 SG_ BMS_hystRatio m10 : 11|10@1+ (0.001,0) [0|0] "" Vector__XXX
 SG_ BMS_vshTestNeeded m3 : 12|1@1+ (1,0) [0|0] "" Vector__XXX
 SG_ BMS_vshTestAllowed m3 : 13|1@1+ (1,0) [0|0] "" Vector__XXX
 SG_ BMS_vshFailure m3 : 14|1@1+ (1,0) [0|0] "" Vector__XXX
 SG_ BMS_fcCtrCleaningActiveNow m3 : 15|1@1+ (1,0) [0|0] "" Vector__XXX
 SG_ BMS_chgEndChargeState m9 : 16|4@1+ (1,0) [0|0] "" Vector__XXX
 SG_ BMS_energyTempGradientAtMaxTemp m13 : 16|9@1+ (0.1,0) [0|0] "" Vector__XXX
 SG_ BMS_pcsIsolatorEnabled m3 : 16|1@1+ (1,0) [0|0] "" Vector__XXX
 SG_ BMS_powerTransferStatus m4 : 16|4@1+ (1,0) [0|0] "" Vector__XXX
 SG_ BMS_pcsIsolatorSwitchGood m3 : 17|1@1+ (1,0) [0|0] "" Vector__XXX
 SG_ BMS_alphaState m3 : 18|3@1+ (1,0) [0|0] "" Vector__XXX
 SG_ BMS_maxModeledPackTemp m6 : 19|11@1+ (0.1,-50) [0|0] "" Vector__XXX
 SG_ BMS_modeledThermistorTemp2 m7 : 19|11@1+ (0.1,-50) [0|0] "" Vector__XXX
 SG_ BMS_modeledThermistorTemp7 m8 : 19|11@1+ (0.1,-50) [0|0] "" Vector__XXX
 SG_ BMS_chgEndBmsPowerTransferStatus m9 : 20|4@1+ (1,0) [0|0] "" Vector__XXX
 SG_ BMS_dcChargePowerLimit m5 : 20|12@1- (1,0) [0|0] "" Vector__XXX
 SG_ BMS_extDcPrechargeVoltageLimit m4 : 20|12@1+ (0.14650226075946277,0) [0|0] "" Vector__XXX
 SG_ BMS_hystRatioError m10 : 21|10@1+ (0.001,0) [0|0] "" Vector__XXX
 SG_ BMS_10HzTask_cpuUsage m0 : 22|14@1+ (0.01,0) [0|0] "" Vector__XXX
 SG_ BMS_cpuUsage_canRx m2 : 22|14@1+ (0.01,0) [0|0] "" Vector__XXX
 SG_ BMS_cpuUsage_vehTx m1 : 22|14@1+ (0.01,0) [0|0] "" Vector__XXX
 SG_ BMS_avgSleepPower m12 : 24|12@1+ (0.01,-40.95) [0|0] "" Vector__XXX
 SG_ BMS_chgEndCpPowerTransferStatus m9 : 24|3@1+ (1,0) [0|0] "" Vector__XXX
 SG_ BMS_energyWalkMaxVehiclePower m14 : 24|11@1- (1,500) [0|0] "" Vector__XXX
 SG_ BMS_feimState m3 : 24|4@1+ (1,0) [0|0] "" Vector__XXX
 SG_ BMS_maxOcvVsTempShift m11 : 24|13@1- (0.01,0) [0|0] "" Vector__XXX
 SG_ BMS_energyWalkMaxSoc m13 : 25|10@1+ (0.1,0) [0|0] "" Vector__XXX
 SG_ BMS_chgEndPcsPowerTransferStatus m9 : 27|2@1+ (1,0) [0|0] "" Vector__XXX
 SG_ BMS_bandoThmModelState m3 : 28|4@1+ (1,0) [0|0] "" Vector__XXX
 SG_ BMS_modeledThermistorTemp3 m7 : 30|11@1+ (0.1,-50) [0|0] "" Vector__XXX
 SG_ BMS_modeledThermistorTemp8 m8 : 30|11@1+ (0.1,-50) [0|0] "" Vector__XXX
 SG_ BMS_acRealPowerRequest m5 : 32|16@1- (0.002,0) [0|0] "" Vector__XXX
 SG_ BMS_avgModeledPackTemp m6 : 32|11@1+ (0.1,-50) [0|0] "" Vector__XXX
 SG_ BMS_chargeLimitReason_evseCurrentLimit m3 : 32|1@1+ (1,0) [0|0] "" Vector__XXX
 SG_ BMS_dcChargeCurrentRequest m4 : 32|14@1- (0.25,0) [0|0] "" Vector__XXX
 SG_ BMS_voltageRegState m10 : 32|2@1+ (1,0) [0|0] "" Vector__XXX
 SG_ BMS_chargeLimitReason_evseDeratingActive m3 : 33|1@1+ (1,0) [0|0] "" Vector__XXX
 SG_ BMS_chargeLimitReason_evsePowerLimit m3 : 34|1@1+ (1,0) [0|0] "" Vector__XXX
 SG_ BMS_chargeLimitReason_rampUpComplete m3 : 35|1@1+ (1,0) [0|0] "" Vector__XXX
 SG_ BMS_energyWalkMinSoc m13 : 35|10@1+ (0.1,0) [0|0] "" Vector__XXX
 SG_ BMS_gridFormCpState m14 : 35|4@1+ (1,0) [0|0] "" Vector__XXX
 SG_ BMS_100HzTask_cpuUsage m0 : 36|14@1+ (0.01,0) [0|0] "" Vector__XXX
 SG_ BMS_appNvramTask_cpuUsage m2 : 36|14@1+ (0.01,0) [0|0] "" Vector__XXX
 SG_ BMS_chargeLimitReason_socHigh m3 : 36|1@1+ (1,0) [0|0] "" Vector__XXX
 SG_ BMS_chgEndCpShutdownRequest m9 : 36|2@1+ (1,0) [0|0] "" Vector__XXX
 SG_ BMS_cpuUsage_hvsTx m1 : 36|14@1+ (0.01,0) [0|0] "" Vector__XXX
 SG_ BMS_chargeLimitReason_shadow m3 : 37|3@1+ (1,0) [0|0] "" Vector__XXX
 SG_ BMS_chgEndPcsShutdownRequest m9 : 38|2@1+ (1,0) [0|0] "" Vector__XXX
 SG_ BMS_battTempPct m14 : 40|8@1+ (0.4,0) [0|0] "" Vector__XXX
 SG_ BMS_chargeLimitReason_vehicleLimit m3 : 40|1@1+ (1,0) [0|0] "" Vector__XXX
 SG_ BMS_chgEndBatteryChargeRequest m9 : 40|1@1+ (1,0) [0|0] "" Vector__XXX
 SG_ BMS_estimatedEvsePower m10 : 40|16@1- (0.02,0) [0|0] "" Vector__XXX
 SG_ BMS_socMaxBrickId m11 : 40|8@1+ (1,1) [0|0] "" Vector__XXX
 SG_ BMS_chgEndDcEvseCompatible m9 : 41|1@1+ (1,0) [0|0] "" Vector__XXX
 SG_ BMS_modeledThermistorTemp4 m7 : 41|11@1+ (0.1,-50) [0|0] "" Vector__XXX
 SG_ BMS_modeledThermistorTemp9 m8 : 41|11@1+ (0.1,-50) [0|0] "" Vector__XXX
 SG_ BMS_chgEndDisableUnderFailure m9 : 42|1@1+ (1,0) [0|0] "" Vector__XXX
 SG_ BMS_modeledCoolantOutletTemp m6 : 43|11@1+ (0.1,-50) [0|0] "" Vector__XXX
 SG_ BMS_modeledMissingCellMaxTemp m9 : 43|11@1+ (0.1,-50) [0|0] "" Vector__XXX
 SG_ BMS_chargeEnergyWalkState m13 : 45|2@1+ (1,0) [0|0] "" Vector__XXX
 SG_ BMS_dcChargeCurrentLimit m4 : 46|13@1- (0.5,0) [0|0] "" Vector__XXX
 SG_ BMS_maxExtIsoFcLinkV m5 : 48|13@1+ (0.13429373702844585,0) [0|0] "" Vector__XXX
 SG_ BMS_packVoltage m13 : 48|16@1+ (0.01,0) [0|0] "" Vector__XXX
 SG_ BMS_socMinBrickId m11 : 48|8@1+ (1,1) [0|0] "" Vector__XXX
 SG_ BMS_1kHzTask_cpuUsage m0 : 50|14@1+ (0.01,0) [0|0] "" Vector__XXX
 SG_ BMS_cpuLoadRaw m2 : 50|14@1+ (0.01,0) [0|0] "" Vector__XXX
 SG_ BMS_cpuUsage_hviTx m1 : 50|14@1+ (0.01,0) [0|0] "" Vector__XXX
 SG_ BMS_modeledThermistorTemp10 m8 : 52|11@1+ (0.1,-50) [0|0] "" Vector__XXX
 SG_ BMS_modeledThermistorTemp5 m7 : 52|11@1+ (0.1,-50) [0|0] "" Vector__XXX
 SG_ BMS_maxModuleTempGradient m6 : 54|9@1+ (0.1,0) [0|0] "" Vector__XXX
 SG_ BMS_logChargeStatus m9 : 56|3@1+ (1,0) [0|0] "" Vector__XXX
 SG_ BMS_rippleHeatPowerDissipation m11 : 56|8@1+ (0.05,0) [0|0] "" Vector__XXX
 SG_ BMS_voltageRegulationBrickVTarget m10 : 56|8@1+ (0.01,2.5) [0|0] "" Vector__XXX
 SG_ BMS_chgEndShutdownReason m9 : 59|4@1+ (1,0) [0|0] "" Vector__XXX
 SG_ BMS_dcDischargeEnabled m4 : 59|1@1+ (1,0) [0|0] "" Vector__XXX
 SG_ BMS_rippleChargeRetryCount m4 : 60|3@1+ (1,0) [0|0] "" Vector__XXX

BO_ 883 UI_gpsVehicleSpeed: 8 Vector__XXX
 SG_ UI_gpsHDOP : 0|8@1+ (0.1,0) [0|0] "" Vector__XXX
 SG_ UI_gpsVehicleHeading : 8|16@1+ (0.0078125,0) [0|0] "" Vector__XXX
 SG_ UI_gpsVehicleSpeed : 24|16@1+ (0.00390625,0) [0|0] "" Vector__XXX
 SG_ UI_userSpeedOffset : 40|6@1+ (1,-30) [0|0] "" Vector__XXX
 SG_ UI_mapSpeedLimitUnits : 46|1@1+ (1,0) [0|0] "" Vector__XXX
 SG_ UI_userSpeedOffsetUnits : 47|1@1+ (1,0) [0|0] "" Vector__XXX
 SG_ UI_mppSpeedLimit : 48|5@1+ (5,0) [0|0] "" Vector__XXX
 SG_ UI_gpsNmeaMIA : 53|1@1+ (1,0) [0|0] "" Vector__XXX
 SG_ UI_gpsAntennaDisconnected : 54|1@1+ (1,0) [0|0] "" Vector__XXX
 SG_ UI_conditionalLimitActive : 55|1@1+ (1,0) [0|0] "" Vector__XXX
 SG_ UI_conditionalSpeedLimit : 56|5@1+ (5,0) [0|0] "" Vector__XXX

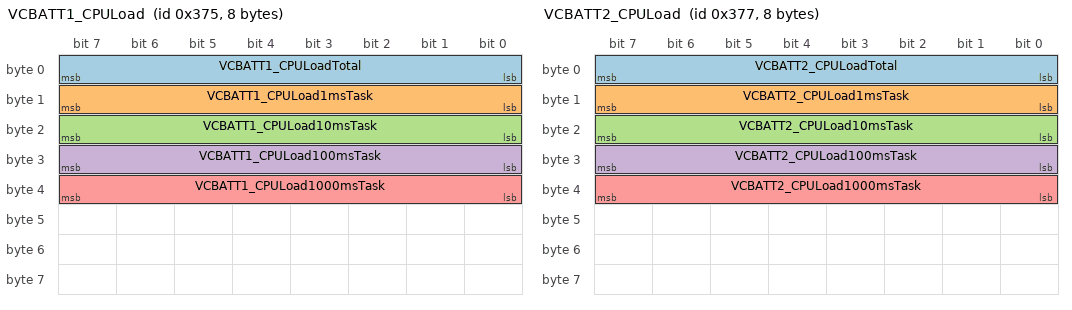
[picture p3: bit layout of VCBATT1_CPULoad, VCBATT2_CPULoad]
BO_ 885 VCBATT1_CPULoad: 8 Vector__XXX
 SG_ VCBATT1_CPULoadTotal : 0|8@1+ (1,0) [0|0] "" Vector__XXX
 SG_ VCBATT1_CPULoad1msTask : 8|8@1+ (1,0) [0|0] "" Vector__XXX
 SG_ VCBATT1_CPULoad10msTask : 16|8@1+ (1,0) [0|0] "" Vector__XXX
 SG_ VCBATT1_CPULoad100msTask : 24|8@1+ (1,0) [0|0] "" Vector__XXX
 SG_ VCBATT1_CPULoad1000msTask : 32|8@1+ (1,0) [0|0] "" Vector__XXX

BO_ 886 DIF_temperature: 8 Vector__XXX
 SG_ DIF_tempIndex M : 0|3@1+ (1,0) [0|0] "" Vector__XXX
 SG_ DIF_currentWeibullMiles m3 : 3|16@1+ (8,0) [0|0] "" Vector__XXX
 SG_ DIF_inverterTQF m0 : 3|2@1+ (1,0) [0|0] "" Vector__XXX
 SG_ DIF_fluidInTemp m2 : 8|8@1+ (1,-40) [0|0] "" Vector__XXX
 SG_ DIF_heatsink1Temp m1 : 8|8@1+ (1,-40) [0|0] "" Vector__XXX
 SG_ DIF_initialBurnInVehicleOdometer m4 : 8|32@1+ (0.001,0) [0|0] "" Vector__XXX
 SG_ DIF_pcbT m0 : 8|8@1+ (1,-40) [0|0] "" Vector__XXX
 SG_ DIF_heatsink2Temp m1 : 16|8@1+ (1,-40) [0|0] "" Vector__XXX
 SG_ DIF_inverterT m0 : 16|8@1+ (1,-40) [0|0] "" Vector__XXX
 SG_ DIF_normalFetBurnIn m2 : 16|16@1+ (0.00763,0) [0|0] "" Vector__XXX
 SG_ DIF_endOfServiceWeibullMiles m3 : 19|16@1+ (8,0) [0|0] "" Vector__XXX
 SG_ DIF_heatsink3Temp m1 : 24|8@1+ (1,-40) [0|0] "" Vector__XXX
 SG_ DIF_statorT m0 : 24|8@1+ (1,-40) [0|0] "" Vector__XXX
 SG_ DIF_additionalFetBurnIn m2 : 32|16@1+ (0.00763,0) [0|0] "" Vector__XXX
 SG_ DIF_dcCapT m0 : 32|8@1+ (1,-40) [0|0] "" Vector__XXX
 SG_ DIF_pcbTemp2 m1 : 32|8@1+ (1,-40) [0|0] "" Vector__XXX
 SG_ DIF_burnInDamageRatio m3 : 35|9@1+ (0.01,0) [0|0] "" Vector__XXX
 SG_ DIF_heatsinkT m0 : 40|8@1+ (1,-40) [0|0] "" Vector__XXX
 SG_ DIF_inverterHS2Est m4 : 40|8@1+ (1,-40) [0|0] "" Vector__XXX
 SG_ DIF_junctionTemp m1 : 40|8@1+ (1,-40) [0|0] "" Vector__XXX
 SG_ DIF_inverterSensorEst m3 : 44|8@1+ (1,-40) [0|0] "" Vector__XXX
 SG_ DIF_TPak1Temp m1 : 48|8@1+ (1,-40) [0|0] "" Vector__XXX
 SG_ DIF_inverterInletEst m4 : 48|8@1+ (1,-40) [0|0] "" Vector__XXX
 SG_ DIF_inverterTpct m0 : 48|8@1+ (0.4,0) [0|0] "" Vector__XXX
 SG_ DIF_inverterHS1Est m3 : 52|8@1+ (1,-40) [0|0] "" Vector__XXX
 SG_ DIF_TPak2Temp m1 : 56|8@1+ (1,-40) [0|0] "" Vector__XXX
 SG_ DIF_statorHousingTemp m4 : 56|8@1+ (1,-40) [0|0] "" Vector__XXX
 SG_ DIF_statorTpct m0 : 56|8@1+ (0.4,0) [0|0] "" Vector__XXX

BO_ 887 VCBATT2_CPULoad: 8 Vector__XXX
 SG_ VCBATT2_CPULoadTotal : 0|8@1+ (1,0) [0|0] "" Vector__XXX
 SG_ VCBATT2_CPULoad1msTask : 8|8@1+ (1,0) [0|0] "" Vector__XXX
 SG_ VCBATT2_CPULoad10msTask : 16|8@1+ (1,0) [0|0] "" Vector__XXX
 SG_ VCBATT2_CPULoad100msTask : 24|8@1+ (1,0) [0|0] "" Vector__XXX
 SG_ VCBATT2_CPULoad1000msTask : 32|8@1+ (1,0) [0|0] "" Vector__XXX

BO_ 889 VCSEC_BLERadioStatus: 8 Vector__XXX
 SG_ VCSEC_BLERadioStatusIndex M : 0|4@1+ (1,0) [0|0] "" Vector__XXX
 SG_ VCSEC_BLEDevicePacketCounter : 6|7@1+ (1,0) [0|0] "" Vector__XXX
 SG_ VCSEC_BLEAdvCounterC m7 : 13|16@1+ (1,0) [0|0] "" Vector__XXX
 SG_ VCSEC_BLEAdvStatusC m3 : 13|3@1+ (1,0) [0|0] "" Vector__XXX
 SG_ VCSEC_BLECPULoadC m3 : 16|7@1+ (1,0) [0|0] "" Vector__XXX
 SG_ VCSEC_BLECPULoadL m2 : 16|7@1+ (1,0) [0|0] "" Vector__XXX
 SG_ VCSEC_BLECPULoadRe m1 : 16|7@1+ (1,0) [0|0] "" Vector__XXX
 SG_ VCSEC_BLECPULoadRi m0 : 16|7@1+ (1,0) [0|0] "" Vector__XXX
 SG_ VCSEC_BLETimesScheduledL m6 : 16|8@1+ (1,0) [0|0] "" Vector__XXX
 SG_ VCSEC_BLETimesScheduledRe m5 : 16|8@1+ (1,0) [0|0] "" Vector__XXX
 SG_ VCSEC_BLETimesScheduledRi m4 : 16|8@1+ (1,0) [0|0] "" Vector__XXX
 SG_ VCSEC_totalEndpointNacksC m11 : 16|16@1+ (1,0) [0|0] "" Vector__XXX
 SG_ VCSEC_totalEndpointNacksL m10 : 16|16@1+ (1,0) [0|0] "" Vector__XXX
 SG_ VCSEC_totalEndpointNacksR m8 : 16|16@1+ (1,0) [0|0] "" Vector__XXX
 SG_ VCSEC_totalEndpointNacksRe m9 : 16|16@1+ (1,0) [0|0] "" Vector__XXX
 SG_ VCSEC_BLEHeapSizeC m3 : 24|14@1+ (1,0) [0|0] "" Vector__XXX
 SG_ VCSEC_BLEHeapSizeL m2 : 24|14@1+ (1,0) [0|0] "" Vector__XXX
 SG_ VCSEC_BLEHeapSizeRe m1 : 24|14@1+ (1,0) [0|0] "" Vector__XXX
 SG_ VCSEC_BLEHeapSizeRi m0 : 24|14@1+ (1,0) [0|0] "" Vector__XXX
 SG_ VCSEC_BLEPacketsReceivedL m6 : 24|8@1+ (1,0) [0|0] "" Vector__XXX
 SG_ VCSEC_BLEPacketsReceivedRe m5 : 24|8@1+ (1,0) [0|0] "" Vector__XXX
 SG_ VCSEC_BLEPacketsReceivedRi m4 : 24|8@1+ (1,0) [0|0] "" Vector__XXX
 SG_ VCSEC_BLERSSITrackingPercentC0 m7 : 32|4@1+ (8,0) [0|0] "" Vector__XXX
 SG_ VCSEC_BLEScheduleErrorsL m6 : 32|2@1+ (1,0) [0|0] "" Vector__XXX
 SG_ VCSEC_BLEScheduleErrorsRe m5 : 32|2@1+ (1,0) [0|0] "" Vector__XXX
 SG_ VCSEC_BLEScheduleErrorsRi m4 : 32|2@1+ (1,0) [0|0] "" Vector__XXX
 SG_ VCSEC_totalVCSECRetransmitsC m11 : 32|16@1+ (1,0) [0|0] "" Vector__XXX
 SG_ VCSEC_totalVCSECRetransmitsL m10 : 32|16@1+ (1,0) [0|0] "" Vector__XXX
 SG_ VCSEC_totalVCSECRetransmitsR m8 : 32|16@1+ (1,0) [0|0] "" Vector__XXX
 SG_ VCSEC_totalVCSECRetransmitsRe m9 : 32|16@1+ (1,0) [0|0] "" Vector__XXX
 SG_ VCSEC_BLEWhitelistEntriesL m6 : 34|4@1+ (1,0) [0|0] "" Vector__XXX
 SG_ VCSEC_BLEWhitelistEntriesRe m5 : 34|4@1+ (1,0) [0|0] "" Vector__XXX
 SG_ VCSEC_BLEWhitelistEntriesRi m4 : 34|4@1+ (1,0) [0|0] "" Vector__XXX
 SG_ VCSEC_BLERSSITrackingPercentC1 m7 : 36|4@1+ (8,0) [0|0] "" Vector__XXX
 SG_ VCSEC_BLENonWhitelistedScanEnabledL m6 : 38|1@1+ (1,0) [0|0] "" Vector__XXX
 SG_ VCSEC_BLENonWhitelistedScanEnabledRe m5 : 38|1@1+ (1,0) [0|0] "" Vector__XXX
 SG_ VCSEC_BLENonWhitelistedScanEnabledRi m4 : 38|1@1+ (1,0) [0|0] "" Vector__XXX
 SG_ VCSEC_connectionMonitorConnectionL0 m6 : 39|3@1+ (1,0) [0|0] "" Vector__XXX
 SG_ VCSEC_connectionMonitorConnectionRe0 m5 : 39|3@1+ (1,0) [0|0] "" Vector__XXX
 SG_ VCSEC_connectionMonitorConnectionRi0 m4 : 39|3@1+ (1,0) [0|0] "" Vector__XXX
 SG_ VCSEC_BLEHeapUsageC m3 : 40|7@1+ (1,0) [0|0] "" Vector__XXX
 SG_ VCSEC_BLEHeapUsageL m2 : 40|7@1+ (1,0) [0|0] "" Vector__XXX
 SG_ VCSEC_BLEHeapUsageRe m1 : 40|7@1+ (1,0) [0|0] "" Vector__XXX
 SG_ VCSEC_BLEHeapUsageRi m0 : 40|7@1+ (1,0) [0|0] "" Vector__XXX
 SG_ VCSEC_BLERSSITrackingPercentC2 m7 : 40|4@1+ (8,0) [0|0] "" Vector__XXX
 SG_ VCSEC_connectionMonitorConnectionL1 m6 : 42|3@1+ (1,0) [0|0] "" Vector__XXX
 SG_ VCSEC_connectionMonitorConnectionRe1 m5 : 42|3@1+ (1,0) [0|0] "" Vector__XXX
 SG_ VCSEC_connectionMonitorConnectionRi1 m4 : 42|3@1+ (1,0) [0|0] "" Vector__XXX
 SG_ VCSEC_BLENonWhitelistedScanEnabledC m7 : 44|1@1+ (1,0) [0|0] "" Vector__XXX
 SG_ VCSEC_BLEAdvPeriodC m7 : 45|11@1+ (1,0) [0|0] "" Vector__XXX
 SG_ VCSEC_connectionMonitorConnectionL2 m6 : 45|3@1+ (1,0) [0|0] "" Vector__XXX
 SG_ VCSEC_connectionMonitorConnectionRe2 m5 : 45|3@1+ (1,0) [0|0] "" Vector__XXX
 SG_ VCSEC_connectionMonitorConnectionRi2 m4 : 45|3@1+ (1,0) [0|0] "" Vector__XXX
 SG_ VCSEC_BLEHeapMaxUsageC m3 : 47|7@1+ (1,0) [0|0] "" Vector__XXX
 SG_ VCSEC_BLEHeapMaxUsageL m2 : 47|7@1+ (1,0) [0|0] "" Vector__XXX
 SG_ VCSEC_BLEHeapMaxUsageRe m1 : 47|7@1+ (1,0) [0|0] "" Vector__XXX
 SG_ VCSEC_BLEHeapMaxUsageRi m0 : 47|7@1+ (1,0) [0|0] "" Vector__XXX
 SG_ VCSEC_CMPeripheralMissingMatchL0 m6 : 48|8@1+ (1,0) [0|0] "" Vector__XXX
 SG_ VCSEC_CMPeripheralMissingMatchRe0 m5 : 48|8@1+ (1,0) [0|0] "" Vector__XXX
 SG_ VCSEC_CMPeripheralMissingMatchRi0 m4 : 48|8@1+ (1,0) [0|0] "" Vector__XXX
 SG_ VCSEC_queueSizeMaxC m11 : 48|8@1+ (1,0) [0|0] "" Vector__XXX
 SG_ VCSEC_queueSizeMaxL m10 : 48|8@1+ (1,0) [0|0] "" Vector__XXX
 SG_ VCSEC_queueSizeMaxR m8 : 48|8@1+ (1,0) [0|0] "" Vector__XXX
 SG_ VCSEC_queueSizeMaxRe m9 : 48|8@1+ (1,0) [0|0] "" Vector__XXX
 SG_ VCSEC_BLEGAPInitiatingConnectionC m7 : 56|1@1+ (1,0) [0|0] "" Vector__XXX
 SG_ VCSEC_CMPacketMatchL0 m6 : 56|8@1+ (1,0) [0|0] "" Vector__XXX
 SG_ VCSEC_CMPacketMatchRe0 m5 : 56|8@1+ (1,0) [0|0] "" Vector__XXX
 SG_ VCSEC_CMPacketMatchRi0 m4 : 56|8@1+ (1,0) [0|0] "" Vector__XXX
 SG_ VCSEC_queueLengthMaxC m11 : 56|8@1+ (1,0) [0|0] "" Vector__XXX
 SG_ VCSEC_queueLengthMaxL m10 : 56|8@1+ (1,0) [0|0] "" Vector__XXX
 SG_ VCSEC_queueLengthMaxR m8 : 56|8@1+ (1,0) [0|0] "" Vector__XXX
 SG_ VCSEC_queueLengthMaxRe m9 : 56|8@1+ (1,0) [0|0] "" Vector__XXX
 SG_ VCSEC_BLEGAPScanningC m7 : 57|1@1+ (1,0) [0|0] "" Vector__XXX
 SG_ VCSEC_BLEGAPAdvertisingC m7 : 58|1@1+ (1,0) [0|0] "" Vector__XXX

BO_ 890 VCSEC_ConnectionMonitor: 8 Vector__XXX
 SG_ VCSEC_BLEConnectionMonitorIndex M : 0|2@1+ (1,0) [0|0] "" Vector__XXX
 SG_ VCSEC_BLE0ConnInterval m3 : 2|10@1+ (1,0) [0|0] "" Vector__XXX
 SG_ VCSEC_BLERSSITrackingPercentL0 m2 : 4|4@1+ (8,0) [0|0] "" Vector__XXX
 SG_ VCSEC_BLERSSITrackingPercentR0 m0 : 4|4@1+ (8,0) [0|0] "" Vector__XXX
 SG_ VCSEC_BLERSSITrackingPercentRe0 m1 : 4|4@1+ (8,0) [0|0] "" Vector__XXX
 SG_ VCSEC_BLERSSITrackingPercentL1 m2 : 8|4@1+ (8,0) [0|0] "" Vector__XXX
 SG_ VCSEC_BLERSSITrackingPercentR1 m0 : 8|4@1+ (8,0) [0|0] "" Vector__XXX
 SG_ VCSEC_BLERSSITrackingPercentRe1 m1 : 8|4@1+ (8,0) [0|0] "" Vector__XXX
 SG_ VCSEC_BLE1ConnInterval m3 : 12|10@1+ (1,0) [0|0] "" Vector__XXX
 SG_ VCSEC_BLERSSITrackingPercentL2 m2 : 12|4@1+ (8,0) [0|0] "" Vector__XXX
 SG_ VCSEC_BLERSSITrackingPercentR2 m0 : 12|4@1+ (8,0) [0|0] "" Vector__XXX
 SG_ VCSEC_BLERSSITrackingPercentRe2 m1 : 12|4@1+ (8,0) [0|0] "" Vector__XXX
 SG_ VCSEC_CMEventNonEmptyPacketsL0 m2 : 16|8@1+ (1,0) [0|0] "" Vector__XXX
 SG_ VCSEC_CMEventNonEmptyPacketsR0 m1 : 16|8@1+ (1,0) [0|0] "" Vector__XXX
 SG_ VCSEC_CMEventNonEmptyPacketsRi0 m0 : 16|8@1+ (1,0) [0|0] "" Vector__XXX
 SG_ VCSEC_BLE2ConnInterval m3 : 22|10@1+ (1,0) [0|0] "" Vector__XXX
 SG_ VCSEC_CMEventSNNESNDeassertL0 m2 : 24|8@1+ (1,0) [0|0] "" Vector__XXX
 SG_ VCSEC_CMEventSNNESNDeassertR0 m1 : 24|8@1+ (1,0) [0|0] "" Vector__XXX
 SG_ VCSEC_CMEventSNNESNDeassertRi0 m0 : 24|8@1+ (1,0) [0|0] "" Vector__XXX
 SG_ VCSEC_CMEventNonMatchingPktCountL0 m2 : 32|8@1+ (1,0) [0|0] "" Vector__XXX
 SG_ VCSEC_CMEventNonMatchingPktCountR0 m1 : 32|8@1+ (1,0) [0|0] "" Vector__XXX
 SG_ VCSEC_CMEventNonMatchingPktCountRi0 m0 : 32|8@1+ (1,0) [0|0] "" Vector__XXX
 SG_ VCSEC_CMEventIncorrectChannelL0 m2 : 40|8@1+ (1,0) [0|0] "" Vector__XXX
 SG_ VCSEC_CMEventIncorrectChannelR0 m1 : 40|8@1+ (1,0) [0|0] "" Vector__XXX
 SG_ VCSEC_CMEventIncorrectChannelRi0 m0 : 40|8@1+ (1,0) [0|0] "" Vector__XXX
 SG_ VCSEC_CMEventOutsideWinL0 m2 : 48|8@1+ (1,0) [0|0] "" Vector__XXX
 SG_ VCSEC_CMEventOutsideWinR0 m1 : 48|8@1+ (1,0) [0|0] "" Vector__XXX
 SG_ VCSEC_CMEventOutsideWinRi0 m0 : 48|8@1+ (1,0) [0|0] "" Vector__XXX
 SG_ VCSEC_CMTimeSyncFailL0 m2 : 56|8@1+ (1,0) [0|0] "" Vector__XXX
 SG_ VCSEC_CMTimeSyncFailR0 m1 : 56|8@1+ (1,0) [0|0] "" Vector__XXX
 SG_ VCSEC_CMTimeSyncFailRi0 m0 : 56|8@1+ (1,0) [0|0] "" Vector__XXX

BO_ 893 CP_thermalStatus: 8 Vector__XXX
 SG_ CP_thermalStatusSelect M : 0|1@1+ (1,0) [0|0] "" Vector__XXX
 SG_ CP_dcPinTemperature m0 : 1|8@1+ (0.8039215686,-55) [0|0] "" Vector__XXX
 SG_ CP_pinTemperature1 m1 : 8|8@1+ (0.8039215686,-55) [0|0] "" Vector__XXX
 SG_ CP_dcPinTemperature2 m0 : 9|8@1+ (0.8039215686,-55) [0|0] "" Vector__XXX
 SG_ CP_pinTemperature2 m1 : 16|8@1+ (0.8039215686,-55) [0|0] "" Vector__XXX
 SG_ CP_acPinTemperature m0 : 17|8@1+ (0.8039215686,-55) [0|0] "" Vector__XXX
 SG_ CP_pinTemperature3 m1 : 24|8@1+ (0.8039215686,-55) [0|0] "" Vector__XXX
 SG_ CP_acPinTemperature2 m0 : 25|8@1+ (0.8039215686,-55) [0|0] "" Vector__XXX
 SG_ CP_pinTemperature4 m1 : 32|8@1+ (0.8039215686,-55) [0|0] "" Vector__XXX
 SG_ CP_pinTemp1Velocity m0 : 33|10@1- (0.15748,0) [0|0] "" Vector__XXX
 SG_ CP_pinTemp4Velocity m1 : 40|10@1- (0.15748,0) [0|0] "" Vector__XXX
 SG_ CP_pinTemp2Velocity m0 : 43|10@1- (0.15748,0) [0|0] "" Vector__XXX
 SG_ CP_pinTemp3Velocity m0 : 53|10@1- (0.15748,0) [0|0] "" Vector__XXX

BO_ 895 FC_alertMatrix3: 8 Vector__XXX
 SG_ FC_a129_CA_flyback_HW_OC : 0|1@1+ (1,0) [0|0] "" Vector__XXX
 SG_ FC_a130_CA_flyback_SW_OV : 1|1@1+ (1,0) [0|0] "" Vector__XXX
 SG_ FC_a131_CA_flyback_HW_OV : 2|1@1+ (1,0) [0|0] "" Vector__XXX
 SG_ FC_a132_CA_bmsMia : 3|1@1+ (1,0) [0|0] "" Vector__XXX
 SG_ FC_a133_CA_evseMia : 4|1@1+ (1,0) [0|0] "" Vector__XXX
 SG_ FC_a134_CA_vehTxBufOvf : 5|1@1+ (1,0) [0|0] "" Vector__XXX
 SG_ FC_a135_CA_vehRxBufOvf : 6|1@1+ (1,0) [0|0] "" Vector__XXX
 SG_ FC_a136_CA_evseTxBufOvf : 7|1@1+ (1,0) [0|0] "" Vector__XXX
 SG_ FC_a137_CA_evseRxBufOvf : 8|1@1+ (1,0) [0|0] "" Vector__XXX
 SG_ FC_a138_CA_hwProxTrip : 9|1@1+ (1,0) [0|0] "" Vector__XXX
 SG_ FC_a139_CA_ss2NotLow : 10|1@1+ (1,0) [0|0] "" Vector__XXX
 SG_ FC_a140_CA_bmsIncompatible : 11|1@1+ (1,0) [0|0] "" Vector__XXX
 SG_ FC_a141_CA_vehConn_OT : 12|1@1+ (1,0) [0|0] "" Vector__XXX
 SG_ FC_a142_CA_evseConn_OT : 13|1@1+ (1,0) [0|0] "" Vector__XXX
 SG_ FC_a143_CA_pcb_OT : 14|1@1+ (1,0) [0|0] "" Vector__XXX
 SG_ FC_a144_CA_flybackUnstable : 15|1@1+ (1,0) [0|0] "" Vector__XXX
 SG_ FC_a145_CA_flybackDataStale : 16|1@1+ (1,0) [0|0] "" Vector__XXX
 SG_ FC_a146_CA_flybackBusLoadHi : 17|1@1+ (1,0) [0|0] "" Vector__XXX
 SG_ FC_a147_CA_vehConn_UT : 18|1@1+ (1,0) [0|0] "" Vector__XXX
 SG_ FC_a148_CA_evseConn_UT : 19|1@1+ (1,0) [0|0] "" Vector__XXX
 SG_ FC_a149_CA_pcb_UT : 20|1@1+ (1,0) [0|0] "" Vector__XXX
 SG_ FC_a150_CA_vehToEvseDeltaHi : 21|1@1+ (1,0) [0|0] "" Vector__XXX
 SG_ FC_a151_CA_vehToEvseDeltaLo : 22|1@1+ (1,0) [0|0] "" Vector__XXX
 SG_ FC_a152_CA_vehToPcbDeltaHi : 23|1@1+ (1,0) [0|0] "" Vector__XXX
 SG_ FC_a153_CA_evseToPcbDeltaHi : 24|1@1+ (1,0) [0|0] "" Vector__XXX
 SG_ FC_a154_CA_vehToPcbDeltaLo : 25|1@1+ (1,0) [0|0] "" Vector__XXX
 SG_ FC_a155_CA_evseToPcbDeltaLo : 26|1@1+ (1,0) [0|0] "" Vector__XXX
 SG_ FC_a156_CA_flybackRunTimeout : 27|1@1+ (1,0) [0|0] "" Vector__XXX
 SG_ FC_a157_CA_unused : 28|1@1+ (1,0) [0|0] "" Vector__XXX
 SG_ FC_a158_CA_evseOverCurrent : 29|1@1+ (1,0) [0|0] "" Vector__XXX
 SG_ FC_a159_CA_wdtExpired : 30|1@1+ (1,0) [0|0] "" Vector__XXX
 SG_ FC_a160_CA_ss2Deasserted : 31|1@1+ (1,0) [0|0] "" Vector__XXX
 SG_ FC_a161_CA_vehTempHiFoldBk : 32|1@1+ (1,0) [0|0] "" Vector__XXX
 SG_ FC_a162_CA_evseTempHiFoldBk : 33|1@1+ (1,0) [0|0] "" Vector__XXX
 SG_ FC_a163_CA_pcbTempHiFoldBk : 34|1@1+ (1,0) [0|0] "" Vector__XXX
 SG_ FC_a164_CA_proxDisconnected : 35|1@1+ (1,0) [0|0] "" Vector__XXX
 SG_ FC_a165_CA_evseConnUnlocked : 36|1@1+ (1,0) [0|0] "" Vector__XXX
 SG_ FC_a166_CA_vehConnUnlocked : 37|1@1+ (1,0) [0|0] "" Vector__XXX
 SG_ FC_a167_CA_isoVoltageLow : 38|1@1+ (1,0) [0|0] "" Vector__XXX
 SG_ FC_a168_CA_proxTimeout : 39|1@1+ (1,0) [0|0] "" Vector__XXX
 SG_ FC_a169_CA_pilotAcceptTimeout : 40|1@1+ (1,0) [0|0] "" Vector__XXX
 SG_ FC_a170_CA_vehDataTimeout : 41|1@1+ (1,0) [0|0] "" Vector__XXX
 SG_ FC_a171_CA_vehConLockTimeout : 42|1@1+ (1,0) [0|0] "" Vector__XXX
 SG_ FC_a172_CA_ss2LowTimeout : 43|1@1+ (1,0) [0|0] "" Vector__XXX
 SG_ FC_a173_CA_evseDataTimeout : 44|1@1+ (1,0) [0|0] "" Vector__XXX
 SG_ FC_a174_CA_vehReadyTimeout : 45|1@1+ (1,0) [0|0] "" Vector__XXX
 SG_ FC_a175_CA_evseIsoTestTimeout : 46|1@1+ (1,0) [0|0] "" Vector__XXX
 SG_ FC_a176_CA_chargingBusTimeout : 47|1@1+ (1,0) [0|0] "" Vector__XXX
 SG_ FC_a177_CA_bmsCtrCloseTimeout : 48|1@1+ (1,0) [0|0] "" Vector__XXX
 SG_ FC_a178_CA_evseStartTimeout : 49|1@1+ (1,0) [0|0] "" Vector__XXX
 SG_ FC_a179_CA_startupProblem : 50|1@1+ (1,0) [0|0] "" Vector__XXX
 SG_ FC_a180_CA_chargingProblem : 51|1@1+ (1,0) [0|0] "" Vector__XXX
 SG_ FC_a181_CA_vRegBrownout : 52|1@1+ (1,0) [0|0] "" Vector__XXX
 SG_ FC_a182_CA_evseChrMalfunc : 53|1@1+ (1,0) [0|0] "" Vector__XXX
 SG_ FC_a183_CA_evseBatIncompat : 54|1@1+ (1,0) [0|0] "" Vector__XXX
 SG_ FC_a184_CA_evseBatMalfunc : 55|1@1+ (1,0) [0|0] "" Vector__XXX
 SG_ FC_a185_CA_vehReadyDeasserted : 56|1@1+ (1,0) [0|0] "" Vector__XXX
 SG_ FC_a186_CA_fcContOpenTimeout : 57|1@1+ (1,0) [0|0] "" Vector__XXX
 SG_ FC_a187_CA_evseConLockTimeout : 58|1@1+ (1,0) [0|0] "" Vector__XXX

BO_ 896 PM_alertMatrix2: 8 Vector__XXX
 SG_ PM_a066_pmfMIA : 1|1@1+ (1,0) [0|0] "" Vector__XXX
 SG_ PM_a067_pmrMIA : 2|1@1+ (1,0) [0|0] "" Vector__XXX
 SG_ PM_a080_exceptionPrefetchAbort : 15|1@1+ (1,0) [0|0] "" Vector__XXX
 SG_ PM_a081_exceptionDataAbort : 16|1@1+ (1,0) [0|0] "" Vector__XXX
 SG_ PM_a082_exceptionDataAbort2 : 17|1@1+ (1,0) [0|0] "" Vector__XXX
 SG_ PM_a083_ahbWriteError : 18|1@1+ (1,0) [0|0] "" Vector__XXX
 SG_ PM_a084_exceptionMpuFirewall : 19|1@1+ (1,0) [0|0] "" Vector__XXX
 SG_ PM_a086_exceptionUndefinedInstruction : 21|1@1+ (1,0) [0|0] "" Vector__XXX
 SG_ PM_a092_xtalOscillator : 27|1@1+ (1,0) [0|0] "" Vector__XXX
 SG_ PM_a093_accelPedalSupply : 28|1@1+ (1,0) [0|0] "" Vector__XXX
 SG_ PM_a095_ITPMSTimeoutGNSSConvergence : 30|1@1+ (1,0) [0|0] "" Vector__XXX
 SG_ PM_a096_ITPMSConvergedGNSSAbsRadiusTimes : 31|1@1+ (1,0) [0|0] "" Vector__XXX
 SG_ PM_a097_ITPMSRelativeCalibratedFactors : 32|1@1+ (1,0) [0|0] "" Vector__XXX
 SG_ PM_a098_ITPMSTriggerDebug : 33|1@1+ (1,0) [0|0] "" Vector__XXX
 SG_ PM_a099_ITPMSCalibrated : 34|1@1+ (1,0) [0|0] "" Vector__XXX
 SG_ PM_a100_diTraceInfo1 : 35|1@1+ (1,0) [0|0] "" Vector__XXX
 SG_ PM_a110_indirectTPMSPressureLossWarning : 45|1@1+ (1,0) [0|0] "" Vector__XXX
 SG_ PM_a111_unintendedResetCausedNeutral : 46|1@1+ (1,0) [0|0] "" Vector__XXX
 SG_ PM_a112_indirectTPMSPressureLossWarningHard : 47|1@1+ (1,0) [0|0] "" Vector__XXX
 SG_ PM_a113_btcMonitor : 48|1@1+ (1,0) [0|0] "" Vector__XXX
 SG_ PM_a115_indirectTPMSFaultedGhosted : 50|1@1+ (1,0) [0|0] "" Vector__XXX
 SG_ PM_a116_ITPMSBlowoutDetected : 51|1@1+ (1,0) [0|0] "" Vector__XXX
 SG_ PM_a117_ITPMSPermeabilityCalibrated : 52|1@1+ (1,0) [0|0] "" Vector__XXX
 SG_ PM_a120_indirectTPMSFaulted : 55|1@1+ (1,0) [0|0] "" Vector__XXX
 SG_ PM_a121_unintendedReset2 : 56|1@1+ (1,0) [0|0] "" Vector__XXX
 SG_ PM_a125_btcOutputIrrational : 60|1@1+ (1,0) [0|0] "" Vector__XXX

BO_ 897 VCFRONT_logging1Hz: 8 Vector__XXX
 SG_ VCFRONT_logging1HzIndex M : 0|5@1+ (1,0) [0|0] "" Vector__XXX
 SG_ VCFRONT_chillerExvCalibOffset m8 : 5|5@1- (8,0) [0|0] "" Vector__XXX
 SG_ VCFRONT_condenserPressureLimit m1 : 5|6@1+ (0.16,10) [0|0] "" Vector__XXX
 SG_ VCFRONT_coolantValveRecalReason m2 : 5|3@1+ (1,0) [0|0] "" Vector__XXX
 SG_ VCFRONT_espABSValveCurrent m20 : 5|4@1+ (0.1,0) [0|0] "" Vector__XXX
 SG_ VCFRONT_estPressureLiq m7 : 5|6@1+ (0.5,0) [0|0] "" Vector__XXX
 SG_ VCFRONT_exteriorQuietModeEnabled m6 : 5|1@1+ (1,0) [0|0] "" Vector__XXX
 SG_ VCFRONT_feedFwdMDotEvaporator m12 : 5|8@1+ (0.005,0) [0|0] "" Vector__XXX
 SG_ VCFRONT_frunkSwitch1Voltage m15 : 5|10@1+ (5,0) [0|0] "" Vector__XXX
 SG_ VCFRONT_homelinkRegionCode m3 : 5|4@1+ (1,0) [0|0] "" Vector__XXX
 SG_ VCFRONT_hpASBatteryHeatingAllowed m14 : 5|1@1+ (1,0) [0|0] "" Vector__XXX
 SG_ VCFRONT_hpChargeCableType m5 : 5|2@1+ (1,0) [0|0] "" Vector__XXX
 SG_ VCFRONT_hpForceScavenge m13 : 5|1@1+ (1,0) [0|0] "" Vector__XXX
 SG_ VCFRONT_leftFogLightCurrent m19 : 5|5@1+ (0.2,0) [0|0] "" Vector__XXX
 SG_ VCFRONT_louverPosReason m18 : 5|4@1+ (1,0) [0|0] "" Vector__XXX
 SG_ VCFRONT_modeTransitionID m0 : 5|6@1+ (1,0) [0|0] "" Vector__XXX
 SG_ VCFRONT_passiveSeriesRegOn m16 : 5|1@1+ (1,0) [0|0] "" Vector__XXX
 SG_ VCFRONT_radPassiveRejectEstimate m10 : 5|7@1+ (150,0) [0|0] "" Vector__XXX
 SG_ VCFRONT_superheatProtectionLimit m25 : 5|10@1+ (0.1,0) [0|0] "" Vector__XXX
 SG_ VCFRONT_tempSuperheatActFiltered m21 : 5|8@1- (0.25,26.5) [0|0] "" Vector__XXX
 SG_ VCFRONT_battOverStagUpperLimit m13 : 6|1@1+ (1,0) [0|0] "" Vector__XXX
 SG_ VCFRONT_exteriorQuietModeAllowed m6 : 6|1@1+ (1,0) [0|0] "" Vector__XXX
 SG_ VCFRONT_hpCOP1BatteryHeatingAllowed m14 : 6|1@1+ (1,0) [0|0] "" Vector__XXX
 SG_ VCFRONT_CCQdotFdFrwrdTarget m6 : 7|7@1+ (80,0) [0|0] "" Vector__XXX
 SG_ VCFRONT_battUnderStagUpperLimit m13 : 7|1@1+ (1,0) [0|0] "" Vector__XXX
 SG_ VCFRONT_hpCabinHeatScavengeOnly m14 : 7|1@1+ (1,0) [0|0] "" Vector__XXX
 SG_ VCFRONT_ambientColderThanBatt m13 : 8|1@1+ (1,0) [0|0] "" Vector__XXX
 SG_ VCFRONT_battDissipation m9 : 8|8@1+ (140,0) [0|0] "" Vector__XXX
 SG_ VCFRONT_chillerExvRange m4 : 8|8@1+ (7,0) [0|0] "" Vector__XXX
 SG_ VCFRONT_coolantValveCountRange m2 : 8|10@1+ (1,375) [0|0] "" Vector__XXX
 SG_ VCFRONT_debugWakeUp m22 : 8|32@1+ (1,0) [0|0] "" Vector__XXX
 SG_ VCFRONT_dischargePressureTarget m11 : 8|7@1+ (0.25,0) [0|0] "" Vector__XXX
 SG_ VCFRONT_hpCabinHeatAmbientSource m14 : 8|1@1+ (1,0) [0|0] "" Vector__XXX
 SG_ VCFRONT_hpColdStagnationLimit m17 : 8|7@1+ (1,-40) [0|0] "" Vector__XXX
 SG_ VCFRONT_hpDuctTargetLeft m26 : 8|7@1+ (1,0) [0|0] "" Vector__XXX
 SG_ VCFRONT_passiveDemandRadBypass m16 : 8|7@1+ (1,0) [0|0] "" Vector__XXX
 SG_ VCFRONT_subcoolActual m5 : 8|7@1- (0.4,15.2) [0|0] "" Vector__XXX
 SG_ VCFRONT_vcleftStaticBucketFill m23 : 8|5@1+ (40,0) [0|0] "" Vector__XXX
 SG_ VCFRONT_vcrightStaticBucketFill m24 : 8|5@1+ (40,0) [0|0] "" Vector__XXX
 SG_ VCFRONT_PCSCurrentFiltered m3 : 9|13@1- (0.1,0) [0|0] "" Vector__XXX
 SG_ VCFRONT_ambientSourcingAvailable m13 : 9|1@1+ (1,0) [0|0] "" Vector__XXX
 SG_ VCFRONT_difCurrent m20 : 9|7@1+ (0.05,0) [0|0] "" Vector__XXX
 SG_ VCFRONT_hpCabinHeatReheatScavenge m14 : 9|1@1+ (1,0) [0|0] "" Vector__XXX
 SG_ VCFRONT_hpEnergyFlowIndex m18 : 9|8@1+ (4,0) [0|0] "" Vector__XXX
 SG_ VCFRONT_evapExvCalibOffset m8 : 10|5@1- (8,0) [0|0] "" Vector__XXX
 SG_ VCFRONT_hpCabinHeatReheatAmbientSource m14 : 10|1@1+ (1,0) [0|0] "" Vector__XXX
 SG_ VCFRONT_hpMode m13 : 10|5@1+ (1,0) [0|0] "" Vector__XXX
 SG_ VCFRONT_rightFogLightCurrent m19 : 10|5@1+ (0.2,0) [0|0] "" Vector__XXX
 SG_ VCFRONT_estPressureSuct m7 : 11|7@1+ (0.125,0) [0|0] "" Vector__XXX
 SG_ VCFRONT_fanDemandCondenser m1 : 11|7@1+ (1,0) [0|0] "" Vector__XXX
 SG_ VCFRONT_hpCabinHeatBlend m14 : 11|1@1+ (1,0) [0|0] "" Vector__XXX
 SG_ VCFRONT_modeDesired m0 : 11|2@1+ (1,0) [0|0] "" Vector__XXX
 SG_ VCFRONT_hpCabinHeatCOP1 m14 : 12|1@1+ (1,0) [0|0] "" Vector__XXX
 SG_ VCFRONT_lccInletTempEstimate m10 : 12|8@1- (1,0) [0|0] "" Vector__XXX
 SG_ VCFRONT_hpCabinHeatBatteryHeatAmbSrc m12 : 13|1@1+ (1,0) [0|0] "" Vector__XXX
 SG_ VCFRONT_hpCabinHeatBatteryHeatReheatAmbSrc m14 : 13|1@1+ (1,0) [0|0] "" Vector__XXX
 SG_ VCFRONT_targetPTActiveCool m0 : 13|7@1+ (1,0) [0|0] "" Vector__XXX
 SG_ VCFRONT_tempRefrigDischarge m21 : 13|11@1+ (0.125,-40) [0|0] "" Vector__XXX
 SG_ VCFRONT_vcleftStaticBucketFill0 m23 : 13|5@1+ (40,0) [0|0] "" Vector__XXX
 SG_ VCFRONT_vcrightStaticBucketFill0 m24 : 13|5@1+ (40,0) [0|0] "" Vector__XXX
 SG_ VCFRONT_CCQdotFdbk m6 : 14|7@1- (80,0) [0|0] "" Vector__XXX
 SG_ VCFRONT_hpCabinHeatBatteryCoolReheat m14 : 14|1@1+ (1,0) [0|0] "" Vector__XXX
 SG_ VCFRONT_hpCabinHeatBatteryHeatCOP1 m12 : 14|1@1+ (1,0) [0|0] "" Vector__XXX
 SG_ VCFRONT_battLoopWorthCooling m13 : 15|1@1+ (1,0) [0|0] "" Vector__XXX
 SG_ VCFRONT_evapDisabledLowPsCutout m11 : 15|1@1+ (1,0) [0|0] "" Vector__XXX
 SG_ VCFRONT_feedFwdMDotCabinCondenser m12 : 15|8@1+ (0.005,0) [0|0] "" Vector__XXX
 SG_ VCFRONT_frunkSwitch2Voltage m15 : 15|10@1+ (5,0) [0|0] "" Vector__XXX
 SG_ VCFRONT_hpCabinCoolEvaporator m14 : 15|1@1+ (1,0) [0|0] "" Vector__XXX
 SG_ VCFRONT_recircExvCalibOffset m8 : 15|5@1- (8,0) [0|0] "" Vector__XXX
 SG_ VCFRONT_sideMarkersCurrent m19 : 15|5@1+ (0.2,0) [0|0] "" Vector__XXX
 SG_ VCFRONT_chillerDemandWatts m25 : 16|8@1+ (100,0) [0|0] "" Vector__XXX
 SG_ VCFRONT_diDissipation m9 : 16|8@1+ (80,0) [0|0] "" Vector__XXX
 SG_ VCFRONT_difDischargeCurrent m20 : 16|5@1+ (0.05,0) [0|0] "" Vector__XXX
 SG_ VCFRONT_evapExvRange m4 : 16|8@1+ (7,0) [0|0] "" Vector__XXX
 SG_ VCFRONT_hpCabinCoolEvaporatorReheat m14 : 16|1@1+ (1,0) [0|0] "" Vector__XXX
 SG_ VCFRONT_hpDuctTargetRight m26 : 16|7@1+ (1,0) [0|0] "" Vector__XXX
 SG_ VCFRONT_hpHotStagnationLimit m17 : 16|7@1+ (1,-40) [0|0] "" Vector__XXX
 SG_ VCFRONT_hpSubcoolTarget m5 : 16|5@1+ (1,0) [0|0] "" Vector__XXX
 SG_ VCFRONT_minFlowPDCont m11 : 16|8@1+ (0.5,0) [0|0] "" Vector__XXX
 SG_ VCFRONT_ptLoopWorthCooling m13 : 16|1@1+ (1,0) [0|0] "" Vector__XXX
 SG_ VCFRONT_targetLccActiveCoolCap m16 : 16|7@1+ (1,0) [0|0] "" Vector__XXX
 SG_ VCFRONT_estCompRefrigMassflow m13 : 17|6@1+ (4,0) [0|0] "" Vector__XXX
 SG_ VCFRONT_hpBatteryHeatAmbientSource m14 : 17|1@1+ (1,0) [0|0] "" Vector__XXX
 SG_ VCFRONT_hpEnergyFlowIndexFiltered m18 : 17|8@1+ (4,0) [0|0] "" Vector__XXX
 SG_ VCFRONT_coolantValveAngleDrift m2 : 18|10@1+ (0.25,-127) [0|0] "" Vector__XXX
 SG_ VCFRONT_estPressureDisch m7 : 18|7@1+ (0.25,0) [0|0] "" Vector__XXX
 SG_ VCFRONT_fanDemandRadiator m1 : 18|7@1+ (1,0) [0|0] "" Vector__XXX
 SG_ VCFRONT_hpBatteryHeatCOP1 m14 : 18|1@1+ (1,0) [0|0] "" Vector__XXX
 SG_ VCFRONT_vcleftStaticBucketFill1 m23 : 18|5@1+ (40,0) [0|0] "" Vector__XXX
 SG_ VCFRONT_vcrightStaticBucketFill1 m24 : 18|5@1+ (40,0) [0|0] "" Vector__XXX
 SG_ VCFRONT_hpBatteryCool m14 : 19|1@1+ (1,0) [0|0] "" Vector__XXX
 SG_ VCFRONT_chillerInletTempEstimate m10 : 20|8@1- (1,0) [0|0] "" Vector__XXX
 SG_ VCFRONT_hpBatteryCoolCabinCondenserCD m14 : 20|1@1+ (1,0) [0|0] "" Vector__XXX
 SG_ VCFRONT_lccExvCalibOffset m8 : 20|5@1- (8,0) [0|0] "" Vector__XXX
 SG_ VCFRONT_leftSideRepeaterCurrent m19 : 20|8@1+ (0.062,0) [0|0] "" Vector__XXX
 SG_ VCFRONT_targetPtOptionalActiveCool m0 : 20|7@1+ (1,0) [0|0] "" Vector__XXX
 SG_ VCFRONT_CCQdotActual m6 : 21|7@1+ (80,0) [0|0] "" Vector__XXX
 SG_ VCFRONT_CMPDischargeSuperheat m5 : 21|5@1- (1,6) [0|0] "" Vector__XXX
 SG_ VCFRONT_frontOilPumpCurrent m20 : 21|9@1+ (0.047,0) [0|0] "" Vector__XXX
 SG_ VCFRONT_hpBatteryCoolCabinCondenserHD m14 : 21|1@1+ (1,0) [0|0] "" Vector__XXX
 SG_ VCFRONT_hpBatteryCoolCabinReheat m14 : 22|1@1+ (1,0) [0|0] "" Vector__XXX
 SG_ VCFRONT_radInletTempEstimate m3 : 22|8@1- (1,0) [0|0] "" Vector__XXX
 SG_ VCFRONT_feedBackEvapTempController m12 : 23|7@1+ (0.01,-0.5) [0|0] "" Vector__XXX
 SG_ VCFRONT_hpBatteryCoolEvaporator m14 : 23|1@1+ (1,0) [0|0] "" Vector__XXX
 SG_ VCFRONT_hpCompFlowIndex m17 : 23|8@1+ (1,30) [0|0] "" Vector__XXX
 SG_ VCFRONT_pressureRefrigDischEst m13 : 23|5@1+ (1,0) [0|0] "" Vector__XXX
 SG_ VCFRONT_targetLccActiveCoolEff m16 : 23|7@1+ (1,0) [0|0] "" Vector__XXX
 SG_ VCFRONT_vcleftStaticBucketFill2 m23 : 23|5@1+ (40,0) [0|0] "" Vector__XXX
 SG_ VCFRONT_vcrightStaticBucketFill2 m24 : 23|5@1+ (40,0) [0|0] "" Vector__XXX
 SG_ VCFRONT_PDischargeControllerOutput m11 : 24|8@1+ (0.5,0) [0|0] "" Vector__XXX
 SG_ VCFRONT_chillerPassiveCoolPower m9 : 24|8@1- (60,7560) [0|0] "" Vector__XXX
 SG_ VCFRONT_nominalTevapHWLimit m25 : 24|7@1+ (0.5,0) [0|0] "" Vector__XXX
 SG_ VCFRONT_pumpBatteryRPMTarget m21 : 24|8@1+ (30,0) [0|0] "" Vector__XXX
 SG_ VCFRONT_radiatorUAIndex m26 : 24|8@1+ (1,0) [0|0] "" Vector__XXX
 SG_ VCFRONT_recircExvRange m4 : 24|8@1+ (7,0) [0|0] "" Vector__XXX
 SG_ VCFRONT_suctionSuperheatEstTsSNA m14 : 24|4@1+ (2,0) [0|0] "" Vector__XXX
 SG_ VCFRONT_ccLeftExvCalibOffset m8 : 25|5@1- (8,0) [0|0] "" Vector__XXX
 SG_ VCFRONT_ductLeftAtSS m18 : 25|1@1+ (1,0) [0|0] "" Vector__XXX
 SG_ VCFRONT_estTempLiq m7 : 25|8@1- (0.8,68.8) [0|0] "" Vector__XXX
 SG_ VCFRONT_frunkSensorWindowActive m15 : 25|1@1+ (1,0) [0|0] "" Vector__XXX
 SG_ VCFRONT_tempRefrigSuction m1 : 25|8@1+ (0.5,-40) [0|0] "" Vector__XXX
 SG_ VCFRONT_correctedLowSideTemperature m15 : 26|8@1- (0.7874015748031497,10.236220472440946) [0|0] "" Vector__XXX
 SG_ VCFRONT_ductRightAtSS m18 : 26|1@1+ (1,0) [0|0] "" Vector__XXX
 SG_ VCFRONT_hpCOP m5 : 26|6@1+ (0.1,0) [0|0] "" Vector__XXX
 SG_ VCFRONT_minCompressorRPMAllowed m18 : 27|7@1+ (90,0) [0|0] "" Vector__XXX
 SG_ VCFRONT_targetPTPassive m0 : 27|7@1+ (1,-20) [0|0] "" Vector__XXX
 SG_ VCFRONT_coolantValveRecalCount m2 : 28|16@1+ (1,0) [0|0] "" Vector__XXX
 SG_ VCFRONT_evapFdFrwrdTarget m6 : 28|7@1+ (80,0) [0|0] "" Vector__XXX
 SG_ VCFRONT_feedFwdFanDemand m10 : 28|7@1+ (1,0) [0|0] "" Vector__XXX
 SG_ VCFRONT_rightSideRepeaterCurrent m19 : 28|8@1+ (0.062,0) [0|0] "" Vector__XXX
 SG_ VCFRONT_tempRefrigDischargeEst m13 : 28|6@1+ (1.5,46) [0|0] "" Vector__XXX
 SG_ VCFRONT_tempRefrigSuctionEst m14 : 28|6@1- (1.2,7.2) [0|0] "" Vector__XXX
 SG_ VCFRONT_vcleftStaticBucketFill3 m23 : 28|5@1+ (40,0) [0|0] "" Vector__XXX
 SG_ VCFRONT_vcrightStaticBucketFill3 m24 : 28|5@1+ (40,0) [0|0] "" Vector__XXX
 SG_ VCFRONT_ccRightExvCalibOffset m8 : 30|5@1- (8,0) [0|0] "" Vector__XXX
 SG_ VCFRONT_coolantValveCurrent m20 : 30|6@1+ (0.5,0) [0|0] "" Vector__XXX
 SG_ VCFRONT_coolantValveDailyAngleTravel m16 : 30|7@1+ (60,0) [0|0] "" Vector__XXX
 SG_ VCFRONT_feedBackDuctTempController m12 : 30|8@1+ (0.01,-1) [0|0] "" Vector__XXX
 SG_ VCFRONT_radiatorSteamDetectionState m3 : 30|3@1+ (1,0) [0|0] "" Vector__XXX
 SG_ VCFRONT_battCoolEvapEnableDelay m25 : 31|1@1+ (1,0) [0|0] "" Vector__XXX
 SG_ VCFRONT_hpCompFlowIndexFiltered m17 : 31|8@1+ (1,30) [0|0] "" Vector__XXX
 SG_ VCFRONT_ambientTempState m25 : 32|2@1+ (1,0) [0|0] "" Vector__XXX
 SG_ VCFRONT_lccExvRange m4 : 32|8@1+ (7,0) [0|0] "" Vector__XXX
 SG_ VCFRONT_lccPassiveHeatPower m9 : 32|8@1+ (60,0) [0|0] "" Vector__XXX
 SG_ VCFRONT_lowSideWattsLift m5 : 32|7@1+ (60,0) [0|0] "" Vector__XXX
 SG_ VCFRONT_pumpPowertrainRPMTarget m21 : 32|8@1+ (30,0) [0|0] "" Vector__XXX
 SG_ VCFRONT_suctionPressureTarget m11 : 32|6@1+ (0.15,0) [0|0] "" Vector__XXX
 SG_ VCFRONT_estTempSuct m7 : 33|6@1- (1,2) [0|0] "" Vector__XXX
 SG_ VCFRONT_hcmlSelectedBinningMethod m3 : 33|2@1+ (1,0) [0|0] "" Vector__XXX
 SG_ VCFRONT_pumpBatteryFETTemp m1 : 33|8@1+ (1,-40) [0|0] "" Vector__XXX
 SG_ VCFRONT_vcleftDynamicBucketFill m23 : 33|5@1+ (40,0) [0|0] "" Vector__XXX
 SG_ VCFRONT_vcrightDynamicBucketFill m24 : 33|5@1+ (40,0) [0|0] "" Vector__XXX
 SG_ VCFRONT_ambientTempUnlatchReason m25 : 34|3@1+ (1,0) [0|0] "" Vector__XXX
 SG_ VCFRONT_ccRefrigerantMassFlow m18 : 34|6@1+ (4,0) [0|0] "" Vector__XXX
 SG_ VCFRONT_estCompPower m13 : 34|9@1+ (20,0) [0|0] "" Vector__XXX
 SG_ VCFRONT_hpBattOverTempHvacDisable m14 : 34|1@1+ (1,0) [0|0] "" Vector__XXX
 SG_ VCFRONT_mdotAirRadiator m15 : 34|7@1+ (0.031496062992125984,0) [0|0] "" Vector__XXX
 SG_ VCFRONT_targetBatActiveCool m0 : 34|7@1+ (1,0) [0|0] "" Vector__XXX
 SG_ VCFRONT_chillerEXVControlState m8 : 35|3@1+ (1,0) [0|0] "" Vector__XXX
 SG_ VCFRONT_evapFdbk m6 : 35|7@1- (100,-3300) [0|0] "" Vector__XXX
 SG_ VCFRONT_feedFwdPumpDemand m10 : 35|7@1+ (1,0) [0|0] "" Vector__XXX
 SG_ VCFRONT_hcmrSelectedBinningMethod m3 : 35|2@1+ (1,0) [0|0] "" Vector__XXX
 SG_ VCFRONT_hpDiagLouverCalib m14 : 35|1@1+ (1,0) [0|0] "" Vector__XXX
 SG_ VCFRONT_frunkLEDCurrent m19 : 36|4@1+ (0.01,0) [0|0] "" Vector__XXX
 SG_ VCFRONT_hpDiagHighSideNotNominal m14 : 36|1@1+ (1,0) [0|0] "" Vector__XXX
 SG_ VCFRONT_windshieldWiperCurrent m20 : 36|6@1+ (1,0) [0|0] "" Vector__XXX
 SG_ VCFRONT_coolantPurgeMinutesRun m3 : 37|6@1+ (1,0) [0|0] "" Vector__XXX
 SG_ VCFRONT_dischargePressureLimit m16 : 37|7@1+ (0.25,0) [0|0] "" Vector__XXX
 SG_ VCFRONT_hpForceModeRadClear m14 : 37|1@1+ (1,0) [0|0] "" Vector__XXX
 SG_ VCFRONT_ambientSourcingDisabled m11 : 38|1@1+ (1,0) [0|0] "" Vector__XXX
 SG_ VCFRONT_estPressureDischargeSat m14 : 38|7@1+ (0.25,0) [0|0] "" Vector__XXX
 SG_ VCFRONT_evapEXVControlState m8 : 38|3@1+ (1,0) [0|0] "" Vector__XXX
 SG_ VCFRONT_isSolenoidAllowed m12 : 38|1@1+ (1,0) [0|0] "" Vector__XXX
 SG_ VCFRONT_vcleftDynamicBucketFill0 m23 : 38|5@1+ (40,0) [0|0] "" Vector__XXX
 SG_ VCFRONT_vcrightDynamicBucketFill0 m24 : 38|5@1+ (40,0) [0|0] "" Vector__XXX
 SG_ VCFRONT_chillerLiftDisabledLowPs m11 : 39|1@1+ (1,0) [0|0] "" Vector__XXX
 SG_ VCFRONT_estTempDisch m7 : 39|7@1- (1.5,75) [0|0] "" Vector__XXX
 SG_ VCFRONT_maxChillerCoolingPower m12 : 39|8@1+ (100,0) [0|0] "" Vector__XXX
 SG_ VCFRONT_subcoolEstTlSNA m17 : 39|6@1- (2,0) [0|0] "" Vector__XXX
 SG_ VCFRONT_tempSuperheatActual m5 : 39|10@1+ (0.1,-20) [0|0] "" Vector__XXX
 SG_ VCFRONT_PSuctionControllerOutput m11 : 40|8@1+ (0.5,0) [0|0] "" Vector__XXX
 SG_ VCFRONT_ccLeftExvRange m4 : 40|8@1+ (7,0) [0|0] "" Vector__XXX
 SG_ VCFRONT_compressorSuctionVaporQuality m25 : 40|5@1+ (0.01,0.7) [0|0] "" Vector__XXX
 SG_ VCFRONT_coolantFlowChillerTarget m21 : 40|8@1+ (0.161,0) [0|0] "" Vector__XXX
 SG_ VCFRONT_fanCurrentIndex m22 : 40|7@1+ (1,0) [0|0] "" Vector__XXX
 SG_ VCFRONT_highSideDpResidual m18 : 40|7@1- (0.1,0) [0|0] "" Vector__XXX
 SG_ VCFRONT_homelinkCurrent m19 : 40|5@1+ (0.01,0) [0|0] "" Vector__XXX
 SG_ VCFRONT_maxAllowedEvapPowerInSeries m9 : 40|8@1+ (40,0) [0|0] "" Vector__XXX
 SG_ VCFRONT_chillerCOP1ResidualLoad m15 : 41|7@1+ (78.74015748031496,0) [0|0] "" Vector__XXX
 SG_ VCFRONT_pumpPowertrainFETTemp m1 : 41|8@1+ (1,-40) [0|0] "" Vector__XXX
 SG_ VCFRONT_recircEXVControlState m8 : 41|3@1+ (1,0) [0|0] "" Vector__XXX
 SG_ VCFRONT_targetBatOptionalActiveCool m0 : 41|7@1+ (1,0) [0|0] "" Vector__XXX
 SG_ VCFRONT_DIQdotA m6 : 42|7@1+ (80,0) [0|0] "" Vector__XXX
 SG_ VCFRONT_radActiveRejectEstimate m10 : 42|7@1+ (150,0) [0|0] "" Vector__XXX
 SG_ VCFRONT_windshldFluidPumpCurrent m20 : 42|6@1+ (0.5,0) [0|0] "" Vector__XXX
 SG_ VCFRONT_coolantLevelVoltage m3 : 43|9@1+ (0.01,0) [0|0] "" Vector__XXX
 SG_ VCFRONT_hpCompPowerIndex m13 : 43|7@1+ (1,0) [0|0] "" Vector__XXX
 SG_ VCFRONT_vcleftDynamicBucketFill1 m23 : 43|5@1+ (40,0) [0|0] "" Vector__XXX
 SG_ VCFRONT_vcrightDynamicBucketFill1 m24 : 43|5@1+ (40,0) [0|0] "" Vector__XXX
 SG_ VCFRONT_coolantValveWindupEst m2 : 44|6@1+ (2,0) [0|0] "" Vector__XXX
 SG_ VCFRONT_lccEXVControlState m8 : 44|3@1+ (1,0) [0|0] "" Vector__XXX
 SG_ VCFRONT_radMovementBlockActive m16 : 44|1@1+ (1,0) [0|0] "" Vector__XXX
 SG_ VCFRONT_radBypassMoveReason m16 : 45|4@1+ (1,0) [0|0] "" Vector__XXX
 SG_ VCFRONT_radarCurrent m19 : 45|5@1+ (0.5,0) [0|0] "" Vector__XXX
 SG_ VCFRONT_subcoolEstPlSNA m17 : 45|6@1- (2,0) [0|0] "" Vector__XXX
 SG_ VCFRONT_tempRefrigLiquid m14 : 45|11@1+ (0.125,-40) [0|0] "" Vector__XXX
 SG_ VCFRONT_estCompressorRpm m7 : 46|9@1+ (30,0) [0|0] "" Vector__XXX
 SG_ VCFRONT_abnormalHighSuctionSuperheat m18 : 47|1@1+ (1,0) [0|0] "" Vector__XXX
 SG_ VCFRONT_cclEXVControlState m8 : 47|3@1+ (1,0) [0|0] "" Vector__XXX
 SG_ VCFRONT_fanControlRadCanCool m12 : 47|1@1+ (1,0) [0|0] "" Vector__XXX
 SG_ VCFRONT_cabinHeatingCOP1MinActiveRefCharge m25 : 48|7@1+ (10,0) [0|0] "" Vector__XXX
 SG_ VCFRONT_ccRightExvRange m4 : 48|8@1+ (7,0) [0|0] "" Vector__XXX
 SG_ VCFRONT_coolantValveAngleTravel m18 : 48|10@1+ (5,0) [0|0] "" Vector__XXX
 SG_ VCFRONT_fanControlFeedfwdActive m12 : 48|1@1+ (1,0) [0|0] "" Vector__XXX
 SG_ VCFRONT_hpCompPowerIndexCorrected m22 : 48|7@1+ (1,0) [0|0] "" Vector__XXX
 SG_ VCFRONT_minAllowedChillerPowerInSeries m9 : 48|8@1+ (40,0) [0|0] "" Vector__XXX
 SG_ VCFRONT_minAllowedSuctionPressure m11 : 48|7@1+ (0.02,0) [0|0] "" Vector__XXX
 SG_ VCFRONT_radiatorFanRPMTarget m21 : 48|8@1+ (40,0) [0|0] "" Vector__XXX
 SG_ VCFRONT_targetBatPassive m0 : 48|7@1+ (1,-20) [0|0] "" Vector__XXX
 SG_ VCFRONT_upperGlassHeaterCurrent m20 : 48|9@1+ (0.05,0) [0|0] "" Vector__XXX
 SG_ VCFRONT_vcleftDynamicBucketFill2 m23 : 48|5@1+ (40,0) [0|0] "" Vector__XXX
 SG_ VCFRONT_vcrightDynamicBucketFill2 m24 : 48|5@1+ (40,0) [0|0] "" Vector__XXX
 SG_ VCFRONT_wiperCycles m15 : 48|16@1+ (100,0) [0|0] "" Vector__XXX
 SG_ VCFRONT_evapFdFrwrdTargetMinimum m6 : 49|7@1+ (80,0) [0|0] "" Vector__XXX
 SG_ VCFRONT_fanControlRadiatorUa m12 : 49|7@1+ (8,0) [0|0] "" Vector__XXX
 SG_ VCFRONT_hpBattHeatingPower m16 : 49|7@1+ (100,0) [0|0] "" Vector__XXX
 SG_ VCFRONT_radOptionalRejectEstimate m10 : 49|7@1+ (150,0) [0|0] "" Vector__XXX
 SG_ VCFRONT_radiatorFanFETTemp m1 : 49|8@1+ (1,-40) [0|0] "" Vector__XXX
 SG_ VCFRONT_tempSuperheatTarget m5 : 49|10@1+ (0.1,0) [0|0] "" Vector__XXX
 SG_ VCFRONT_ccrEXVControlState m8 : 50|3@1+ (1,0) [0|0] "" Vector__XXX
 SG_ VCFRONT_coolantValveRadBypass m2 : 50|7@1+ (1,0) [0|0] "" Vector__XXX
 SG_ VCFRONT_hpAtSteadyState m13 : 50|1@1+ (1,0) [0|0] "" Vector__XXX
 SG_ VCFRONT_shutOffValve1Current m19 : 50|6@1+ (0.2,0) [0|0] "" Vector__XXX
 SG_ VCFRONT_pressureRefrigSuctionEst m13 : 51|6@1+ (0.16,0) [0|0] "" Vector__XXX
 SG_ VCFRONT_tempRefrigLiquidEst m17 : 51|6@1+ (2,0) [0|0] "" Vector__XXX
 SG_ VCFRONT_estimatedChillerLoadCOP1 m3 : 52|8@1+ (39.21568627450981,0) [0|0] "" Vector__XXX
 SG_ VCFRONT_chillerExvCalibFailed m8 : 53|1@1+ (1,0) [0|0] "" Vector__XXX
 SG_ VCFRONT_vcleftDynamicBucketFill3 m23 : 53|5@1+ (40,0) [0|0] "" Vector__XXX
 SG_ VCFRONT_vcrightDynamicBucketFill3 m24 : 53|5@1+ (40,0) [0|0] "" Vector__XXX
 SG_ VCFRONT_evapExvCalibFailed m8 : 54|1@1+ (1,0) [0|0] "" Vector__XXX
 SG_ VCFRONT_estQLift m7 : 55|6@1+ (100,0) [0|0] "" Vector__XXX
 SG_ VCFRONT_recircExvCalibFailed m8 : 55|1@1+ (1,0) [0|0] "" Vector__XXX
 SG_ VCFRONT_targetBatActiveHeat m0 : 55|7@1+ (1,-40) [0|0] "" Vector__XXX
 SG_ VCFRONT_batteryDischArbState m21 : 56|3@1+ (1,0) [0|0] "" Vector__XXX
 SG_ VCFRONT_chillerCOP1CoolantFlowRate m10 : 56|8@1+ (0.00196078431372549,0) [0|0] "" Vector__XXX
 SG_ VCFRONT_chillerCOP1CoolantInlet m22 : 56|7@1- (1.2698412698412698,0) [0|0] "" Vector__XXX
 SG_ VCFRONT_fanControlRadiatorInletTemp m12 : 56|6@1- (1.8,36) [0|0] "" Vector__XXX
 SG_ VCFRONT_hpCompPowerIndexFiltered m9 : 56|7@1+ (1,0) [0|0] "" Vector__XXX
 SG_ VCFRONT_hvCompCurrent m19 : 56|8@1+ (0.1,0) [0|0] "" Vector__XXX
 SG_ VCFRONT_lccExvCalibFailed m8 : 56|1@1+ (1,0) [0|0] "" Vector__XXX
 SG_ VCFRONT_maxCompressorRPMAllowed m11 : 56|7@1+ (90,0) [0|0] "" Vector__XXX
 SG_ VCFRONT_passiveCoolingState m6 : 56|2@1+ (1,0) [0|0] "" Vector__XXX
 SG_ VCFRONT_tempCoolantRadOutletEst m4 : 56|7@1- (1,23) [0|0] "" Vector__XXX
 SG_ VCFRONT_tempCoolantRadOutletEstStatus m16 : 56|2@1+ (1,0) [0|0] "" Vector__XXX
 SG_ VCFRONT_totalBattHeatingPower m14 : 56|7@1+ (150,0) [0|0] "" Vector__XXX
 SG_ VCFRONT_ccLeftExvCalibFailed m8 : 57|1@1+ (1,0) [0|0] "" Vector__XXX
 SG_ VCFRONT_lowerGlassHeaterCurrent m20 : 57|7@1+ (0.2,0) [0|0] "" Vector__XXX
 SG_ VCFRONT_pressureRefrigLiquidEst m17 : 57|6@1+ (0.5,0) [0|0] "" Vector__XXX
 SG_ VCFRONT_radiatorFanRunReason m1 : 57|4@1+ (1,0) [0|0] "" Vector__XXX
 SG_ VCFRONT_suctionSuperheatEstPsSNA m13 : 57|4@1+ (2,0) [0|0] "" Vector__XXX
 SG_ VCFRONT_usingModeledPs m2 : 57|1@1+ (1,0) [0|0] "" Vector__XXX
 SG_ VCFRONT_ccRightExvCalibFailed m8 : 58|1@1+ (1,0) [0|0] "" Vector__XXX
 SG_ VCFRONT_chargeShuttleType m18 : 58|2@1+ (1,0) [0|0] "" Vector__XXX
 SG_ VCFRONT_targetBatActiveCoolSource m16 : 58|3@1+ (1,0) [0|0] "" Vector__XXX
 SG_ VCFRONT_totalLoadCoolingDominant m6 : 58|1@1+ (1,0) [0|0] "" Vector__XXX
 SG_ VCFRONT_usingModeledPd m2 : 58|1@1+ (1,0) [0|0] "" Vector__XXX
 SG_ VCFRONT_vcleftFastBlowCounter m23 : 58|3@1+ (1,0) [0|0] "" Vector__XXX
 SG_ VCFRONT_vcrightFastBlowCounter m24 : 58|3@1+ (1,0) [0|0] "" Vector__XXX
 SG_ VCFRONT_ambientTempSniffActive m8 : 59|1@1+ (1,0) [0|0] "" Vector__XXX
 SG_ VCFRONT_feedfwdLoadCoolingDominant m6 : 59|1@1+ (1,0) [0|0] "" Vector__XXX
 SG_ VCFRONT_preventReEntryTillNexthpResetCOP1 m21 : 59|1@1+ (1,0) [0|0] "" Vector__XXX
 SG_ VCFRONT_refrigerantHasBeenFilled m5 : 59|1@1+ (1,0) [0|0] "" Vector__XXX
 SG_ VCFRONT_usingModeledPl m2 : 59|1@1+ (1,0) [0|0] "" Vector__XXX
 SG_ VCFRONT_ambientTempPassiveSniffing m8 : 60|1@1+ (1,0) [0|0] "" Vector__XXX
 SG_ VCFRONT_chillerBattHeatingPowerAvailable m21 : 60|1@1+ (1,0) [0|0] "" Vector__XXX
 SG_ VCFRONT_dtcConfirmed m3 : 60|1@1+ (1,0) [0|0] "" Vector__XXX
 SG_ VCFRONT_hpRefrigTempSensorCheckCanFire m18 : 60|1@1+ (1,0) [0|0] "" Vector__XXX
 SG_ VCFRONT_modelLoadCoolingDominant m6 : 60|1@1+ (1,0) [0|0] "" Vector__XXX
 SG_ VCFRONT_refCommissionStatus m5 : 60|2@1+ (1,0) [0|0] "" Vector__XXX
 SG_ VCFRONT_usingModeledTs m2 : 60|1@1+ (1,0) [0|0] "" Vector__XXX
 SG_ VCFRONT_ambientTempRadSampling m8 : 61|1@1+ (1,0) [0|0] "" Vector__XXX
 SG_ VCFRONT_autopilotAirPurgeRoutineState m3 : 61|3@1+ (1,0) [0|0] "" Vector__XXX
 SG_ VCFRONT_coolantValveModeWrong m1 : 61|1@1+ (1,0) [0|0] "" Vector__XXX
 SG_ VCFRONT_cycleModelConverged m7 : 61|1@1+ (1,0) [0|0] "" Vector__XXX
 SG_ VCFRONT_hpPotentialLowRefrig m6 : 61|1@1+ (1,0) [0|0] "" Vector__XXX
 SG_ VCFRONT_hpRefrigPressureSensorCheckCanFire m18 : 61|1@1+ (1,0) [0|0] "" Vector__XXX
 SG_ VCFRONT_isExpectedQChillerVeryHighCOP1 m21 : 61|1@1+ (1,0) [0|0] "" Vector__XXX
 SG_ VCFRONT_pdModelGrosslyOff m13 : 61|1@1+ (1,0) [0|0] "" Vector__XXX
 SG_ VCFRONT_targetPTActiveCoolSource m16 : 61|3@1+ (1,0) [0|0] "" Vector__XXX
 SG_ VCFRONT_usingModeledTd m2 : 61|1@1+ (1,0) [0|0] "" Vector__XXX
 SG_ VCFRONT_vcleftFastBlowCounter0 m23 : 61|3@1+ (1,0) [0|0] "" Vector__XXX
 SG_ VCFRONT_vcrightFastBlowCounter0 m24 : 61|3@1+ (1,0) [0|0] "" Vector__XXX
 SG_ VCFRONT_LCCPurgeActive m5 : 62|1@1+ (1,0) [0|0] "" Vector__XXX
 SG_ VCFRONT_ambientTempSpeedSampling m8 : 62|1@1+ (1,0) [0|0] "" Vector__XXX
 SG_ VCFRONT_autopilotAirPurgeRoutineCounter m21 : 62|2@1+ (1,0) [0|0] "" Vector__XXX
 SG_ VCFRONT_compStandbyCoastDownMode m7 : 62|1@1+ (1,0) [0|0] "" Vector__XXX
 SG_ VCFRONT_coolantTempBasedMode m1 : 62|2@1+ (1,0) [0|0] "" Vector__XXX
 SG_ VCFRONT_hpRefrigerantPurgeState m6 : 62|2@1+ (1,0) [0|0] "" Vector__XXX
 SG_ VCFRONT_psModelGrosslyOff m13 : 62|1@1+ (1,0) [0|0] "" Vector__XXX
 SG_ VCFRONT_usingModeledTl m2 : 62|1@1+ (1,0) [0|0] "" Vector__XXX
 SG_ VCFRONT_battAboveMaxCoolantTemp m13 : 63|1@1+ (1,0) [0|0] "" Vector__XXX
 SG_ VCFRONT_cmpIsentropicCheckPassed m17 : 63|1@1+ (1,0) [0|0] "" Vector__XXX
 SG_ VCFRONT_compStandbyOTA m9 : 63|1@1+ (1,0) [0|0] "" Vector__XXX
 SG_ VCFRONT_compStandbyShowroomMode m7 : 63|1@1+ (1,0) [0|0] "" Vector__XXX
 SG_ VCFRONT_hpPotentialFrozenRadiator m14 : 63|1@1+ (1,0) [0|0] "" Vector__XXX

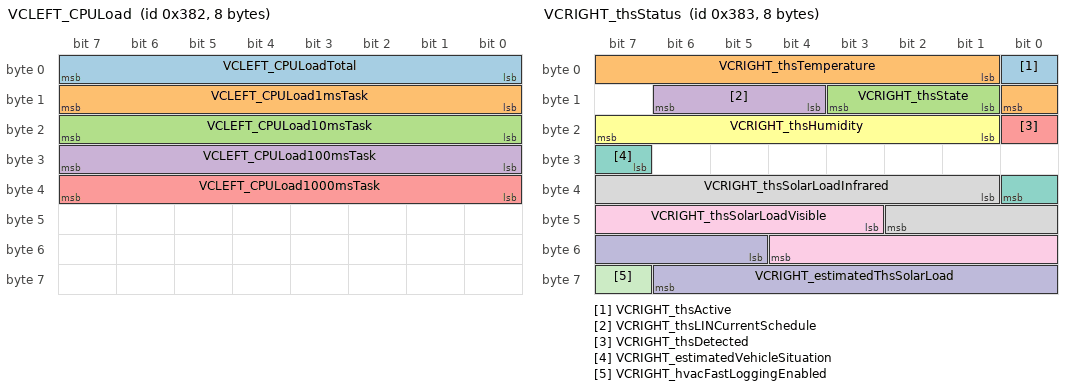
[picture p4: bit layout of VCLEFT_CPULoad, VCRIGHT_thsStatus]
BO_ 898 VCLEFT_CPULoad: 8 Vector__XXX
 SG_ VCLEFT_CPULoadTotal : 0|8@1+ (1,0) [0|0] "" Vector__XXX
 SG_ VCLEFT_CPULoad1msTask : 8|8@1+ (1,0) [0|0] "" Vector__XXX
 SG_ VCLEFT_CPULoad10msTask : 16|8@1+ (1,0) [0|0] "" Vector__XXX
 SG_ VCLEFT_CPULoad100msTask : 24|8@1+ (1,0) [0|0] "" Vector__XXX
 SG_ VCLEFT_CPULoad1000msTask : 32|8@1+ (1,0) [0|0] "" Vector__XXX

BO_ 899 VCRIGHT_thsStatus: 8 Vector__XXX
 SG_ VCRIGHT_thsActive : 0|1@1+ (1,0) [0|0] "" Vector__XXX
 SG_ VCRIGHT_thsTemperature : 1|8@1+ (1,-40) [0|0] "" Vector__XXX
 SG_ VCRIGHT_thsState : 9|3@1+ (1,0) [0|0] "" Vector__XXX
 SG_ VCRIGHT_thsLINCurrentSchedule : 12|3@1+ (1,0) [0|0] "" Vector__XXX
 SG_ VCRIGHT_thsDetected : 16|1@1+ (1,0) [0|0] "" Vector__XXX
 SG_ VCRIGHT_thsHumidity : 17|7@1+ (1,0) [0|0] "" Vector__XXX
 SG_ VCRIGHT_estimatedVehicleSituation : 31|2@1+ (1,0) [0|0] "" Vector__XXX
 SG_ VCRIGHT_thsSolarLoadInfrared : 33|10@1+ (2,0) [0|0] "" Vector__XXX
 SG_ VCRIGHT_thsSolarLoadVisible : 43|10@1+ (2,0) [0|0] "" Vector__XXX
 SG_ VCRIGHT_estimatedThsSolarLoad : 53|10@1+ (1,0) [0|0] "" Vector__XXX
 SG_ VCRIGHT_hvacFastLoggingEnabled : 63|1@1+ (1,0) [0|0] "" Vector__XXX

BO_ 900 PM_alertMatrix1: 8 Vector__XXX
 SG_ PM_a001_absoluteTorque : 0|1@1+ (1,0) [0|0] "" Vector__XXX
 SG_ PM_a002_excessiveAccelTorque : 1|1@1+ (1,0) [0|0] "" Vector__XXX
 SG_ PM_a003_excessiveReversalTorque : 2|1@1+ (1,0) [0|0] "" Vector__XXX
 SG_ PM_a004_excessiveDecelTorque : 3|1@1+ (1,0) [0|0] "" Vector__XXX
 SG_ PM_a005_torqueInNeutralOrPark : 4|1@1+ (1,0) [0|0] "" Vector__XXX
 SG_ PM_a006_inconsistentDIGear : 5|1@1+ (1,0) [0|0] "" Vector__XXX
 SG_ PM_a007_ibstMIA : 6|1@1+ (1,0) [0|0] "" Vector__XXX
 SG_ PM_a008_memoryError : 7|1@1+ (1,0) [0|0] "" Vector__XXX
 SG_ PM_a009_espMIA : 8|1@1+ (1,0) [0|0] "" Vector__XXX
 SG_ PM_a010_diMIA : 9|1@1+ (1,0) [0|0] "" Vector__XXX
 SG_ PM_a012_canDataBusA : 11|1@1+ (1,0) [0|0] "" Vector__XXX
 SG_ PM_a013_canHardwareBusA : 12|1@1+ (1,0) [0|0] "" Vector__XXX
 SG_ PM_a014_accelPedalError : 13|1@1+ (1,0) [0|0] "" Vector__XXX
 SG_ PM_a015_shifterMIA : 14|1@1+ (1,0) [0|0] "" Vector__XXX
 SG_ PM_a017_brakeMIA : 16|1@1+ (1,0) [0|0] "" Vector__XXX
 SG_ PM_a019_vehicleSpeedQFDiagnostic : 18|1@1+ (1,0) [0|0] "" Vector__XXX
 SG_ PM_a021_difMIA : 20|1@1+ (1,0) [0|0] "" Vector__XXX
 SG_ PM_a022_dirMIA : 21|1@1+ (1,0) [0|0] "" Vector__XXX
 SG_ PM_a023_cruiseInhibit : 22|1@1+ (1,0) [0|0] "" Vector__XXX
 SG_ PM_a024_brakeIrrational : 23|1@1+ (1,0) [0|0] "" Vector__XXX
 SG_ PM_a025_unintendedReset : 24|1@1+ (1,0) [0|0] "" Vector__XXX
 SG_ PM_a026_diHeartBeatMIA : 25|1@1+ (1,0) [0|0] "" Vector__XXX
 SG_ PM_a028_torqueCmdError : 27|1@1+ (1,0) [0|0] "" Vector__XXX
 SG_ PM_a029_cruiseRollback : 28|1@1+ (1,0) [0|0] "" Vector__XXX
 SG_ PM_a030_inconsistentAebState : 29|1@1+ (1,0) [0|0] "" Vector__XXX
 SG_ PM_a031_highStackUsage : 30|1@1+ (1,0) [0|0] "" Vector__XXX
 SG_ PM_a032_registerConfigError : 31|1@1+ (1,0) [0|0] "" Vector__XXX
 SG_ PM_a033_appMIA : 32|1@1+ (1,0) [0|0] "" Vector__XXX
 SG_ PM_a034_trqCrossCheck : 33|1@1+ (1,0) [0|0] "" Vector__XXX
 SG_ PM_a035_udsTransactionInitiated : 34|1@1+ (1,0) [0|0] "" Vector__XXX
 SG_ PM_a036_preWatchdog : 35|1@1+ (1,0) [0|0] "" Vector__XXX
 SG_ PM_a038_inconsistentTorqueSign : 37|1@1+ (1,0) [0|0] "" Vector__XXX
 SG_ PM_a039_disMIA : 38|1@1+ (1,0) [0|0] "" Vector__XXX
 SG_ PM_a040_alignmentDriftDetected : 39|1@1+ (1,0) [0|0] "" Vector__XXX
 SG_ PM_a041_dasMIA : 40|1@1+ (1,0) [0|0] "" Vector__XXX
 SG_ PM_a042_gtwMIA : 41|1@1+ (1,0) [0|0] "" Vector__XXX
 SG_ PM_a043_inconsistentConfig : 42|1@1+ (1,0) [0|0] "" Vector__XXX
 SG_ PM_a044_ebrIntervention : 43|1@1+ (1,0) [0|0] "" Vector__XXX
 SG_ PM_a045_regenBackfillIntervention : 44|1@1+ (1,0) [0|0] "" Vector__XXX
 SG_ PM_a046_inconsVehicleHoldState : 45|1@1+ (1,0) [0|0] "" Vector__XXX
 SG_ PM_a047_inconsAutoparkState : 46|1@1+ (1,0) [0|0] "" Vector__XXX
 SG_ PM_a048_stabilityControlInhibit : 47|1@1+ (1,0) [0|0] "" Vector__XXX
 SG_ PM_a049_stbCtrlInWrongDir : 48|1@1+ (1,0) [0|0] "" Vector__XXX
 SG_ PM_a050_excessiveStbCtrlTrq : 49|1@1+ (1,0) [0|0] "" Vector__XXX
 SG_ PM_a051_unintDecelStbCtrl : 50|1@1+ (1,0) [0|0] "" Vector__XXX
 SG_ PM_a052_stbCtrlDrvrDecelCflct : 51|1@1+ (1,0) [0|0] "" Vector__XXX
 SG_ PM_a053_vcfrontMIA : 52|1@1+ (1,0) [0|0] "" Vector__XXX
 SG_ PM_a054_uiMIA : 53|1@1+ (1,0) [0|0] "" Vector__XXX
 SG_ PM_a055_accelPedalSyncWarn : 54|1@1+ (1,0) [0|0] "" Vector__XXX
 SG_ PM_a056_canHardwareBusB : 55|1@1+ (1,0) [0|0] "" Vector__XXX
 SG_ PM_a057_canDataBusB : 56|1@1+ (1,0) [0|0] "" Vector__XXX
 SG_ PM_a058_cmpMIA : 57|1@1+ (1,0) [0|0] "" Vector__XXX
 SG_ PM_a059_ptcMIA : 58|1@1+ (1,0) [0|0] "" Vector__XXX
 SG_ PM_a060_onePedalDrivingInhibit : 59|1@1+ (1,0) [0|0] "" Vector__XXX
 SG_ PM_a061_DIPMVersionMismatch : 60|1@1+ (1,0) [0|0] "" Vector__XXX
 SG_ PM_a062_eccError : 61|1@1+ (1,0) [0|0] "" Vector__XXX
 SG_ PM_a063_torqueCommandInhibit : 62|1@1+ (1,0) [0|0] "" Vector__XXX
 SG_ PM_a064_torqueIntervention : 63|1@1+ (1,0) [0|0] "" Vector__XXX

BO_ 902 PMR_alertMatrix1: 8 Vector__XXX
 SG_ PMR_a001_absoluteTorque : 0|1@1+ (1,0) [0|0] "" Vector__XXX
 SG_ PMR_a002_excessiveAccelTorque : 1|1@1+ (1,0) [0|0] "" Vector__XXX
 SG_ PMR_a003_excessiveReversalTorque : 2|1@1+ (1,0) [0|0] "" Vector__XXX
 SG_ PMR_a004_excessiveDecelTorque : 3|1@1+ (1,0) [0|0] "" Vector__XXX
 SG_ PMR_a005_torqueInNeutralOrPark : 4|1@1+ (1,0) [0|0] "" Vector__XXX
 SG_ PMR_a008_memoryError : 7|1@1+ (1,0) [0|0] "" Vector__XXX
 SG_ PMR_a010_diMIA : 9|1@1+ (1,0) [0|0] "" Vector__XXX
 SG_ PMR_a011_phaseCurrentIrrational : 10|1@1+ (1,0) [0|0] "" Vector__XXX
 SG_ PMR_a012_canDataBusA : 11|1@1+ (1,0) [0|0] "" Vector__XXX
 SG_ PMR_a013_canHardwareBusA : 12|1@1+ (1,0) [0|0] "" Vector__XXX
 SG_ PMR_a017_brakeMIA : 16|1@1+ (1,0) [0|0] "" Vector__XXX
 SG_ PMR_a018_encoderIrrational : 17|1@1+ (1,0) [0|0] "" Vector__XXX
 SG_ PMR_a019_statorTempIrrational : 18|1@1+ (1,0) [0|0] "" Vector__XXX
 SG_ PMR_a025_unintendedReset : 24|1@1+ (1,0) [0|0] "" Vector__XXX
 SG_ PMR_a026_diHeartBeatMIA : 25|1@1+ (1,0) [0|0] "" Vector__XXX
 SG_ PMR_a027_torqueEstimationOutOfBounds : 26|1@1+ (1,0) [0|0] "" Vector__XXX
 SG_ PMR_a028_torqueCmdError : 27|1@1+ (1,0) [0|0] "" Vector__XXX
 SG_ PMR_a031_highStackUsage : 30|1@1+ (1,0) [0|0] "" Vector__XXX
 SG_ PMR_a032_registerConfigError : 31|1@1+ (1,0) [0|0] "" Vector__XXX
 SG_ PMR_a033_selfTest : 32|1@1+ (1,0) [0|0] "" Vector__XXX
 SG_ PMR_a034_trqCrossCheck : 33|1@1+ (1,0) [0|0] "" Vector__XXX
 SG_ PMR_a035_udsTransactionInitiated : 34|1@1+ (1,0) [0|0] "" Vector__XXX
 SG_ PMR_a036_preWatchdog : 35|1@1+ (1,0) [0|0] "" Vector__XXX
 SG_ PMR_a037_hvpMIA : 36|1@1+ (1,0) [0|0] "" Vector__XXX
 SG_ PMR_a039_disMIA : 38|1@1+ (1,0) [0|0] "" Vector__XXX
 SG_ PMR_a040_pmMIA : 39|1@1+ (1,0) [0|0] "" Vector__XXX
 SG_ PMR_a042_gtwMIA : 41|1@1+ (1,0) [0|0] "" Vector__XXX
 SG_ PMR_a045_motorMovementDetected : 44|1@1+ (1,0) [0|0] "" Vector__XXX
 SG_ PMR_a053_vcfrontMIA : 52|1@1+ (1,0) [0|0] "" Vector__XXX
 SG_ PMR_a054_uiMIA : 53|1@1+ (1,0) [0|0] "" Vector__XXX
 SG_ PMR_a055_resolver : 54|1@1+ (1,0) [0|0] "" Vector__XXX
 SG_ PMR_a056_canHardwareBusB : 55|1@1+ (1,0) [0|0] "" Vector__XXX
 SG_ PMR_a057_canDataBusB : 56|1@1+ (1,0) [0|0] "" Vector__XXX
 SG_ PMR_a061_DIPMVersionMismatch : 60|1@1+ (1,0) [0|0] "" Vector__XXX
 SG_ PMR_a062_eccError : 61|1@1+ (1,0) [0|0] "" Vector__XXX
 SG_ PMR_a064_torqueIntervention : 63|1@1+ (1,0) [0|0] "" Vector__XXX

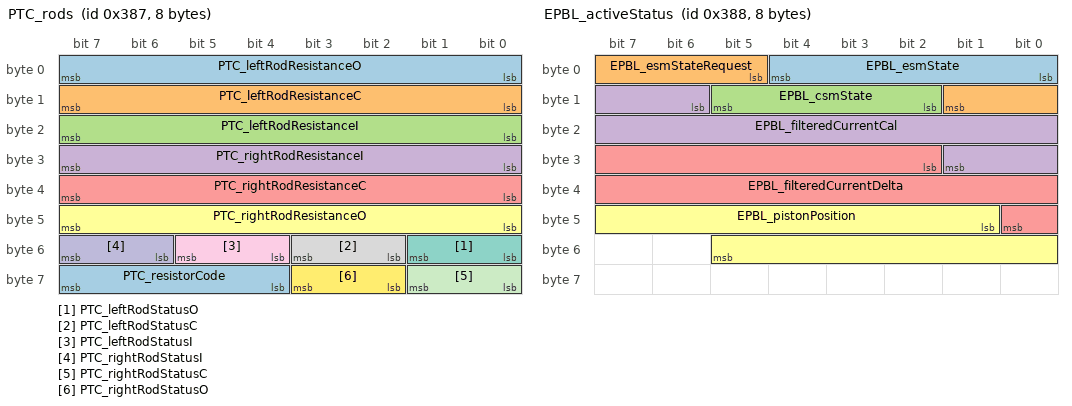
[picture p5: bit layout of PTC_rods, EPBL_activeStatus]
BO_ 903 PTC_rods: 8 Vector__XXX
 SG_ PTC_leftRodResistanceO : 0|8@1+ (2,0) [0|0] "" Vector__XXX
 SG_ PTC_leftRodResistanceC : 8|8@1+ (2,0) [0|0] "" Vector__XXX
 SG_ PTC_leftRodResistanceI : 16|8@1+ (2,0) [0|0] "" Vector__XXX
 SG_ PTC_rightRodResistanceI : 24|8@1+ (2,0) [0|0] "" Vector__XXX
 SG_ PTC_rightRodResistanceC : 32|8@1+ (2,0) [0|0] "" Vector__XXX
 SG_ PTC_rightRodResistanceO : 40|8@1+ (2,0) [0|0] "" Vector__XXX
 SG_ PTC_leftRodStatusO : 48|2@1+ (1,0) [0|0] "" Vector__XXX
 SG_ PTC_leftRodStatusC : 50|2@1+ (1,0) [0|0] "" Vector__XXX
 SG_ PTC_leftRodStatusI : 52|2@1+ (1,0) [0|0] "" Vector__XXX
 SG_ PTC_rightRodStatusI : 54|2@1+ (1,0) [0|0] "" Vector__XXX
 SG_ PTC_rightRodStatusC : 56|2@1+ (1,0) [0|0] "" Vector__XXX
 SG_ PTC_rightRodStatusO : 58|2@1+ (1,0) [0|0] "" Vector__XXX
 SG_ PTC_resistorCode : 60|4@1+ (1,0) [0|0] "" Vector__XXX

BO_ 904 EPBL_activeStatus: 8 Vector__XXX
 SG_ EPBL_esmState : 0|5@1+ (1,0) [0|0] "" Vector__XXX
 SG_ EPBL_esmStateRequest : 5|5@1+ (1,0) [0|0] "" Vector__XXX
 SG_ EPBL_csmState : 10|4@1+ (1,0) [0|0] "" Vector__XXX
 SG_ EPBL_filteredCurrentCal : 14|12@1+ (0.01,0) [0|0] "" Vector__XXX
 SG_ EPBL_filteredCurrentDelta : 26|15@1- (0.01,0) [0|0] "" Vector__XXX
 SG_ EPBL_pistonPosition : 41|13@1- (9.768009768009769,0) [0|0] "" Vector__XXX

BO_ 906 VCSEC_NFCCurrentCardUID: 8 Vector__XXX
 SG_ VCSEC_NFCReaderIndexUID M : 0|2@1+ (1,0) [0|0] "" Vector__XXX
 SG_ VCSEC_BPillarNFCCardUIDL m0 : 8|56@1+ (1,0) [0|0] "" Vector__XXX
 SG_ VCSEC_BPillarNFCCardUIDR m1 : 8|56@1+ (1,0) [0|0] "" Vector__XXX
 SG_ VCSEC_CenterNFCCardUID m3 : 8|56@1+ (1,0) [0|0] "" Vector__XXX

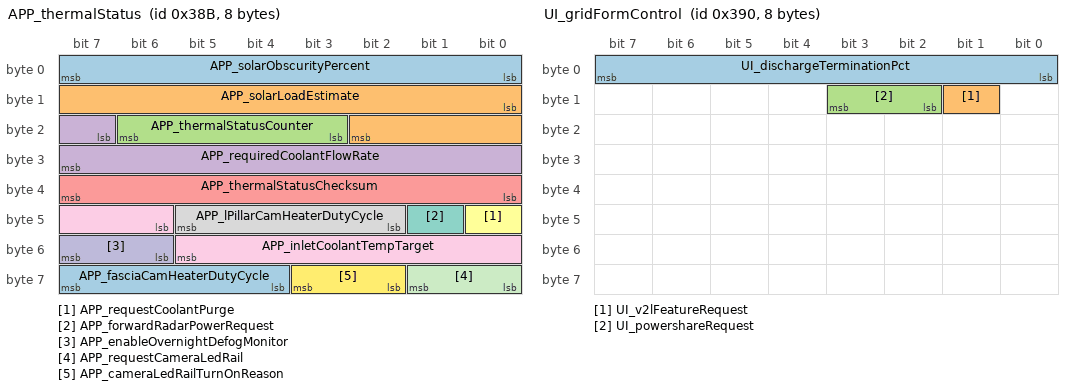
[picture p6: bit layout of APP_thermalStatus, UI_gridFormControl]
BO_ 907 APP_thermalStatus: 8 Vector__XXX
 SG_ APP_solarObscurityPercent : 0|8@1+ (0.5,-25) [0|0] "" Vector__XXX
 SG_ APP_solarLoadEstimate : 8|11@1+ (1,0) [0|0] "" Vector__XXX
 SG_ APP_thermalStatusCounter : 19|4@1+ (1,0) [0|0] "" Vector__XXX
 SG_ APP_requiredCoolantFlowRate : 23|9@1+ (0.1,0) [0|0] "" Vector__XXX
 SG_ APP_thermalStatusChecksum : 32|8@1+ (1,0) [0|0] "" Vector__XXX
 SG_ APP_requestCoolantPurge : 40|1@1+ (1,0) [0|0] "" Vector__XXX
 SG_ APP_forwardRadarPowerRequest : 41|1@1+ (1,0) [0|0] "" Vector__XXX
 SG_ APP_lPillarCamHeaterDutyCycle : 42|4@1+ (0.06666666666666667,0) [0|0] "" Vector__XXX
 SG_ APP_inletCoolantTempTarget : 46|8@1+ (0.5,0) [0|0] "" Vector__XXX
 SG_ APP_enableOvernightDefogMonitor : 54|2@1+ (1,0) [0|0] "" Vector__XXX
 SG_ APP_requestCameraLedRail : 56|2@1+ (1,0) [0|0] "" Vector__XXX
 SG_ APP_cameraLedRailTurnOnReason : 58|2@1+ (1,0) [0|0] "" Vector__XXX
 SG_ APP_fasciaCamHeaterDutyCycle : 60|4@1+ (0.06666666666666667,0) [0|0] "" Vector__XXX

BO_ 909 APP_VC_infoMessage: 8 Vector__XXX
 SG_ APP_inTunnel : 0|2@1+ (1,0) [0|0] "" Vector__XXX
 SG_ APP_windshieldHeaterOnReason : 2|4@1+ (1,0) [0|0] "" Vector__XXX
 SG_ APP_selfieCameraBlocked : 6|2@1+ (1,0) [0|0] "" Vector__XXX
 SG_ APP_selfieCameraLUX : 8|8@1+ (1,0) [0|0] "" Vector__XXX
 SG_ APP_sceneTagClearlyRaining : 16|2@1+ (1,0) [0|0] "" Vector__XXX
 SG_ APP_sceneTagFog : 18|2@1+ (1,0) [0|0] "" Vector__XXX
 SG_ APP_sceneTagFullyBlocked : 20|2@1+ (1,0) [0|0] "" Vector__XXX
 SG_ APP_sceneTagIndoors : 22|2@1+ (1,0) [0|0] "" Vector__XXX
 SG_ APP_sceneTagLensFlare : 24|2@1+ (1,0) [0|0] "" Vector__XXX
 SG_ APP_sceneTagRaining : 26|2@1+ (1,0) [0|0] "" Vector__XXX
 SG_ APP_sceneTagSevereWeather : 28|2@1+ (1,0) [0|0] "" Vector__XXX
 SG_ APP_sceneTagSnowing : 30|2@1+ (1,0) [0|0] "" Vector__XXX
 SG_ APP_sceneTagSnowyRoad : 32|2@1+ (1,0) [0|0] "" Vector__XXX
 SG_ APP_sceneTagSunGlare : 34|2@1+ (1,0) [0|0] "" Vector__XXX
 SG_ APP_sceneTagTunnel : 36|2@1+ (1,0) [0|0] "" Vector__XXX
 SG_ APP_sceneTagWetRoad : 38|2@1+ (1,0) [0|0] "" Vector__XXX
 SG_ APP_fisheyeInPathVisibility : 40|3@1+ (1,0) [0|0] "" Vector__XXX
 SG_ APP_fisheyeOverallVisibility : 43|3@1+ (1,0) [0|0] "" Vector__XXX
 SG_ APP_mainInPathVisibility : 46|3@1+ (1,0) [0|0] "" Vector__XXX
 SG_ APP_mainOverallVisibility : 49|3@1+ (1,0) [0|0] "" Vector__XXX
 SG_ APP_narrowInPathVisibility : 52|3@1+ (1,0) [0|0] "" Vector__XXX
 SG_ APP_narrowOverallVisibility : 55|3@1+ (1,0) [0|0] "" Vector__XXX
 SG_ APP_frontCamOcclusionType : 58|3@1+ (1,0) [0|0] "" Vector__XXX

BO_ 912 UI_gridFormControl: 8 Vector__XXX
 SG_ UI_dischargeTerminationPct : 0|8@1+ (1,0) [0|0] "" Vector__XXX
 SG_ UI_v2lFeatureRequest : 9|1@1+ (1,0) [0|0] "" Vector__XXX
 SG_ UI_powershareRequest : 10|2@1+ (1,0) [0|0] "" Vector__XXX

BO_ 914 BMS_packConfig: 8 Vector__XXX
 SG_ BMS_packConfigMultiplexer M : 0|8@1+ (1,0) [0|0] "" Vector__XXX
 SG_ BMS_moduleType m1 : 8|3@1+ (1,0) [0|0] "" Vector__XXX
 SG_ BMS_reservedConfig_0 m0 : 8|6@1+ (1,0) [0|0] "" Vector__XXX
 SG_ BMS_thermalPackType m1 : 11|4@1+ (1,0) [0|0] "" Vector__XXX
 SG_ BMS_packMass m1 : 16|8@1+ (1,300) [0|0] "" Vector__XXX
 SG_ BMS_platformMaxBusVoltage m1 : 24|10@1+ (1,300) [0|0] "" Vector__XXX
 SG_ BMS_standbySupplyContinuousPowerLimit m1 : 36|2@1+ (1,0) [0|0] "" Vector__XXX
 SG_ BMS_beginningOfLifePackEnergy m1 : 40|10@1+ (0.1,0) [0|0] "" Vector__XXX

BO_ 915 VCRIGHT_epbmDebug: 8 Vector__XXX
 SG_ VCRIGHT_epbmDebugIndex M : 0|1@1+ (1,0) [0|0] "" Vector__XXX
 SG_ VCRIGHT_epbmCaliperState m0 : 1|3@1+ (1,0) [0|0] "" Vector__XXX
 SG_ VCRIGHT_epbmOpenAllowed m1 : 1|1@1+ (1,0) [0|0] "" Vector__XXX
 SG_ VCRIGHT_epbmDynamicAllowed m1 : 2|1@1+ (1,0) [0|0] "" Vector__XXX
 SG_ VCRIGHT_epbmParkAllowed m1 : 3|1@1+ (1,0) [0|0] "" Vector__XXX
 SG_ VCRIGHT_epbmMotorEnabled m0 : 4|1@1+ (1,0) [0|0] "" Vector__XXX
 SG_ VCRIGHT_epbmStartAllowed m1 : 4|1@1+ (1,0) [0|0] "" Vector__XXX
 SG_ VCRIGHT_epbMotorCurrent m0 : 5|11@1+ (0.01,0) [0|0] "" Vector__XXX
 SG_ VCRIGHT_epbmServiceAllowed m1 : 5|1@1+ (1,0) [0|0] "" Vector__XXX
 SG_ VCRIGHT_epbmWinchAllowed m1 : 6|1@1+ (1,0) [0|0] "" Vector__XXX
 SG_ VCRIGHT_epbmWinchReleaseAllowed m1 : 7|1@1+ (1,0) [0|0] "" Vector__XXX
 SG_ VCRIGHT_epbmParkingAllowed m1 : 8|1@1+ (1,0) [0|0] "" Vector__XXX
 SG_ VCRIGHT_epbmDynApplyingAllowed m1 : 9|1@1+ (1,0) [0|0] "" Vector__XXX
 SG_ VCRIGHT_epbmReleasingAllowed m1 : 10|1@1+ (1,0) [0|0] "" Vector__XXX
 SG_ VCRIGHT_epbmFaultAllowed m1 : 11|1@1+ (1,0) [0|0] "" Vector__XXX
 SG_ VCRIGHT_epbmSummonAllowed m1 : 12|1@1+ (1,0) [0|0] "" Vector__XXX
 SG_ VCRIGHT_epbmSummonParkAllowed m1 : 13|1@1+ (1,0) [0|0] "" Vector__XXX
 SG_ VCRIGHT_epbmSummonReleaseAllowed m1 : 14|1@1+ (1,0) [0|0] "" Vector__XXX
 SG_ VCRIGHT_summonInitAllowed m1 : 15|1@1+ (1,0) [0|0] "" Vector__XXX
 SG_ VCRIGHT_epbmApplyVoltage m0 : 16|11@1+ (0.01,0) [0|0] "" Vector__XXX
 SG_ VCRIGHT_epbmUnknownAllowed m1 : 16|1@1+ (1,0) [0|0] "" Vector__XXX
 SG_ VCRIGHT_summonIdleAllowed m1 : 17|1@1+ (1,0) [0|0] "" Vector__XXX
 SG_ VCRIGHT_summonArmedAllowed m1 : 18|1@1+ (1,0) [0|0] "" Vector__XXX
 SG_ VCRIGHT_summonActiveAllowed m1 : 19|1@1+ (1,0) [0|0] "" Vector__XXX
 SG_ VCRIGHT_summonCompleteAllowed m1 : 20|1@1+ (1,0) [0|0] "" Vector__XXX
 SG_ VCRIGHT_summonFaultAllowed m1 : 21|1@1+ (1,0) [0|0] "" Vector__XXX
 SG_ VCRIGHT_summonUnavailableAllowed m1 : 22|1@1+ (1,0) [0|0] "" Vector__XXX
 SG_ VCRIGHT_activeDecelAllowedLatch m1 : 23|1@1+ (1,0) [0|0] "" Vector__XXX
 SG_ VCRIGHT_epbmReleaseVoltage m0 : 27|11@1+ (0.01,0) [0|0] "" Vector__XXX
 SG_ VCRIGHT_summonFaultReason m0 : 38|5@1+ (1,0) [0|0] "" Vector__XXX
 SG_ VCRIGHT_epbSummonState m0 : 43|3@1+ (1,0) [0|0] "" Vector__XXX
 SG_ VCRIGHT_epbmSummonState m0 : 46|3@1+ (1,0) [0|0] "" Vector__XXX
 SG_ VCRIGHT_epbUnitStatus m0 : 49|5@1+ (1,0) [0|0] "" Vector__XXX
 SG_ VCRIGHT_epbmFaultStatus m0 : 54|2@1+ (1,0) [0|0] "" Vector__XXX
 SG_ VCRIGHT_epbFaultStatus m0 : 56|2@1+ (1,0) [0|0] "" Vector__XXX
 SG_ VCRIGHT_epbmSystemStatus m0 : 58|4@1+ (1,0) [0|0] "" Vector__XXX
 SG_ VCRIGHT_epbmAutonomyBehavior m0 : 62|2@1+ (1,0) [0|0] "" Vector__XXX

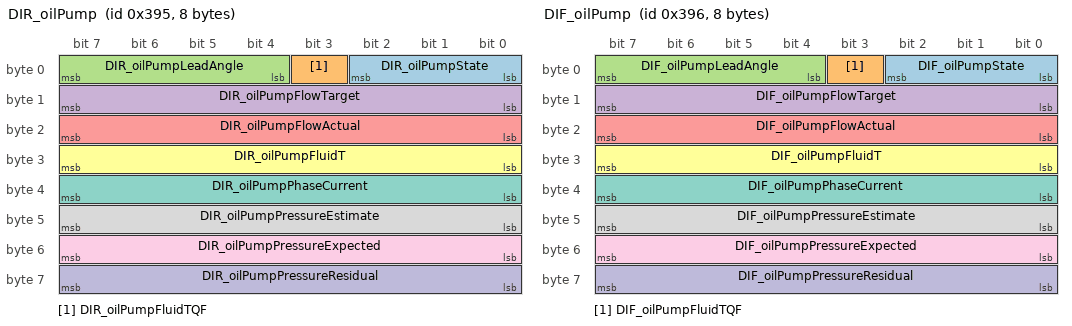
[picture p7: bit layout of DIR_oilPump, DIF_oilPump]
BO_ 917 DIR_oilPump: 8 Vector__XXX
 SG_ DIR_oilPumpState : 0|3@1+ (1,0) [0|0] "" Vector__XXX
 SG_ DIR_oilPumpFluidTQF : 3|1@1+ (1,0) [0|0] "" Vector__XXX
 SG_ DIR_oilPumpLeadAngle : 4|4@1+ (1.875,0) [0|0] "" Vector__XXX
 SG_ DIR_oilPumpFlowTarget : 8|8@1+ (0.1,0) [0|0] "" Vector__XXX
 SG_ DIR_oilPumpFlowActual : 16|8@1+ (0.1,0) [0|0] "" Vector__XXX
 SG_ DIR_oilPumpFluidT : 24|8@1+ (1,-40) [0|0] "" Vector__XXX
 SG_ DIR_oilPumpPhaseCurrent : 32|8@1+ (0.1,0) [0|0] "" Vector__XXX
 SG_ DIR_oilPumpPressureEstimate : 40|8@1+ (2,0) [0|0] "" Vector__XXX
 SG_ DIR_oilPumpPressureExpected : 48|8@1+ (2,0) [0|0] "" Vector__XXX
 SG_ DIR_oilPumpPressureResidual : 56|8@1+ (4,-500) [0|0] "" Vector__XXX

BO_ 918 DIF_oilPump: 8 Vector__XXX
 SG_ DIF_oilPumpState : 0|3@1+ (1,0) [0|0] "" Vector__XXX
 SG_ DIF_oilPumpFluidTQF : 3|1@1+ (1,0) [0|0] "" Vector__XXX
 SG_ DIF_oilPumpLeadAngle : 4|4@1+ (1.875,0) [0|0] "" Vector__XXX
 SG_ DIF_oilPumpFlowTarget : 8|8@1+ (0.1,0) [0|0] "" Vector__XXX
 SG_ DIF_oilPumpFlowActual : 16|8@1+ (0.1,0) [0|0] "" Vector__XXX
 SG_ DIF_oilPumpFluidT : 24|8@1+ (1,-40) [0|0] "" Vector__XXX
 SG_ DIF_oilPumpPhaseCurrent : 32|8@1+ (0.1,0) [0|0] "" Vector__XXX
 SG_ DIF_oilPumpPressureEstimate : 40|8@1+ (2,0) [0|0] "" Vector__XXX
 SG_ DIF_oilPumpPressureExpected : 48|8@1+ (2,0) [0|0] "" Vector__XXX
 SG_ DIF_oilPumpPressureResidual : 56|8@1+ (4,-500) [0|0] "" Vector__XXX

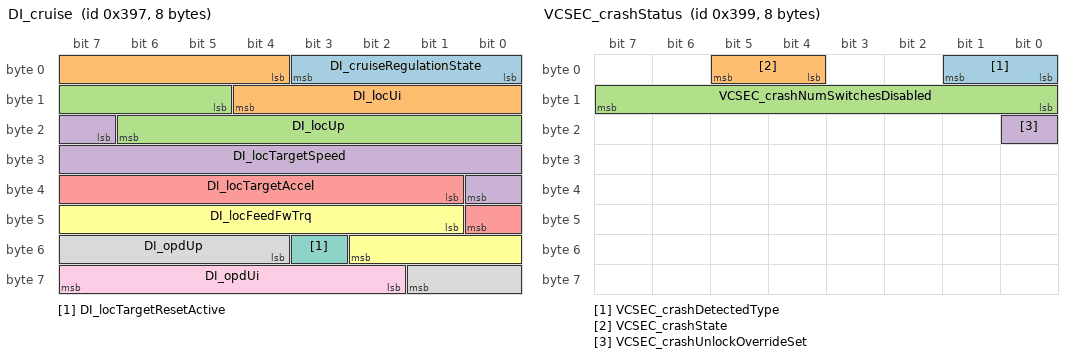
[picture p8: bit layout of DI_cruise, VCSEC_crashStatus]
BO_ 919 DI_cruise: 8 Vector__XXX
 SG_ DI_cruiseRegulationState : 0|4@1+ (1,0) [0|0] "" Vector__XXX
 SG_ DI_locUi : 4|9@1- (19.607843137254903,0) [0|0] "" Vector__XXX
 SG_ DI_locUp : 13|10@1- (19.569471624266146,0) [0|0] "" Vector__XXX
 SG_ DI_locTargetSpeed : 23|10@1- (0.25,20) [0|0] "" Vector__XXX
 SG_ DI_locTargetAccel : 33|8@1- (0.1094488188976378,-1.5322834645669292) [0|0] "" Vector__XXX
 SG_ DI_locFeedFwTrq : 41|10@1- (19.569471624266146,0) [0|0] "" Vector__XXX
 SG_ DI_locTargetResetActive : 51|1@1+ (1,0) [0|0] "" Vector__XXX
 SG_ DI_opdUp : 52|6@1- (40,0) [0|0] "" Vector__XXX
 SG_ DI_opdUi : 58|6@1- (40,0) [0|0] "" Vector__XXX

BO_ 921 VCSEC_crashStatus: 8 Vector__XXX
 SG_ VCSEC_crashDetectedType : 0|2@1+ (1,0) [0|0] "" Vector__XXX
 SG_ VCSEC_crashState : 4|2@1+ (1,0) [0|0] "" Vector__XXX
 SG_ VCSEC_crashNumSwitchesDisabled : 8|8@1+ (1,0) [0|0] "" Vector__XXX
 SG_ VCSEC_crashUnlockOverrideSet : 16|1@1+ (1,0) [0|0] "" Vector__XXX

BO_ 922 VCSEC_RSSI: 8 Vector__XXX
 SG_ VCSEC_RSSIIndex M : 0|2@1+ (1,0) [0|0] "" Vector__XXX
 SG_ VCSEC_centerBLEAntennaRSSI1 m1 : 2|8@1- (1,0) [0|0] "" Vector__XXX
 SG_ VCSEC_leftBLEAntennaRSSI0 m0 : 2|8@1- (1,0) [0|0] "" Vector__XXX
 SG_ VCSEC_leftBLEAntennaRSSI2 m1 : 10|8@1- (1,0) [0|0] "" Vector__XXX
 SG_ VCSEC_rightBLEAntennaRSSI0 m0 : 10|8@1- (1,0) [0|0] "" Vector__XXX
 SG_ VCSEC_rearBLEAntennaRSSI0 m0 : 18|8@1- (1,0) [0|0] "" Vector__XXX
 SG_ VCSEC_rightBLEAntennaRSSI2 m1 : 18|8@1- (1,0) [0|0] "" Vector__XXX
 SG_ VCSEC_centerBLEAntennaRSSI0 m0 : 26|8@1- (1,0) [0|0] "" Vector__XXX
 SG_ VCSEC_rearBLEAntennaRSSI2 m1 : 26|8@1- (1,0) [0|0] "" Vector__XXX
 SG_ VCSEC_centerBLEAntennaRSSI2 m1 : 34|8@1- (1,0) [0|0] "" Vector__XXX
 SG_ VCSEC_leftBLEAntennaRSSI1 m0 : 34|8@1- (1,0) [0|0] "" Vector__XXX
 SG_ VCSEC_BLEDevicePresence1 m1 : 42|5@1+ (1,0) [0|0] "" Vector__XXX
 SG_ VCSEC_rightBLEAntennaRSSI1 m0 : 42|8@1- (1,0) [0|0] "" Vector__XXX
 SG_ VCSEC_BLEDevicePresence2 m1 : 47|5@1+ (1,0) [0|0] "" Vector__XXX
 SG_ VCSEC_rearBLEAntennaRSSI1 m0 : 50|8@1- (1,0) [0|0] "" Vector__XXX
 SG_ VCSEC_BLEDevicePresence3 m1 : 52|5@1+ (1,0) [0|0] "" Vector__XXX
 SG_ VCSEC_RSSI0ConnectionType m1 : 57|2@1+ (1,0) [0|0] "" Vector__XXX
 SG_ VCSEC_UnknownBLEDevicePresent m0 : 58|1@1+ (1,0) [0|0] "" Vector__XXX
 SG_ VCSEC_BLEDevicePresence0 m0 : 59|5@1+ (1,0) [0|0] "" Vector__XXX
 SG_ VCSEC_RSSI1ConnectionType m1 : 59|2@1+ (1,0) [0|0] "" Vector__XXX
 SG_ VCSEC_RSSI2ConnectionType m1 : 61|2@1+ (1,0) [0|0] "" Vector__XXX

BO_ 923 DAS_status: 8 Vector__XXX
 SG_ DAS_autopilotState : 0|4@1+ (1,0) [0|0] "" Vector__XXX
 SG_ DAS_blindSpotRearLeft : 4|2@1+ (1,0) [0|0] "" Vector__XXX
 SG_ DAS_blindSpotRearRight : 6|2@1+ (1,0) [0|0] "" Vector__XXX
 SG_ DAS_fusedSpeedLimit : 8|5@1+ (5,0) [0|0] "" Vector__XXX
 SG_ DAS_suppressSpeedWarning : 13|1@1+ (1,0) [0|0] "" Vector__XXX
 SG_ DAS_summonObstacle : 14|1@1+ (1,0) [0|0] "" Vector__XXX
 SG_ DAS_summonClearedGate : 15|1@1+ (1,0) [0|0] "" Vector__XXX
 SG_ DAS_visionOnlySpeedLimit : 16|5@1+ (5,0) [0|0] "" Vector__XXX
 SG_ DAS_heaterState : 21|1@1+ (1,0) [0|0] "" Vector__XXX
 SG_ DAS_forwardCollisionWarning : 22|2@1+ (1,0) [0|0] "" Vector__XXX
 SG_ DAS_autoparkReady : 24|1@1+ (1,0) [0|0] "" Vector__XXX
 SG_ DAS_autoParked : 25|1@1+ (1,0) [0|0] "" Vector__XXX
 SG_ DAS_autoparkActive : 26|1@1+ (1,0) [0|0] "" Vector__XXX
 SG_ DAS_summonFwdLeashReached : 27|1@1+ (1,0) [0|0] "" Vector__XXX
 SG_ DAS_summonRvsLeashReached : 28|1@1+ (1,0) [0|0] "" Vector__XXX
 SG_ DAS_lssState : 29|3@1+ (1,0) [0|0] "" Vector__XXX
 SG_ DAS_sideCollisionAvoid : 32|2@1+ (1,0) [0|0] "" Vector__XXX
 SG_ DAS_sideCollisionWarning : 34|2@1+ (1,0) [0|0] "" Vector__XXX
 SG_ DAS_sideCollisionInhibit : 36|1@1+ (1,0) [0|0] "" Vector__XXX
 SG_ DAS_laneDepartureWarning : 37|3@1+ (1,0) [0|0] "" Vector__XXX
 SG_ DAS_fleetSpeedState : 40|2@1+ (1,0) [0|0] "" Vector__XXX
 SG_ DAS_autopilotHandsOnState : 42|4@1+ (1,0) [0|0] "" Vector__XXX
 SG_ DAS_autoLaneChangeState : 46|5@1+ (1,0) [0|0] "" Vector__XXX
 SG_ DAS_summonAvailable : 51|1@1+ (1,0) [0|0] "" Vector__XXX
 SG_ DAS_statusCounter : 52|4@1+ (1,0) [0|0] "" Vector__XXX
 SG_ DAS_statusChecksum : 56|8@1+ (1,0) [0|0] "" Vector__XXX

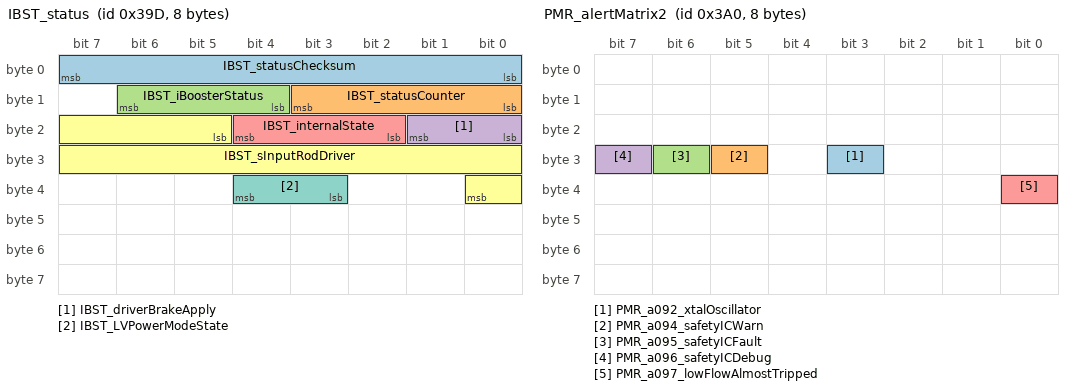
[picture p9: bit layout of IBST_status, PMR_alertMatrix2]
BO_ 925 IBST_status: 8 Vector__XXX
 SG_ IBST_statusChecksum : 0|8@1+ (1,0) [0|0] "" Vector__XXX
 SG_ IBST_statusCounter : 8|4@1+ (1,0) [0|0] "" Vector__XXX
 SG_ IBST_iBoosterStatus : 12|3@1+ (1,0) [0|0] "" Vector__XXX
 SG_ IBST_driverBrakeApply : 16|2@1+ (1,0) [0|0] "" Vector__XXX
 SG_ IBST_internalState : 18|3@1+ (1,0) [0|0] "" Vector__XXX
 SG_ IBST_sInputRodDriver : 21|12@1+ (0.015625,-5) [0|0] "" Vector__XXX
 SG_ IBST_LVPowerModeState : 35|2@1+ (1,0) [0|0] "" Vector__XXX

BO_ 927 FC_alertMatrix4: 8 Vector__XXX
 SG_ FC_a193_FCAlertPlaceholder : 0|1@1+ (1,0) [0|0] "" Vector__XXX

BO_ 928 PMR_alertMatrix2: 8 Vector__XXX
 SG_ PMR_a092_xtalOscillator : 27|1@1+ (1,0) [0|0] "" Vector__XXX
 SG_ PMR_a094_safetyICWarn : 29|1@1+ (1,0) [0|0] "" Vector__XXX
 SG_ PMR_a095_safetyICFault : 30|1@1+ (1,0) [0|0] "" Vector__XXX
 SG_ PMR_a096_safetyICDebug : 31|1@1+ (1,0) [0|0] "" Vector__XXX
 SG_ PMR_a097_lowFlowAlmostTripped : 32|1@1+ (1,0) [0|0] "" Vector__XXX

BO_ 929 VCFRONT_vehicleStatus: 8 Vector__XXX
 SG_ VCFRONT_vehicleStatusMuxIndex M : 0|1@1+ (1,0) [0|0] "" Vector__XXX
 SG_ VCFRONT_bmsHvChargeEnable m1 : 1|1@1+ (1,0) [0|0] "" Vector__XXX
 SG_ VCFRONT_preconditionRequest m0 : 1|1@1+ (1,0) [0|0] "" Vector__XXX
 SG_ VCFRONT_3RowLeftUnbuckled m1 : 2|2@1+ (1,0) [0|0] "" Vector__XXX
 SG_ VCFRONT_APGlassHeaterState m0 : 2|3@1+ (1,0) [0|0] "" Vector__XXX
 SG_ VCFRONT_3RowRightUnbuckled m1 : 4|2@1+ (1,0) [0|0] "" Vector__XXX
 SG_ VCFRONT_thermalSystemType m0 : 5|1@1+ (1,0) [0|0] "" Vector__XXX
 SG_ VCFRONT_maxBattHeatRejection m1 : 6|10@1+ (30,0) [0|0] "" Vector__XXX
 SG_ VCFRONT_standbySupplySupported m0 : 6|1@1+ (1,0) [0|0] "" Vector__XXX
 SG_ VCFRONT_driverPresent m0 : 7|1@1+ (1,0) [0|0] "" Vector__XXX
 SG_ VCFRONT_passengerPresent m0 : 8|1@1+ (1,0) [0|0] "" Vector__XXX
 SG_ VCFRONT_accPlusAvailable m0 : 9|1@1+ (1,0) [0|0] "" Vector__XXX
 SG_ VCFRONT_diPowerOnState m0 : 10|3@1+ (1,0) [0|0] "" Vector__XXX
 SG_ VCFRONT_12vStatusForDrive m0 : 14|2@1+ (1,0) [0|0] "" Vector__XXX
 SG_ VCFRONT_dcr12VMilliOhms m0 : 16|8@1+ (1,0) [0|0] "" Vector__XXX
 SG_ VCFRONT_hvacReqBattCoolOutTemp m1 : 16|9@1+ (0.1,40) [0|0] "" Vector__XXX
 SG_ VC_userPresenceState m0 : 24|2@1+ (1,0) [0|0] "" Vector__XXX
 SG_ VCFRONT_PCSCurrent m1 : 25|13@1- (0.1,0) [0|0] "" Vector__XXX
 SG_ VCFRONT_factoryLimitsOverrideOk m0 : 27|1@1+ (1,0) [0|0] "" Vector__XXX
 SG_ VCFRONT_ota12VSupportRequest m0 : 29|1@1+ (1,0) [0|0] "" Vector__XXX
 SG_ VCFRONT_driverBuckleStatus m0 : 30|1@1+ (1,0) [0|0] "" Vector__XXX
 SG_ VCFRONT_driverDoorStatus m0 : 31|1@1+ (1,0) [0|0] "" Vector__XXX
 SG_ VCFRONT_driverUnbuckled m0 : 32|2@1+ (1,0) [0|0] "" Vector__XXX
 SG_ VCFRONT_passengerUnbuckled m0 : 34|2@1+ (1,0) [0|0] "" Vector__XXX
 SG_ VCFRONT_2RowLeftUnbuckled m0 : 36|2@1+ (1,0) [0|0] "" Vector__XXX
 SG_ VCFRONT_2RowCenterUnbuckled m0 : 38|2@1+ (1,0) [0|0] "" Vector__XXX
 SG_ VCFRONT_refSystemNominal m1 : 38|1@1+ (1,0) [0|0] "" Vector__XXX
 SG_ VCFRONT_driverEnteredCabinEstimateDBG m1 : 39|1@1+ (1,0) [0|0] "" Vector__XXX
 SG_ VCFRONT_2RowRightUnbuckled m0 : 40|2@1+ (1,0) [0|0] "" Vector__XXX
 SG_ VCFRONT_anySWEFuseActive m1 : 40|1@1+ (1,0) [0|0] "" Vector__XXX
 SG_ VCFRONT_hpBattHeatingPowerTrgt m1 : 41|7@1+ (100,0) [0|0] "" Vector__XXX
 SG_ VCFRONT_pcsEFuseVoltage m0 : 42|10@1+ (0.1,0) [0|0] "" Vector__XXX
 SG_ VCFRONT_vehicleStatusCounter : 52|4@1+ (1,0) [0|0] "" Vector__XXX
 SG_ VCFRONT_vehicleStatusChecksum : 56|8@1+ (1,0) [0|0] "" Vector__XXX

BO_ 930 VCLEFT_status: 8 Vector__XXX
 SG_ VCLEFT_statusIndex M : 0|2@1+ (1,0) [0|0] "" Vector__XXX
 SG_ VCLEFT_pcbaTemperature m2 : 4|11@1+ (0.125,-40) [0|0] "" Vector__XXX
 SG_ VCLEFT_securityControllerEnable m0 : 5|1@1+ (1,0) [0|0] "" Vector__XXX
 SG_ VCLEFT_securityControllerVoltage m0 : 6|5@1+ (0.625,0) [0|0] "" Vector__XXX
 SG_ VCLEFT_consoleDoorAssist m0 : 11|1@1+ (1,0) [0|0] "" Vector__XXX
 SG_ VCLEFT_OTAState m0 : 12|1@1+ (1,0) [0|0] "" Vector__XXX
 SG_ VCLEFT_rationalityAggregateCurrent m1 : 12|8@1+ (0.5,0) [0|0] "" Vector__XXX
 SG_ VCLEFT_5AVoltage m0 : 13|10@1+ (0.005443676098,0) [0|0] "" Vector__XXX
 SG_ VCLEFT_swcHeatPwr m2 : 15|9@1+ (0.5,0) [0|0] "" Vector__XXX
 SG_ VCLEFT_LVBatteryTypeDBG m1 : 20|3@1+ (1,0) [0|0] "" Vector__XXX
 SG_ VCLEFT_vbatProt m0 : 23|12@1+ (0.005443676098,0) [0|0] "" Vector__XXX
 SG_ VCLEFT_DIeFuseFault m1 : 24|1@1+ (1,0) [0|0] "" Vector__XXX
 SG_ VCLEFT_swcHeatDutyCycle m2 : 24|7@1+ (1,0) [0|0] "" Vector__XXX
 SG_ VCLEFT_eFuseMgmtVoltageMonitor m1 : 25|7@1+ (0.125,0) [0|0] "" Vector__XXX
 SG_ VCLEFT_DIeFuseCurrent m2 : 31|6@1+ (0.1,0) [0|0] "" Vector__XXX
 SG_ VCLEFT_trailerAuxCurrent m1 : 32|12@1+ (0.025,0) [0|0] "" Vector__XXX
 SG_ VCLEFT_footwellLightCurrent m0 : 35|12@1- (0.1,0) [0|0] "" Vector__XXX
 SG_ VCLEFT_SWCpresent m2 : 37|1@1+ (1,0) [0|0] "" Vector__XXX
 SG_ VCLEFT_swcHeatTmp m1 : 44|10@1+ (0.1,-35) [0|0] "" Vector__XXX
 SG_ VCLEFT_autonomyBehaviorStatus m2 : 46|2@1+ (1,0) [0|0] "" Vector__XXX
 SG_ VCLEFT_swcInputVoltage m0 : 47|8@1+ (0.1,0) [0|0] "" Vector__XXX
 SG_ VCLEFT_swcHeatStatus m1 : 54|3@1+ (1,0) [0|0] "" Vector__XXX
 SG_ VCLEFT_swcPCBATemperature m0 : 55|8@1- (1,68) [0|0] "" Vector__XXX
 SG_ VCLEFT_swcHeatInhibited m1 : 57|1@1+ (1,0) [0|0] "" Vector__XXX
 SG_ VCLEFT_obdEthernetActive m0 : 63|1@1+ (1,0) [0|0] "" Vector__XXX

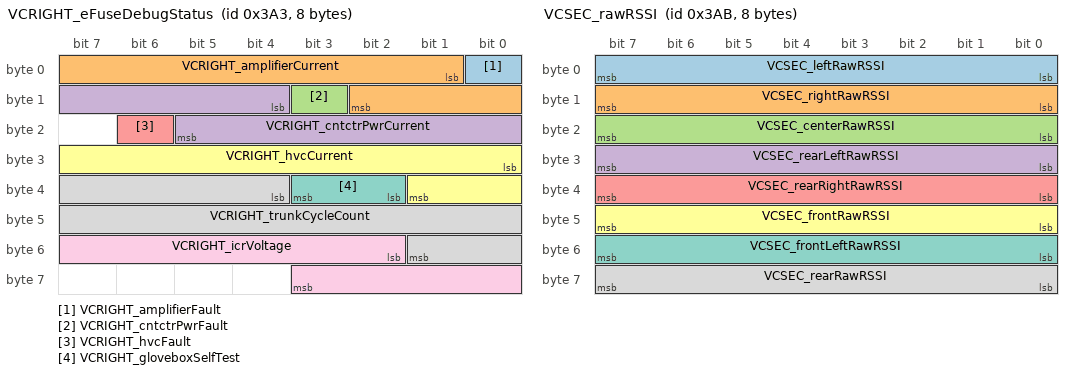
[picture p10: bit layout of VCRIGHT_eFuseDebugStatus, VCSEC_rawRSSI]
BO_ 931 VCRIGHT_eFuseDebugStatus: 8 Vector__XXX
 SG_ VCRIGHT_amplifierFault : 0|1@1+ (1,0) [0|0] "" Vector__XXX
 SG_ VCRIGHT_amplifierCurrent : 1|10@1+ (0.1,0) [0|0] "" Vector__XXX
 SG_ VCRIGHT_cntctrPwrFault : 11|1@1+ (1,0) [0|0] "" Vector__XXX
 SG_ VCRIGHT_cntctrPwrCurrent : 12|10@1+ (0.1,0) [0|0] "" Vector__XXX
 SG_ VCRIGHT_hvcFault : 22|1@1+ (1,0) [0|0] "" Vector__XXX
 SG_ VCRIGHT_hvcCurrent : 24|10@1+ (0.1,0) [0|0] "" Vector__XXX
 SG_ VCRIGHT_gloveboxSelfTest : 34|2@1+ (1,0) [0|0] "" Vector__XXX
 SG_ VCRIGHT_trunkCycleCount : 36|14@1+ (10,0) [0|0] "" Vector__XXX
 SG_ VCRIGHT_icrVoltage : 50|10@1+ (0.02,0) [0|0] "" Vector__XXX

BO_ 932 PCS_alertMatrix: 8 Vector__XXX
 SG_ PCS_matrixIndex M : 0|4@1+ (1,0) [0|0] "" Vector__XXX
 SG_ PCS_a001_chgHwInputOc m0 : 4|1@1+ (1,0) [0|0] "" Vector__XXX
 SG_ PCS_a061_chgVLineRationality m1 : 4|1@1+ (1,0) [0|0] "" Vector__XXX
 SG_ PCS_a002_chgHwOutputOc m0 : 5|1@1+ (1,0) [0|0] "" Vector__XXX
 SG_ PCS_a062_chgILineRationality m1 : 5|1@1+ (1,0) [0|0] "" Vector__XXX
 SG_ PCS_a003_chgHwInputOv m0 : 6|1@1+ (1,0) [0|0] "" Vector__XXX
 SG_ PCS_a063_chgVOutRationality m1 : 6|1@1+ (1,0) [0|0] "" Vector__XXX
 SG_ PCS_a004_chgHwIntBusOv m0 : 7|1@1+ (1,0) [0|0] "" Vector__XXX
 SG_ PCS_a064_chgIOutRationality m1 : 7|1@1+ (1,0) [0|0] "" Vector__XXX
 SG_ PCS_a005_chgOutputOv m0 : 8|1@1+ (1,0) [0|0] "" Vector__XXX
 SG_ PCS_a065_chgPllNotLocked m1 : 8|1@1+ (1,0) [0|0] "" Vector__XXX
 SG_ PCS_a006_chgPrechargeFailedScr m0 : 9|1@1+ (1,0) [0|0] "" Vector__XXX
 SG_ PCS_a066_dcdcHvRationality m1 : 9|1@1+ (1,0) [0|0] "" Vector__XXX
 SG_ PCS_a007_chgPhaseTempHot m0 : 10|1@1+ (1,0) [0|0] "" Vector__XXX
 SG_ PCS_a067_dcdcLvRationality m1 : 10|1@1+ (1,0) [0|0] "" Vector__XXX
 SG_ PCS_a008_chgPhaseOverTemp m0 : 11|1@1+ (1,0) [0|0] "" Vector__XXX
 SG_ PCS_a068_dcdcTankvRationality m1 : 11|1@1+ (1,0) [0|0] "" Vector__XXX
 SG_ PCS_a009_chgPfcCurrentRegulation m0 : 12|1@1+ (1,0) [0|0] "" Vector__XXX
 SG_ PCS_a069_chgPfcLineDidt m1 : 12|1@1+ (1,0) [0|0] "" Vector__XXX
 SG_ PCS_a010_chgIntBusVRegulation m0 : 13|1@1+ (1,0) [0|0] "" Vector__XXX
 SG_ PCS_a070_chgPfcLineDvdt m1 : 13|1@1+ (1,0) [0|0] "" Vector__XXX
 SG_ PCS_a011_chgLlcCurrentRegulation m0 : 14|1@1+ (1,0) [0|0] "" Vector__XXX
 SG_ PCS_a071_chgPfcILoopRationality m1 : 14|1@1+ (1,0) [0|0] "" Vector__XXX
 SG_ PCS_a012_chgPfcIBandTracerFault m0 : 15|1@1+ (1,0) [0|0] "" Vector__XXX
 SG_ PCS_a072_cpu2ClaStopped m1 : 15|1@1+ (1,0) [0|0] "" Vector__XXX
 SG_ PCS_a013_chgPrechargeFailedBoost m0 : 16|1@1+ (1,0) [0|0] "" Vector__XXX
 SG_ PCS_a073_unexpectedAcInputVoltage m1 : 16|1@1+ (1,0) [0|0] "" Vector__XXX
 SG_ PCS_a014_chgTempRationality m0 : 17|1@1+ (1,0) [0|0] "" Vector__XXX
 SG_ PCS_a074_hvBusDischargeFailure m1 : 17|1@1+ (1,0) [0|0] "" Vector__XXX
 SG_ PCS_a015_chg12vUv m0 : 18|1@1+ (1,0) [0|0] "" Vector__XXX
 SG_ PCS_a075_hvBusDischargeTimeout m1 : 18|1@1+ (1,0) [0|0] "" Vector__XXX
 SG_ PCS_a016_chgAllPhasesFaulted m0 : 19|1@1+ (1,0) [0|0] "" Vector__XXX
 SG_ PCS_a076_dcdcEnDeassertedErr m1 : 19|1@1+ (1,0) [0|0] "" Vector__XXX
 SG_ PCS_a017_chgWallPowerRemoval m0 : 20|1@1+ (1,0) [0|0] "" Vector__XXX
 SG_ PCS_a077_microGridWobbleDetected m1 : 20|1@1+ (1,0) [0|0] "" Vector__XXX
 SG_ PCS_a018_chgUnknownGridConfig m0 : 21|1@1+ (1,0) [0|0] "" Vector__XXX
 SG_ PCS_a078_chgStopDcdcTooHot m1 : 21|1@1+ (1,0) [0|0] "" Vector__XXX
 SG_ PCS_a019_acChargePowerLimited m0 : 22|1@1+ (1,0) [0|0] "" Vector__XXX
 SG_ PCS_a079_eepromOperationError m1 : 22|1@1+ (1,0) [0|0] "" Vector__XXX
 SG_ PCS_a020_chgEnableLineMismatch m0 : 23|1@1+ (1,0) [0|0] "" Vector__XXX
 SG_ PCS_a080_damagedPhaseDetected m1 : 23|1@1+ (1,0) [0|0] "" Vector__XXX
 SG_ PCS_a021_hvpMia m0 : 24|1@1+ (1,0) [0|0] "" Vector__XXX
 SG_ PCS_a081_dcdcPchgTimeout m1 : 24|1@1+ (1,0) [0|0] "" Vector__XXX
 SG_ PCS_a022_bmsMia m0 : 25|1@1+ (1,0) [0|0] "" Vector__XXX
 SG_ PCS_a082_dcdcPchgUnsafeDiVoltage m1 : 25|1@1+ (1,0) [0|0] "" Vector__XXX
 SG_ PCS_a023_cpMia m0 : 26|1@1+ (1,0) [0|0] "" Vector__XXX
 SG_ PCS_a083_triggerOdin m1 : 26|1@1+ (1,0) [0|0] "" Vector__XXX
 SG_ PCS_a024_vcfrontMia m0 : 27|1@1+ (1,0) [0|0] "" Vector__XXX
 SG_ PCS_a084_vDropFastInParasiticDiodeRegion m1 : 27|1@1+ (1,0) [0|0] "" Vector__XXX
 SG_ PCS_a025_cpu2Malfunction m0 : 28|1@1+ (1,0) [0|0] "" Vector__XXX
 SG_ PCS_a085_dcdcFetsNotSwitching m1 : 28|1@1+ (1,0) [0|0] "" Vector__XXX
 SG_ PCS_a026_watchdogAlarmed m0 : 29|1@1+ (1,0) [0|0] "" Vector__XXX
 SG_ PCS_a086_dcdcInsufficientCooling m1 : 29|1@1+ (1,0) [0|0] "" Vector__XXX
 SG_ PCS_a027_chgInsufficientCooling m0 : 30|1@1+ (1,0) [0|0] "" Vector__XXX
 SG_ PCS_a087_nvramRecordStatusError m1 : 30|1@1+ (1,0) [0|0] "" Vector__XXX
 SG_ PCS_a028_chgOutputUv m0 : 31|1@1+ (1,0) [0|0] "" Vector__XXX
 SG_ PCS_a088_gridFreqDroopDetected m1 : 31|1@1+ (1,0) [0|0] "" Vector__XXX
 SG_ PCS_a029_chgPowerRationality m0 : 32|1@1+ (1,0) [0|0] "" Vector__XXX
 SG_ PCS_a089_hvBusDischargeIrrational m1 : 32|1@1+ (1,0) [0|0] "" Vector__XXX
 SG_ PCS_a030_canRationality m0 : 33|1@1+ (1,0) [0|0] "" Vector__XXX
 SG_ PCS_a090_expectedAcVoltageSourceMissing m1 : 33|1@1+ (1,0) [0|0] "" Vector__XXX
 SG_ PCS_a031_uiMia m0 : 34|1@1+ (1,0) [0|0] "" Vector__XXX
 SG_ PCS_a091_chgIntBusRationality m1 : 34|1@1+ (1,0) [0|0] "" Vector__XXX
 SG_ PCS_a032_excessiveGridTransientsDetected m0 : 35|1@1+ (1,0) [0|0] "" Vector__XXX
 SG_ PCS_a092_chgPowerLimitedByBusRipple m1 : 35|1@1+ (1,0) [0|0] "" Vector__XXX
 SG_ PCS_a033_hvBusUv m0 : 36|1@1+ (1,0) [0|0] "" Vector__XXX
 SG_ PCS_a093_powerRailRationality m1 : 36|1@1+ (1,0) [0|0] "" Vector__XXX
 SG_ PCS_a034_hvBusOv m0 : 37|1@1+ (1,0) [0|0] "" Vector__XXX
 SG_ PCS_a094_pcsDcdcNeedService m1 : 37|1@1+ (1,0) [0|0] "" Vector__XXX
 SG_ PCS_a035_lvBusUv m0 : 38|1@1+ (1,0) [0|0] "" Vector__XXX
 SG_ PCS_a095_dcdcSensorlessModeActive m1 : 38|1@1+ (1,0) [0|0] "" Vector__XXX
 SG_ PCS_a036_lvBusOv m0 : 39|1@1+ (1,0) [0|0] "" Vector__XXX
 SG_ PCS_a096_microGridOverLoaded m1 : 39|1@1+ (1,0) [0|0] "" Vector__XXX
 SG_ PCS_a037_resonantTankOc m0 : 40|1@1+ (1,0) [0|0] "" Vector__XXX
 SG_ PCS_a097_rebootPhaseDetected m1 : 40|1@1+ (1,0) [0|0] "" Vector__XXX
 SG_ PCS_a038_claFaulted m0 : 41|1@1+ (1,0) [0|0] "" Vector__XXX
 SG_ PCS_a098_gridFreqDroopDetectedSilent m1 : 41|1@1+ (1,0) [0|0] "" Vector__XXX
 SG_ PCS_a039_sdModuleClkFault m0 : 42|1@1+ (1,0) [0|0] "" Vector__XXX
 SG_ PCS_a099_microGridOverLoadedSilent m1 : 42|1@1+ (1,0) [0|0] "" Vector__XXX
 SG_ PCS_a040_dcdcMaxPowerReached m0 : 43|1@1+ (1,0) [0|0] "" Vector__XXX
 SG_ PCS_a100_suspectedViperChipIssue m1 : 43|1@1+ (1,0) [0|0] "" Vector__XXX
 SG_ PCS_a041_dcdcOverTemp m0 : 44|1@1+ (1,0) [0|0] "" Vector__XXX
 SG_ PCS_a101_phMachineModelIrrational m1 : 44|1@1+ (1,0) [0|0] "" Vector__XXX
 SG_ PCS_a042_dcdcEnableLineMismatch m0 : 45|1@1+ (1,0) [0|0] "" Vector__XXX
 SG_ PCS_a102_resetWithDCDCCmdAsserted m1 : 45|1@1+ (1,0) [0|0] "" Vector__XXX
 SG_ PCS_a043_hvBusPrechargeFailure m0 : 46|1@1+ (1,0) [0|0] "" Vector__XXX
 SG_ PCS_a103_pchgWithLowLvDetected m1 : 46|1@1+ (1,0) [0|0] "" Vector__XXX
 SG_ PCS_a044_12vSupportRegulation m0 : 47|1@1+ (1,0) [0|0] "" Vector__XXX
 SG_ PCS_a104_ambientTempRationality m1 : 47|1@1+ (1,0) [0|0] "" Vector__XXX
 SG_ PCS_a045_hvBusLowImpedance m0 : 48|1@1+ (1,0) [0|0] "" Vector__XXX
 SG_ PCS_a105_redundantVoltageSourceIrrational m1 : 48|1@1+ (1,0) [0|0] "" Vector__XXX
 SG_ PCS_a046_hvBusHighImpedence m0 : 49|1@1+ (1,0) [0|0] "" Vector__XXX
 SG_ PCS_a106_clockSourceNotFromExternalCrystal m1 : 49|1@1+ (1,0) [0|0] "" Vector__XXX
 SG_ PCS_a047_bootloaderCrcMismatch m0 : 50|1@1+ (1,0) [0|0] "" Vector__XXX
 SG_ PCS_a107_vcPcsDCDCInterfaceMia m1 : 50|1@1+ (1,0) [0|0] "" Vector__XXX
 SG_ PCS_a048_softwareAssertion m0 : 51|1@1+ (1,0) [0|0] "" Vector__XXX
 SG_ PCS_a108_misconfigurationDetected m1 : 51|1@1+ (1,0) [0|0] "" Vector__XXX
 SG_ PCS_a049_dcdcTempRationality m0 : 52|1@1+ (1,0) [0|0] "" Vector__XXX
 SG_ PCS_a109_deltaChargingL2L3SwappedDetected m1 : 52|1@1+ (1,0) [0|0] "" Vector__XXX
 SG_ PCS_a050_dcdc12VsupportFaulted m0 : 53|1@1+ (1,0) [0|0] "" Vector__XXX
 SG_ PCS_d110_dcdcNeedsService m1 : 53|1@1+ (1,0) [0|0] "" Vector__XXX
 SG_ PCS_a051_chgIntBusUv m0 : 54|1@1+ (1,0) [0|0] "" Vector__XXX
 SG_ PCS_d111_batteryChargerPowerLimited m1 : 54|1@1+ (1,0) [0|0] "" Vector__XXX
 SG_ PCS_a052_acVoltageNotPresent m0 : 55|1@1+ (1,0) [0|0] "" Vector__XXX
 SG_ PCS_d112_logicHardwareIssue m1 : 55|1@1+ (1,0) [0|0] "" Vector__XXX
 SG_ PCS_a053_chgInputVDropHigh m0 : 56|1@1+ (1,0) [0|0] "" Vector__XXX
 SG_ PCS_d113_dcdcConverterTempSensorAIssue m1 : 56|1@1+ (1,0) [0|0] "" Vector__XXX
 SG_ PCS_a054_chgInputVDropTooHigh m0 : 57|1@1+ (1,0) [0|0] "" Vector__XXX
 SG_ PCS_d114_dcdcConverterVoltSensorAIssue m1 : 57|1@1+ (1,0) [0|0] "" Vector__XXX
 SG_ PCS_a055_chgLineImpedanceHigh m0 : 58|1@1+ (1,0) [0|0] "" Vector__XXX
 SG_ PCS_d115_dcdcConverterTempSensorBIssue m1 : 58|1@1+ (1,0) [0|0] "" Vector__XXX
 SG_ PCS_a056_chgLineImpedanceTooHigh m0 : 59|1@1+ (1,0) [0|0] "" Vector__XXX
 SG_ PCS_d116_dcdcConverterVoltSensorBIssue m1 : 59|1@1+ (1,0) [0|0] "" Vector__XXX
 SG_ PCS_a057_chgInputOverFreq m0 : 60|1@1+ (1,0) [0|0] "" Vector__XXX
 SG_ PCS_a058_chgInputUnderFreq m0 : 61|1@1+ (1,0) [0|0] "" Vector__XXX
 SG_ PCS_a059_chgInputOvRms m0 : 62|1@1+ (1,0) [0|0] "" Vector__XXX
 SG_ PCS_a060_chgInputOvPeak m0 : 63|1@1+ (1,0) [0|0] "" Vector__XXX

BO_ 935 DIR_alertMatrix1: 8 Vector__XXX
 SG_ DIR_a001_hwPhaseAgateDrive : 0|1@1+ (1,0) [0|0] "" Vector__XXX
 SG_ DIR_a002_hwPhaseBgateDrive : 1|1@1+ (1,0) [0|0] "" Vector__XXX
 SG_ DIR_a003_hwPhaseCgateDrive : 2|1@1+ (1,0) [0|0] "" Vector__XXX
 SG_ DIR_a004_hwPhaseApeak : 3|1@1+ (1,0) [0|0] "" Vector__XXX
 SG_ DIR_a005_hwPhaseBpeak : 4|1@1+ (1,0) [0|0] "" Vector__XXX
 SG_ DIR_a006_hwPhaseCpeak : 5|1@1+ (1,0) [0|0] "" Vector__XXX
 SG_ DIR_a007_statorAnomalyDetected : 6|1@1+ (1,0) [0|0] "" Vector__XXX
 SG_ DIR_a008_hwEncoderA : 7|1@1+ (1,0) [0|0] "" Vector__XXX
 SG_ DIR_a009_hwEncoderB : 8|1@1+ (1,0) [0|0] "" Vector__XXX
 SG_ DIR_a010_unintendedReset : 9|1@1+ (1,0) [0|0] "" Vector__XXX
 SG_ DIR_a011_swPowerStageNotReady : 10|1@1+ (1,0) [0|0] "" Vector__XXX
 SG_ DIR_a013_eccError : 12|1@1+ (1,0) [0|0] "" Vector__XXX
 SG_ DIR_a014_activeDamping : 13|1@1+ (1,0) [0|0] "" Vector__XXX
 SG_ DIR_a015_mechSafeStateAnomaly : 14|1@1+ (1,0) [0|0] "" Vector__XXX
 SG_ DIR_a016_safeStateApplied : 15|1@1+ (1,0) [0|0] "" Vector__XXX
 SG_ DIR_a017_hwPedalMonitor : 16|1@1+ (1,0) [0|0] "" Vector__XXX
 SG_ DIR_a018_hwLVSupplyUV : 17|1@1+ (1,0) [0|0] "" Vector__XXX
 SG_ DIR_a020_hwMotorEncoder : 19|1@1+ (1,0) [0|0] "" Vector__XXX
 SG_ DIR_a021_hwBusOV : 20|1@1+ (1,0) [0|0] "" Vector__XXX
 SG_ DIR_a022_hw5vSupplyUV : 21|1@1+ (1,0) [0|0] "" Vector__XXX
 SG_ DIR_a024_selfTest : 23|1@1+ (1,0) [0|0] "" Vector__XXX
 SG_ DIR_a025_phaseApeak : 24|1@1+ (1,0) [0|0] "" Vector__XXX
 SG_ DIR_a026_phaseBpeak : 25|1@1+ (1,0) [0|0] "" Vector__XXX
 SG_ DIR_a027_phaseCpeak : 26|1@1+ (1,0) [0|0] "" Vector__XXX
 SG_ DIR_a028_phaseArms : 27|1@1+ (1,0) [0|0] "" Vector__XXX
 SG_ DIR_a029_phaseBrms : 28|1@1+ (1,0) [0|0] "" Vector__XXX
 SG_ DIR_a030_phaseCrms : 29|1@1+ (1,0) [0|0] "" Vector__XXX
 SG_ DIR_a031_phaseAcurrentOffset : 30|1@1+ (1,0) [0|0] "" Vector__XXX
 SG_ DIR_a032_phaseBcurrentOffset : 31|1@1+ (1,0) [0|0] "" Vector__XXX
 SG_ DIR_a033_phaseAcurrentSensor : 32|1@1+ (1,0) [0|0] "" Vector__XXX
 SG_ DIR_a034_phaseBcurrentSensor : 33|1@1+ (1,0) [0|0] "" Vector__XXX
 SG_ DIR_a035_phaseCurrentBalance : 34|1@1+ (1,0) [0|0] "" Vector__XXX
 SG_ DIR_a036_busOV : 35|1@1+ (1,0) [0|0] "" Vector__XXX
 SG_ DIR_a037_busUV : 36|1@1+ (1,0) [0|0] "" Vector__XXX
 SG_ DIR_a038_busVsensor : 37|1@1+ (1,0) [0|0] "" Vector__XXX
 SG_ DIR_a040_difMIA : 39|1@1+ (1,0) [0|0] "" Vector__XXX
 SG_ DIR_a041_sdcMIA : 40|1@1+ (1,0) [0|0] "" Vector__XXX
 SG_ DIR_a042_inletSensor : 41|1@1+ (1,0) [0|0] "" Vector__XXX
 SG_ DIR_a043_outletOT : 42|1@1+ (1,0) [0|0] "" Vector__XXX
 SG_ DIR_a044_outletUT : 43|1@1+ (1,0) [0|0] "" Vector__XXX
 SG_ DIR_a045_outletSensor : 44|1@1+ (1,0) [0|0] "" Vector__XXX
 SG_ DIR_a046_statorOT : 45|1@1+ (1,0) [0|0] "" Vector__XXX
 SG_ DIR_a047_statorSensor1 : 46|1@1+ (1,0) [0|0] "" Vector__XXX
 SG_ DIR_a048_statorSensor2 : 47|1@1+ (1,0) [0|0] "" Vector__XXX
 SG_ DIR_a049_statorSensorDiff : 48|1@1+ (1,0) [0|0] "" Vector__XXX
 SG_ DIR_a050_noStatorSensor : 49|1@1+ (1,0) [0|0] "" Vector__XXX
 SG_ DIR_a052_dirMIA : 51|1@1+ (1,0) [0|0] "" Vector__XXX
 SG_ DIR_a053_unexpectedLatchState : 52|1@1+ (1,0) [0|0] "" Vector__XXX
 SG_ DIR_a054_driveInverterOT : 53|1@1+ (1,0) [0|0] "" Vector__XXX
 SG_ DIR_a055_trqCrossCheck : 54|1@1+ (1,0) [0|0] "" Vector__XXX
 SG_ DIR_a056_ambientOT : 55|1@1+ (1,0) [0|0] "" Vector__XXX
 SG_ DIR_a057_ambientUT : 56|1@1+ (1,0) [0|0] "" Vector__XXX
 SG_ DIR_a058_ambientSensor : 57|1@1+ (1,0) [0|0] "" Vector__XXX
 SG_ DIR_a059_heatsinkOT : 58|1@1+ (1,0) [0|0] "" Vector__XXX
 SG_ DIR_a060_heatsinkUT : 59|1@1+ (1,0) [0|0] "" Vector__XXX
 SG_ DIR_a061_heatsinkSensor : 60|1@1+ (1,0) [0|0] "" Vector__XXX
 SG_ DIR_a062_systemLimpMode : 61|1@1+ (1,0) [0|0] "" Vector__XXX
 SG_ DIR_a064_torqueIntervention : 63|1@1+ (1,0) [0|0] "" Vector__XXX

BO_ 936 VCLEFT_logging1Hz: 8 Vector__XXX
 SG_ VCLEFT_logging1HzIndex M : 0|3@1+ (1,0) [0|0] "" Vector__XXX
 SG_ VCLEFT_12vSocketFrontCurrentAvg m4 : 3|10@1+ (0.01,0) [0|0] "" Vector__XXX
 SG_ VCLEFT_rgbLedIPFLCurrent m3 : 3|10@1+ (0.0004887585532746823,0) [0|0] "" Vector__XXX
 SG_ VCLEFT_tailLightCurrent m2 : 3|4@1+ (0.1,0) [0|0] "" Vector__XXX
 SG_ VCLEFT_turnTailStopLightCurrent m2 : 7|4@1+ (0.1,0) [0|0] "" Vector__XXX
 SG_ VCLEFT_chargePortCurrent m1 : 8|6@1+ (0.05,0) [0|0] "" Vector__XXX
 SG_ VCLEFT_tohcPCBATemperature m0 : 8|8@1+ (1,-40) [0|0] "" Vector__XXX
 SG_ VCLEFT_stopReverseTurnLightCurrent m2 : 11|4@1+ (0.1,0) [0|0] "" Vector__XXX
 SG_ VCLEFT_12vSocketRearCurrentAvg m4 : 13|10@1+ (0.01,0) [0|0] "" Vector__XXX
 SG_ VCLEFT_rgbLedIPFRCurrent m3 : 13|10@1+ (0.0004887585532746823,0) [0|0] "" Vector__XXX
 SG_ VCLEFT_trunkInteriorLEDCurrent m2 : 15|4@1+ (5,0) [0|0] "" Vector__XXX
 SG_ VCLEFT_phoneChargingFL m0 : 16|1@1+ (1,0) [0|0] "" Vector__XXX
 SG_ VCLEFT_tlcCurrent m1 : 16|6@1+ (0.5,0) [0|0] "" Vector__XXX
 SG_ VCLEFT_phoneChargingFR m0 : 17|1@1+ (1,0) [0|0] "" Vector__XXX
 SG_ VCLEFT_windowSwitchLEDCurrent m2 : 19|3@1+ (10,0) [0|0] "" Vector__XXX
 SG_ VCLEFT_intDoorHandleLEDCurrent m2 : 22|3@1+ (2,0) [0|0] "" Vector__XXX
 SG_ VCLEFT_rgbLedIPFLOutput m3 : 23|1@1+ (1,0) [0|0] "" Vector__XXX
 SG_ VCLEFT_rcmCurrent m1 : 24|7@1+ (0.025,0) [0|0] "" Vector__XXX
 SG_ VCLEFT_rgbLedIPFROutput m3 : 24|1@1+ (1,0) [0|0] "" Vector__XXX
 SG_ VCLEFT_swcResistance m0 : 24|7@1+ (0.025,0) [0|0] "" Vector__XXX
 SG_ VCLEFT_usbPortsCurrentAvg m4 : 24|10@1+ (0.001,0) [0|0] "" Vector__XXX
 SG_ VCLEFT_mapPocketLEDsCurrent m2 : 25|3@1+ (10,0) [0|0] "" Vector__XXX
 SG_ VCLEFT_frontPuddleLEDCurrent m2 : 28|3@1+ (2,0) [0|0] "" Vector__XXX
 SG_ VCLEFT_rearPuddleLEDCurrent m2 : 31|3@1+ (2,0) [0|0] "" Vector__XXX
 SG_ VCLEFT_frontSeatHeatCushionPwr m0 : 32|7@1+ (1,0) [0|0] "" Vector__XXX
 SG_ VCLEFT_lumbarEcuCurrent m1 : 32|4@1+ (0.1,0) [0|0] "" Vector__XXX
 SG_ VCLEFT_trunkFoldFlatSwLEDCurrent m2 : 34|3@1+ (5,0) [0|0] "" Vector__XXX
 SG_ VCLEFT_usbPortsRearCurrentAvg m4 : 34|10@1+ (0.001,0) [0|0] "" Vector__XXX
 SG_ VCLEFT_bleBPillarRearHdlrCurrent m1 : 36|4@1+ (0.05,0) [0|0] "" Vector__XXX
 SG_ VCLEFT_accessoryFeed1Current m2 : 37|6@1+ (0.1,0) [0|0] "" Vector__XXX
 SG_ VCLEFT_frontSeatHeatBackrestPwr m0 : 40|7@1+ (1,0) [0|0] "" Vector__XXX
 SG_ VCLEFT_swcCurrent m1 : 40|8@1+ (0.05,0) [0|0] "" Vector__XXX
 SG_ VCLEFT_accessoryFeed2Current m2 : 43|5@1+ (0.2,0) [0|0] "" Vector__XXX
 SG_ VCLEFT_sccmCurrent m1 : 48|4@1+ (0.05,0) [0|0] "" Vector__XXX
 SG_ VCLEFT_vbatFused0Current m2 : 48|5@1+ (0.1,0) [0|0] "" Vector__XXX
 SG_ VCLEFT_dirDischargeCurrent m1 : 52|4@1+ (0.1,0) [0|0] "" Vector__XXX
 SG_ VCLEFT_vbatFused3Current m2 : 53|5@1+ (0.1,0) [0|0] "" Vector__XXX
 SG_ VCLEFT_sideMirrorCurrent m1 : 56|4@1+ (0.2,0) [0|0] "" Vector__XXX
 SG_ VCLEFT_ocsCurrent m2 : 58|3@1+ (0.01,0) [0|0] "" Vector__XXX
 SG_ VCLEFT_sideMirrorHeaterCurrent m1 : 60|4@1+ (0.5,0) [0|0] "" Vector__XXX
 SG_ VCLEFT_tpmsCurrent m2 : 61|3@1+ (0.01,0) [0|0] "" Vector__XXX

BO_ 938 HVP_alertMatrix: 8 Vector__XXX
 SG_ HVP_matrixIndex M : 0|4@1+ (1,0) [0|0] "" Vector__XXX
 SG_ HVP_w001_WatchdogReset m0 : 4|1@1+ (1,0) [0|0] "" Vector__XXX
 SG_ HVP_w061_ShuntCurrentRationality m1 : 4|1@1+ (1,0) [0|0] "" Vector__XXX
 SG_ HVP_w002_UnusedAlert2 m0 : 5|1@1+ (1,0) [0|0] "" Vector__XXX
 SG_ HVP_w062_BmbOtpConfigError m1 : 5|1@1+ (1,0) [0|0] "" Vector__XXX
 SG_ HVP_w003_SwAssertion m0 : 6|1@1+ (1,0) [0|0] "" Vector__XXX
 SG_ HVP_w063_BmbBrickVRationality m1 : 6|1@1+ (1,0) [0|0] "" Vector__XXX
 SG_ HVP_w004_CrashEvent m0 : 7|1@1+ (1,0) [0|0] "" Vector__XXX
 SG_ HVP_w064_BmbAuxVRationality m1 : 7|1@1+ (1,0) [0|0] "" Vector__XXX
 SG_ HVP_w005_OverDchgCurrentFault m0 : 8|1@1+ (1,0) [0|0] "" Vector__XXX
 SG_ HVP_w065_FastOpenVshDetected m1 : 8|1@1+ (1,0) [0|0] "" Vector__XXX
 SG_ HVP_w006_OverChargeCurrentFault m0 : 9|1@1+ (1,0) [0|0] "" Vector__XXX
 SG_ HVP_w007_OverCurrentFault m0 : 10|1@1+ (1,0) [0|0] "" Vector__XXX
 SG_ HVP_w067_HvilCalNodeMismatch m1 : 10|1@1+ (1,0) [0|0] "" Vector__XXX
 SG_ HVP_w008_OverTemperatureFault m0 : 11|1@1+ (1,0) [0|0] "" Vector__XXX
 SG_ HVP_w068_shuntUnexpectedThermistor m1 : 11|1@1+ (1,0) [0|0] "" Vector__XXX
 SG_ HVP_w009_OverVoltageFault m0 : 12|1@1+ (1,0) [0|0] "" Vector__XXX
 SG_ HVP_w069_hviCanFrameRxDropped m1 : 12|1@1+ (1,0) [0|0] "" Vector__XXX
 SG_ HVP_w010_UnderVoltageFault m0 : 13|1@1+ (1,0) [0|0] "" Vector__XXX
 SG_ HVP_w070_hvsCanFrameRxDropped m1 : 13|1@1+ (1,0) [0|0] "" Vector__XXX
 SG_ HVP_w011_PrimaryBmbMiaFault m0 : 14|1@1+ (1,0) [0|0] "" Vector__XXX
 SG_ HVP_w071_PassivePyroVrefRationality m1 : 14|1@1+ (1,0) [0|0] "" Vector__XXX
 SG_ HVP_w012_BmbDataIntegrityLoss m0 : 15|1@1+ (1,0) [0|0] "" Vector__XXX
 SG_ HVP_w013_BmbCommunication m0 : 16|1@1+ (1,0) [0|0] "" Vector__XXX
 SG_ HVP_w014_BmsMiaOnHviFault m0 : 17|1@1+ (1,0) [0|0] "" Vector__XXX
 SG_ HVP_w015_CpMiaFault m0 : 18|1@1+ (1,0) [0|0] "" Vector__XXX
 SG_ HVP_w016_PcsMiaFault m0 : 19|1@1+ (1,0) [0|0] "" Vector__XXX
 SG_ HVP_w017_GtwMiaFault m0 : 20|1@1+ (1,0) [0|0] "" Vector__XXX
 SG_ HVP_w018_powerCyclingPcs m0 : 21|1@1+ (1,0) [0|0] "" Vector__XXX
 SG_ HVP_w019_CpFault m0 : 22|1@1+ (1,0) [0|0] "" Vector__XXX
 SG_ HVP_w020_ShuntHwMiaFault m0 : 23|1@1+ (1,0) [0|0] "" Vector__XXX
 SG_ HVP_w021_PyroMiaFault m0 : 24|1@1+ (1,0) [0|0] "" Vector__XXX
 SG_ HVP_w022_PyroMiaWarning m0 : 25|1@1+ (1,0) [0|0] "" Vector__XXX
 SG_ HVP_w023_BmbResetRecovery m0 : 26|1@1+ (1,0) [0|0] "" Vector__XXX
 SG_ HVP_w024_Supply12vFault m0 : 27|1@1+ (1,0) [0|0] "" Vector__XXX
 SG_ HVP_w025_VerSupplyFault m0 : 28|1@1+ (1,0) [0|0] "" Vector__XXX
 SG_ HVP_w026_HvilFault m0 : 29|1@1+ (1,0) [0|0] "" Vector__XXX
 SG_ HVP_w027_BmsMiaOnHvsFault m0 : 30|1@1+ (1,0) [0|0] "" Vector__XXX
 SG_ HVP_w028_PackVoltMismatchFault m0 : 31|1@1+ (1,0) [0|0] "" Vector__XXX
 SG_ HVP_w029_EnsMiaFault m0 : 32|1@1+ (1,0) [0|0] "" Vector__XXX
 SG_ HVP_w030_PackPosCtrArcFault m0 : 33|1@1+ (1,0) [0|0] "" Vector__XXX
 SG_ HVP_w031_packNegCtrArcFault m0 : 34|1@1+ (1,0) [0|0] "" Vector__XXX
 SG_ HVP_w032_ShuntHwAndBmsMiaFault m0 : 35|1@1+ (1,0) [0|0] "" Vector__XXX
 SG_ HVP_w033_fcContHwFault m0 : 36|1@1+ (1,0) [0|0] "" Vector__XXX
 SG_ HVP_w034_cpMismatchFault m0 : 37|1@1+ (1,0) [0|0] "" Vector__XXX
 SG_ HVP_w035_packContHwFault m0 : 38|1@1+ (1,0) [0|0] "" Vector__XXX
 SG_ HVP_w036_pyroFuseBlown m0 : 39|1@1+ (1,0) [0|0] "" Vector__XXX
 SG_ HVP_w037_pyroFuseFailedToBlow m0 : 40|1@1+ (1,0) [0|0] "" Vector__XXX
 SG_ HVP_w038_CpilFault m0 : 41|1@1+ (1,0) [0|0] "" Vector__XXX
 SG_ HVP_w039_PackContactorFellOpen m0 : 42|1@1+ (1,0) [0|0] "" Vector__XXX
 SG_ HVP_w040_FcContactorFellOpen m0 : 43|1@1+ (1,0) [0|0] "" Vector__XXX
 SG_ HVP_w041_packCtrCloseBlocked m0 : 44|1@1+ (1,0) [0|0] "" Vector__XXX
 SG_ HVP_w042_fcCtrCloseBlocked m0 : 45|1@1+ (1,0) [0|0] "" Vector__XXX
 SG_ HVP_w043_packContactorForceOpen m0 : 46|1@1+ (1,0) [0|0] "" Vector__XXX
 SG_ HVP_w044_fcContactorForceOpen m0 : 47|1@1+ (1,0) [0|0] "" Vector__XXX
 SG_ HVP_w045_dcLinkOverVoltage m0 : 48|1@1+ (1,0) [0|0] "" Vector__XXX
 SG_ HVP_w046_shuntOverTemperature m0 : 49|1@1+ (1,0) [0|0] "" Vector__XXX
 SG_ HVP_w047_passivePyroDeploy m0 : 50|1@1+ (1,0) [0|0] "" Vector__XXX
 SG_ HVP_w048_swUnsupportedBmbAsicType m0 : 51|1@1+ (1,0) [0|0] "" Vector__XXX
 SG_ HVP_w049_packCtrCloseFailed m0 : 52|1@1+ (1,0) [0|0] "" Vector__XXX
 SG_ HVP_w050_fcCtrCloseFailed m0 : 53|1@1+ (1,0) [0|0] "" Vector__XXX
 SG_ HVP_w051_shuntThermistorMia m0 : 54|1@1+ (1,0) [0|0] "" Vector__XXX
 SG_ HVP_w052_BmbStatusRegError m0 : 55|1@1+ (1,0) [0|0] "" Vector__XXX
 SG_ HVP_w053_hvVoltageSensorRationality m0 : 56|1@1+ (1,0) [0|0] "" Vector__XXX
 SG_ HVP_w054_swMissingConfigBlock m0 : 57|1@1+ (1,0) [0|0] "" Vector__XXX
 SG_ HVP_w055_swMissingPartNumber m0 : 58|1@1+ (1,0) [0|0] "" Vector__XXX
 SG_ HVP_w056_contactorFailedToOpen m0 : 59|1@1+ (1,0) [0|0] "" Vector__XXX
 SG_ HVP_w057_BatmanDiagnosticsError m0 : 60|1@1+ (1,0) [0|0] "" Vector__XXX
 SG_ HVP_w058_BmbVrefBad m0 : 61|1@1+ (1,0) [0|0] "" Vector__XXX
 SG_ HVP_w059_BmbVrefWarning m0 : 62|1@1+ (1,0) [0|0] "" Vector__XXX
 SG_ HVP_w060_StackVoltageSense m0 : 63|1@1+ (1,0) [0|0] "" Vector__XXX

BO_ 939 VCSEC_rawRSSI: 8 Vector__XXX
 SG_ VCSEC_leftRawRSSI : 0|8@1- (1,0) [0|0] "" Vector__XXX
 SG_ VCSEC_rightRawRSSI : 8|8@1- (1,0) [0|0] "" Vector__XXX
 SG_ VCSEC_centerRawRSSI : 16|8@1- (1,0) [0|0] "" Vector__XXX
 SG_ VCSEC_rearLeftRawRSSI : 24|8@1- (1,0) [0|0] "" Vector__XXX
 SG_ VCSEC_rearRightRawRSSI : 32|8@1- (1,0) [0|0] "" Vector__XXX
 SG_ VCSEC_frontRawRSSI : 40|8@1- (1,0) [0|0] "" Vector__XXX
 SG_ VCSEC_frontLeftRawRSSI : 48|8@1- (1,0) [0|0] "" Vector__XXX
 SG_ VCSEC_rearRawRSSI : 56|8@1- (1,0) [0|0] "" Vector__XXX

BO_ 941 ICR_info: 8 Vector__XXX
 SG_ ICR_infoIndex M : 0|8@1+ (1,0) [0|0] "" Vector__XXX
 SG_ ICR_infoAppCrc m13 : 8|32@1+ (1,0) [0|0] "" Vector__XXX
 SG_ ICR_infoBoardPartNumber1520 m27 : 8|48@1+ (1,0) [0|0] "" Vector__XXX
 SG_ ICR_infoBoardPartNumber17 m25 : 8|56@1+ (1,0) [0|0] "" Vector__XXX
 SG_ ICR_infoBoardPartNumber814 m26 : 8|56@1+ (1,0) [0|0] "" Vector__XXX
 SG_ ICR_infoBuildType m10 : 8|3@1+ (1,0) [0|0] "" Vector__XXX
 SG_ ICR_infoPcbaId m11 : 32|8@1+ (1,0) [0|0] "" Vector__XXX
 SG_ ICR_infoAssemblyId m11 : 40|8@1+ (1,0) [0|0] "" Vector__XXX
 SG_ ICR_infoUsageId m11 : 48|16@1+ (1,0) [0|0] "" Vector__XXX

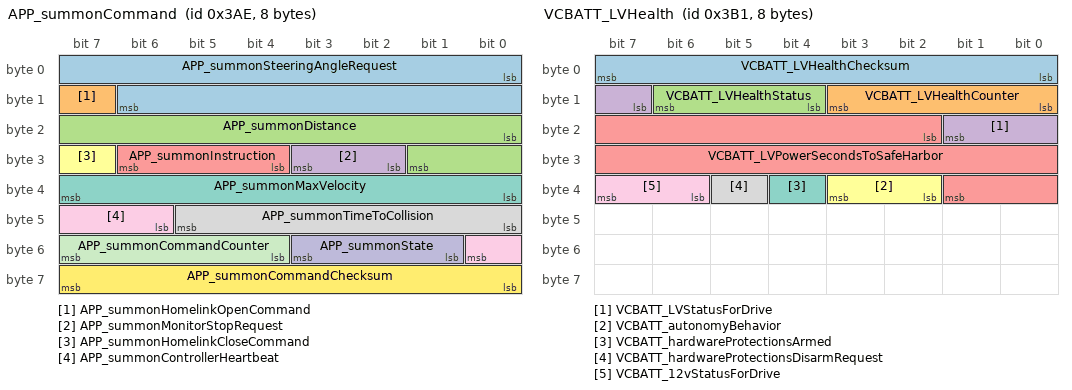
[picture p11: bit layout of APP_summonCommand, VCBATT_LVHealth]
BO_ 942 APP_summonCommand: 8 Vector__XXX
 SG_ APP_summonSteeringAngleRequest : 0|15@1+ (0.1,-1638.35) [0|0] "" Vector__XXX
 SG_ APP_summonHomelinkOpenCommand : 15|1@1+ (1,0) [0|0] "" Vector__XXX
 SG_ APP_summonDistance : 16|10@1+ (0.02,0) [0|0] "" Vector__XXX
 SG_ APP_summonMonitorStopRequest : 26|2@1+ (1,0) [0|0] "" Vector__XXX
 SG_ APP_summonInstruction : 28|3@1+ (1,0) [0|0] "" Vector__XXX
 SG_ APP_summonHomelinkCloseCommand : 31|1@1+ (1,0) [0|0] "" Vector__XXX
 SG_ APP_summonMaxVelocity : 32|8@1+ (0.05,0) [0|0] "" Vector__XXX
 SG_ APP_summonTimeToCollision : 40|6@1+ (0.1,0) [0|0] "" Vector__XXX
 SG_ APP_summonControllerHeartbeat : 46|3@1+ (1,0) [0|0] "" Vector__XXX
 SG_ APP_summonState : 49|3@1+ (1,0) [0|0] "" Vector__XXX
 SG_ APP_summonCommandCounter : 52|4@1+ (1,0) [0|0] "" Vector__XXX
 SG_ APP_summonCommandChecksum : 56|8@1+ (1,0) [0|0] "" Vector__XXX

BO_ 945 VCBATT_LVHealth: 8 Vector__XXX
 SG_ VCBATT_LVHealthChecksum : 0|8@1+ (1,0) [0|0] "" Vector__XXX
 SG_ VCBATT_LVHealthCounter : 8|4@1+ (1,0) [0|0] "" Vector__XXX
 SG_ VCBATT_LVHealthStatus : 12|3@1+ (1,0) [0|0] "" Vector__XXX
 SG_ VCBATT_LVStatusForDrive : 15|3@1+ (1,0) [0|0] "" Vector__XXX
 SG_ VCBATT_LVPowerSecondsToSafeHarbor : 18|16@1+ (1,0) [0|0] "" Vector__XXX
 SG_ VCBATT_autonomyBehavior : 34|2@1+ (1,0) [0|0] "" Vector__XXX
 SG_ VCBATT_hardwareProtectionsArmed : 36|1@1+ (1,0) [0|0] "" Vector__XXX
 SG_ VCBATT_hardwareProtectionsDisarmRequest : 37|1@1+ (1,0) [0|0] "" Vector__XXX
 SG_ VCBATT_12vStatusForDrive : 38|2@1+ (1,0) [0|0] "" Vector__XXX

VAL_ 864 VCLEFT_matrixIndex 0 "AlertMatrix0" 1 "AlertMatrix1" 2 "AlertMatrix2" 3 "AlertMatrix3" 4 "AlertMatrix4" 5 "AlertMatrix5" 6 "AlertMatrix6" 7 "AlertMatrix7" 8 "AlertMatrix8" 9 "AlertMatrix9" ;
VAL_ 866 VCLEFT_crashDetectedType 0 "NONE" 1 "MINOR_1" 2 "MINOR_2" 3 "SEVERE" ;
VAL_ 866 VCLEFT_crashState 0 "IDLE" 1 "MINOR_1" 2 "MINOR_2" 3 "SEVERE" ;
VAL_ 867 CMP_infoIndex 0 "DEPRECATED_0" 1 "DEPRECATED_1" 2 "DEPRECATED_2" 3 "DEPRECATED_3" 4 "DEPRECATED_4" 5 "DEPRECATED_5" 6 "DEPRECATED_6" 7 "DEPRECATED_7" 8 "DEPRECATED_8" 9 "DEPRECATED_9" 10 "BUILD_HWID_COMPONENTID" 11 "PCBAID_ASSYID_USAGEID" 13 "APP_CRC" 14 "BOOTLOADER_SVN" 15 "BOOTLOADER_CRC" 16 "SUBCOMPONENT" 17 "APP_GITHASH" 18 "BOOTLOADER_GITHASH" 19 "VERSION_DEPRECATED" 20 "UDS_PROTOCOL_BOOTCRC" 22 "VARIANTCRC" 25 "PACKAGE_PN_1_7" 26 "PACKAGE_PN_8_14" 27 "PACKAGE_PN_15_20" 29 "PACKAGE_SN_1_7" 30 "PACKAGE_SN_8_14" 31 "SUBCOMPONENT_GITHASH" 255 "END" ;
VAL_ 867 CMP_infoBuildType 0 "UNKNOWN_BUILD" 1 "PLATFORM_BUILD" 2 "LOCAL_BUILD" 3 "TRACEABLE_CI_BUILD" 4 "MFG_BUILD" ;
VAL_ 867 CMP_infoAssemblyId 1 "ASSEMBLY1" 255 "ASSEMBLY_SNA" ;
VAL_ 870 CMPD_infoIndex 0 "DEPRECATED_0" 1 "DEPRECATED_1" 2 "DEPRECATED_2" 3 "DEPRECATED_3" 4 "DEPRECATED_4" 5 "DEPRECATED_5" 6 "DEPRECATED_6" 7 "DEPRECATED_7" 8 "DEPRECATED_8" 9 "DEPRECATED_9" 10 "BUILD_HWID_COMPONENTID" 11 "PCBAID_ASSYID_USAGEID" 13 "APP_CRC" 14 "BOOTLOADER_SVN" 15 "BOOTLOADER_CRC" 16 "SUBCOMPONENT" 17 "APP_GITHASH" 18 "BOOTLOADER_GITHASH" 19 "VERSION_DEPRECATED" 20 "UDS_PROTOCOL_BOOTCRC" 22 "VARIANTCRC" 25 "PACKAGE_PN_1_7" 26 "PACKAGE_PN_8_14" 27 "PACKAGE_PN_15_20" 29 "PACKAGE_SN_1_7" 30 "PACKAGE_SN_8_14" 31 "SUBCOMPONENT_GITHASH" 255 "END" ;
VAL_ 870 CMPD_infoBuildType 0 "UNKNOWN_BUILD" 1 "PLATFORM_BUILD" 2 "LOCAL_BUILD" 3 "TRACEABLE_CI_BUILD" 4 "MFG_BUILD" ;
VAL_ 870 CMPD_infoAssemblyId 1 "ASSEMBLY1" 255 "ASSEMBLY_SNA" ;
VAL_ 882 BMS_log1MuxId 0 "CPU_USAGE1" 1 "CPU_USAGE2" 2 "CPU_USAGE3" 3 "STATES_AND_BOOLS" 4 "POS_CTR_HEALTH_1" 5 "POS_CTR_HEALTH_2" 6 "NEG_CTR_HEALTH_1" 7 "NEG_CTR_HEALTH_2" 8 "CHARGE_INTERFACE_1" 9 "CHARGE_INTERFACE_2" 10 "BANDOLIER_MODEL_PACK_TEMPS" 11 "BANDOLIER_MODEL_MODULE_TEMPS" 12 "CHARGE_TERMINATION" 13 "CHARGE_REGULATION" 14 "SOC_BY_DELTA_V_1" 15 "SOC_BY_DELTA_V_2" 16 "MISSING_P_COUNT_1" 17 "MISSING_P_COUNT_2" 18 "PACK_DATA" ;
VAL_ 882 BMS_battTempPct 255 "SNA" ;
VAL_ 882 BMS_packVoltage 65535 "SNA" ;
VAL_ 883 UI_mapSpeedLimitUnits 0 "MPH" 1 "KPH" ;
VAL_ 883 UI_userSpeedOffsetUnits 0 "MPH" 1 "KPH" ;
VAL_ 883 UI_conditionalSpeedLimit 31 "SNA" ;
VAL_ 886 DIF_tempIndex 0 "Mux0" 1 "Mux1" 2 "Mux2" ;
VAL_ 886 DIF_inverterTQF 0 "INIT" 1 "IRRATIONAL" 2 "RATIONAL" 3 "UNKNOWN" ;
VAL_ 886 DIF_normalFetBurnIn 65535 "SNA" ;
VAL_ 886 DIF_additionalFetBurnIn 65535 "SNA" ;
VAL_ 893 CP_thermalStatusSelect 0 "0" 1 "1" ;
VAL_ 897 VCFRONT_logging1HzIndex 0 "COOLANT" 1 "FAN_DEMAND_CONDENSER_AND_FET_TEMPS" 2 "COOLANT_VALVE" 3 "HEADLAMP_TEMPS" 4 "HEADLAMP_AIM" 5 "HP_EXV_RANGE" 6 "HP_DATA_AND_ACCUMULATORS" 7 "HP_CONTROL_LOOP_AND_STATE" 8 "HP_CYCLE_MODEL" 9 "HP_EXV_CALIBRATION" 10 "HP_DISSIPATION_AND_POWER" 11 "HP_TEMPS_AND_DEMANDS" 12 "HP_PRESSURE_CONTROL" 13 "HP_ARBITRATION" 14 "HP_MODE_SELECT_AND_ESTIMATES" 15 "HP_MODE_OPTIONS_AND_ESTIMATES" 16 "BODY_CONTROL" 17 "COOLANT_2" 18 "HP_PT_TARGETS" 19 "MISC_ACTUATORS" 20 "MISC" 21 "PART_FAILURE_CONFIDENCE" 22 "PART_FAILURE_CONFIDENCE_CONTINUED" 23 "MISC_TWO" 24 "END" ;
VAL_ 897 VCFRONT_coolantValveRecalReason 0 "UNDEFINED" 1 "MAX_TRAVEL" 2 "GENERAL_FAULT" 3 "CALIBRATION_FAULT_NO_TRAVEL" 4 "SELF_TEST" 5 "MOTOR_FEEDBACK_INTERRUPTED" 6 "NVRAM_LOSS" 7 "SYSTEM_LEVEL_FAULT_RESPONSE" ;
VAL_ 897 VCFRONT_louverPosReason 0 "NONE" 1 "CONDENSOR_MANAGER" 2 "PASSIVE_MANAGER" 3 "SNIFFING" 4 "BOUNDS_CHECK" 5 "FAN_RUN" 6 "FAN_FAULT" 7 "COAST_MODE" 8 "UDS" ;
VAL_ 897 VCFRONT_modeTransitionID 0 "PARALLEL_F1_noFlowRequest" 1 "SERIES_F2_faultPumps" 2 "SERIES_F3_faultTempSensors" 3 "SER_2_drive_battBelowHotStagnationTemp" 4 "SER_3_drive_chillerPassivelyCools" 5 "SER_4_drive_radPassivelyCoolsBatt" 6 "SER_5_drive_battBelowPassiveOrNeedsHeat" 7 "SER_6_FC_battHeatingNeeded" 8 "PAR_2_drive_battNeedsActiveCooling" 9 "PAR_3_drive_ptNeedsActiveCooling" 10 "PAR_4_drive_chillerPassivelyCoolsBatt" 11 "PAR_5_drive_cannotPassivelyCoolBatt" 12 "PAR_6_drive_battAboveHotStagnationTemp" 13 "PAR_7_FC_battNeedsActiveCooling" 14 "PAR_8_FC_ptNeedsActiveCooling" 15 "PAR_9_FC_battAboveHotStagnationTemp" 16 "INIT" 17 "OVERRIDE" 18 "UNDEFINED" 19 "ENTER_AMBIENTSOURCE" 20 "EXIT_AMBIENTSOURCE" 21 "PAR_1_dragStripMode" 22 "SER_1_dragStripMode" 23 "SER_7_charge_battBelowPassiveTarget" 24 "PAR_10_charge_battAbovePassiveTarget" 25 "SER_8_service_highCoolantFlowReq" ;
VAL_ 897 VCFRONT_coolantValveCountRange 1023 "SNA" ;
VAL_ 897 VCFRONT_modeDesired 0 "SERIES" 1 "PARALLEL" 2 "BLEND" 3 "AMBIENT_SOURCE" ;
VAL_ 897 VCFRONT_tempRefrigDischarge 2047 "SNA" ;
VAL_ 897 VCFRONT_pumpBatteryRPMTarget 1023 "SNA" ;
VAL_ 897 VCFRONT_tempRefrigSuction 255 "SNA" ;
VAL_ 897 VCFRONT_pumpPowertrainRPMTarget 1023 "SNA" ;
VAL_ 897 VCFRONT_pumpBatteryFETTemp 255 "SNA" ;
VAL_ 897 VCFRONT_tempSuperheatActual 1023 "SNA" ;
VAL_ 897 VCFRONT_pumpPowertrainFETTemp 255 "SNA" ;
VAL_ 897 VCFRONT_radBypassMoveReason 0 "INIT_UNBYPASS" 1 "INIT_BYPASS" 2 "PASSIVE_UNBYPASS" 3 "PASSIVE_BYPASS" 4 "RAD_HEAT_BYPASS" 5 "RAD_HEAT_UNBYPASS" 6 "ACTIVE_PT_UNBYPASS" 7 "ACTIVE_BATT_UNBYPASS" 8 "EXIT_SERIES" 9 "UDS" ;
VAL_ 897 VCFRONT_tempRefrigLiquid 2047 "SNA" ;
VAL_ 897 VCFRONT_radiatorFanFETTemp 255 "SNA" ;
VAL_ 897 VCFRONT_coolantValveRadBypass 127 "SNA" ;
VAL_ 897 VCFRONT_passiveCoolingState 0 "ChillerCoolsSeriesLoop" 1 "ChillerCoolsParallelBattLoop" 2 "ChillerAndRadCoolSeriesLoop" 3 "CannotCoolBattery" ;
VAL_ 897 VCFRONT_radiatorFanRunReason 0 "NONE" 1 "ACTIVE_MANAGER" 2 "AMBIENT_SNIFF" 3 "NVH_MASKING" 4 "HEAT_PUMP" 5 "COAST_MODE" 6 "MIN_ON_GLOBAL" 7 "MIN_ON_NVH" 8 "UDS" 9 "RAD_CLEAR" 10 "DI_BURN_IN" ;
VAL_ 897 VCFRONT_hpRefrigerantPurgeState 0 "IDLE" 1 "EVAP_PURGE" 2 "COMPLETE" ;
VAL_ 899 VCRIGHT_thsTemperature 4294967168 "SNA" ;
VAL_ 899 VCRIGHT_thsState 0 "INIT" 1 "CONFIG" 2 "WAIT_CRC_REQUEST" 3 "WAIT_CRC_RESPONSE" 4 "IDLE" ;
VAL_ 899 VCRIGHT_thsHumidity 255 "SNA" ;
VAL_ 899 VCRIGHT_estimatedVehicleSituation 0 "UNKNOWN" 1 "INDOOR" 2 "OUTDOOR" ;
VAL_ 899 VCRIGHT_thsSolarLoadInfrared 1023 "SNA" ;
VAL_ 899 VCRIGHT_thsSolarLoadVisible 1023 "SNA" ;
VAL_ 899 VCRIGHT_estimatedThsSolarLoad 1023 "SNA" ;
VAL_ 914 BMS_packConfigMultiplexer 0 "Mux0" 1 "Mux1" ;
VAL_ 914 BMS_moduleType 0 "UNKNOWN" 1 "E3_NCT" 2 "E1_NCT" 3 "E3_CT" 4 "E1_CT" 5 "E1_CP" ;
VAL_ 914 BMS_reservedConfig_0 0 "0" 1 "1" 2 "2" 3 "3" 4 "4" 5 "5" 6 "6" 7 "7" 8 "8" 9 "9" 10 "10" 11 "11" 12 "12" 13 "13" 14 "14" 15 "15" 16 "16" 17 "17" 18 "18" 19 "19" 20 "20" 21 "21" 22 "22" 23 "23" 24 "24" 25 "25" 26 "26" 27 "27" 28 "28" 29 "29" 30 "30" 31 "31" ;
VAL_ 914 BMS_beginningOfLifePackEnergy 1023 "SNA" ;
VAL_ 915 VCRIGHT_epbmDebugIndex 0 "STATES" 1 "TRANSITIONS" ;
VAL_ 915 VCRIGHT_epbmCaliperState 0 "UNSAVED" 1 "UNKNOWN" 2 "REAPPLY" 3 "PARK" 4 "OPEN" 5 "SERVICE" 6 "WINCHMODE" ;
VAL_ 915 VCRIGHT_summonFaultReason 0 "NONE" 1 "DI_MIA" 2 "DAS_MIA" 3 "ESP_MIA" 4 "EPBM_MIA" 5 "DI_FAULT" 6 "DI_APC_FAULT" 7 "DAS_FAULT" 8 "ESP_FAULT" 9 "VEH_CAN_FAULT" 10 "EAC_NOT_ALLOWED" 11 "EPBM_REQUEST" 12 "SPEED" 13 "EXTERNAL" 14 "PARK_MIA" 15 "PM_MIA" 16 "PM_REQUEST" 17 "OOC" 18 "MISMATCH" 19 "EPB_FAULT" 20 "DI_STATE_INVALID" 21 "PASSIVE_REQUEST" 22 "EPBREMOTE_MIA" 23 "REMOTE_SUMMON_FAULTED" 24 "LOCAL_UNIT_FAULTED" 25 "REMOTE_UNIT_FAULTED" 26 "START_IN_UNAVAILABLE" 27 "INVALID_REMOTE_STATE" 28 "REMOTE_DID_NOT_START" ;
VAL_ 915 VCRIGHT_epbSummonState 0 "INIT" 1 "IDLE" 2 "ARMED" 3 "ACTIVE" 4 "COMPLETE" 5 "FAULT" 6 "UNAVAILABLE" ;
VAL_ 915 VCRIGHT_epbmSummonState 0 "INIT" 1 "IDLE" 2 "ARMED" 3 "ACTIVE" 4 "COMPLETE" 5 "FAULT" 6 "UNAVAILABLE" ;
VAL_ 915 VCRIGHT_epbUnitStatus 0 "UNKNOWN" 1 "OPEN" 2 "DYNAMIC" 3 "PARK" 4 "START" 5 "SERVICE" 6 "WINCHMODE" 7 "WINCHMODE_RELEASING" 8 "PARKING" 9 "DYNAMIC_APPLYING" 10 "RELEASING" 11 "SERVICE_RELEASING" 12 "PARK_PENDING" 13 "WINCHMODE_PENDING" 14 "SUMMON" 15 "SUMMON_RELEASING" 16 "SUMMON_PARKING" 17 "EXTERNAL_DYNAMIC" 18 "RELEASING_FOR_EXTERNAL_PARK" 19 "EXTERNAL_PARKING" 20 "DYNAMIC_PARKING" 21 "FREE_ROLL_MODE" 22 "COUNT" ;
VAL_ 915 VCRIGHT_epbmFaultStatus 0 "NOMINAL" 1 "RETRY" 2 "FAULT" 3 "FAULT_IDLE" ;
VAL_ 915 VCRIGHT_epbFaultStatus 0 "NOMINAL" 1 "RETRY" 2 "FAULT" 3 "FAULT_IDLE" ;
VAL_ 915 VCRIGHT_epbmSystemStatus 0 "UNKNOWN" 1 "RELEASED" 2 "PARKED" 3 "DYNAMIC" 4 "PARKING" 5 "RELEASING" 6 "FAULT" 7 "FAULT_SECURE" 8 "MISMATCH" ;
VAL_ 917 DIR_oilPumpState 0 "STANDBY" 1 "ENABLE" 2 "COLD_STARTUP" 6 "FAULTED" 7 "SNA" ;
VAL_ 917 DIR_oilPumpFluidTQF 0 "LOW_CONFIDENCE" 1 "HIGH_CONFIDENCE" ;
VAL_ 917 DIR_oilPumpFlowTarget 255 "SNA" ;
VAL_ 917 DIR_oilPumpFlowActual 255 "SNA" ;
VAL_ 917 DIR_oilPumpFluidT 255 "SNA" ;
VAL_ 917 DIR_oilPumpPhaseCurrent 255 "SNA" ;
VAL_ 917 DIR_oilPumpPressureEstimate 255 "SNA" ;
VAL_ 917 DIR_oilPumpPressureExpected 255 "SNA" ;
VAL_ 917 DIR_oilPumpPressureResidual 255 "SNA" ;
VAL_ 918 DIF_oilPumpState 0 "STANDBY" 1 "ENABLE" 2 "COLD_STARTUP" 6 "FAULTED" 7 "SNA" ;
VAL_ 918 DIF_oilPumpFluidTQF 0 "LOW_CONFIDENCE" 1 "HIGH_CONFIDENCE" ;
VAL_ 918 DIF_oilPumpFlowTarget 255 "SNA" ;
VAL_ 918 DIF_oilPumpFlowActual 255 "SNA" ;
VAL_ 918 DIF_oilPumpFluidT 255 "SNA" ;
VAL_ 918 DIF_oilPumpPhaseCurrent 255 "SNA" ;
VAL_ 918 DIF_oilPumpPressureEstimate 255 "SNA" ;
VAL_ 918 DIF_oilPumpPressureExpected 255 "SNA" ;
VAL_ 918 DIF_oilPumpPressureResidual 255 "SNA" ;
VAL_ 921 VCSEC_crashDetectedType 0 "NONE" 1 "MINOR_1" 2 "MINOR_2" 3 "SEVERE" ;
VAL_ 921 VCSEC_crashState 0 "IDLE" 1 "MINOR_1" 2 "MINOR_2" 3 "SEVERE" ;
VAL_ 922 VCSEC_RSSI0ConnectionType 0 "NONE" 1 "PERIPHERAL" 2 "CENTRAL" ;
VAL_ 922 VCSEC_RSSI1ConnectionType 0 "NONE" 1 "PERIPHERAL" 2 "CENTRAL" ;
VAL_ 922 VCSEC_RSSI2ConnectionType 0 "NONE" 1 "PERIPHERAL" 2 "CENTRAL" ;
VAL_ 923 DAS_autopilotState 0 "DISABLED" 1 "UNAVAILABLE" 2 "AVAILABLE" 3 "ACTIVE_NOMINAL" 4 "ACTIVE_RESTRICTED" 5 "ACTIVE_NAV" 6 "ACTIVE_FSD" 8 "ABORTING" 9 "ABORTED" 14 "FAULT" 15 "SNA" ;
VAL_ 923 DAS_blindSpotRearLeft 0 "NO_WARNING" 1 "WARNING_LEVEL_1" 2 "WARNING_LEVEL_2" 3 "SNA" ;
VAL_ 923 DAS_blindSpotRearRight 0 "NO_WARNING" 1 "WARNING_LEVEL_1" 2 "WARNING_LEVEL_2" 3 "SNA" ;
VAL_ 923 DAS_fusedSpeedLimit 0 "UNKNOWN_SNA" 31 "NONE" ;
VAL_ 923 DAS_suppressSpeedWarning 0 "Do_Not_Suppress" 1 "Suppress_Speed_Warning" ;
VAL_ 923 DAS_visionOnlySpeedLimit 0 "UNKNOWN_SNA" 31 "NONE" ;
VAL_ 923 DAS_heaterState 0 "OFF_SNA" 1 "ON" ;
VAL_ 923 DAS_forwardCollisionWarning 0 "NONE" 1 "FORWARD_COLLISION_WARNING" 3 "SNA" ;
VAL_ 923 DAS_autoparkReady 0 "UNAVAILABLE" 1 "READY" ;
VAL_ 923 DAS_lssState 0 "FAULT" 1 "LDW" 2 "LKA" 3 "ELK" 4 "MONITOR" 5 "BLINDSPOT" 6 "ABORT" 7 "OFF" ;
VAL_ 923 DAS_sideCollisionAvoid 0 "NONE" 1 "AVOID_LEFT" 2 "AVOID_RIGHT" 3 "SNA" ;
VAL_ 923 DAS_sideCollisionWarning 0 "NONE" 1 "WARN_LEFT" 2 "WARN_RIGHT" 3 "WARN_LEFT_RIGHT" ;
VAL_ 923 DAS_sideCollisionInhibit 0 "NO_INHIBIT" 1 "INHIBIT" ;
VAL_ 923 DAS_laneDepartureWarning 0 "NONE" 1 "LEFT_WARNING" 2 "RIGHT_WARNING" 3 "LEFT_WARNING_SEVERE" 4 "RIGHT_WARNING_SEVERE" 5 "SNA" ;
VAL_ 923 DAS_fleetSpeedState 0 "UNAVAILABLE" 1 "AVAILABLE" 2 "ACTIVE" 3 "HOLD" ;
VAL_ 923 DAS_autopilotHandsOnState 0 "NOT_REQD" 1 "REQD_DETECTED" 2 "REQD_NOT_DETECTED" 3 "REQD_VISUAL" 4 "REQD_CHIME_1" 5 "REQD_CHIME_2" 6 "REQD_SLOWING" 7 "REQD_STRUCK_OUT" 8 "SUSPENDED" 9 "REQD_ESCALATED_CHIME_1" 10 "REQD_ESCALATED_CHIME_2" 15 "SNA" ;
VAL_ 923 DAS_autoLaneChangeState 0 "UNAVAILABLE_DISABLED" 1 "UNAVAILABLE_NO_LANES" 2 "UNAVAILABLE_SONICS_INVALID" 3 "UNAVAILABLE_TP_FOLLOW" 4 "UNAVAILABLE_EXITING_HIGHWAY" 5 "UNAVAILABLE_VEHICLE_SPEED" 6 "AVAILABLE_ONLY_L" 7 "AVAILABLE_ONLY_R" 8 "AVAILABLE_BOTH" 9 "IN_PROGRESS_L" 10 "IN_PROGRESS_R" 11 "WAITING_FOR_SIDE_OBST_TO_PASS_L" 12 "WAITING_FOR_SIDE_OBST_TO_PASS_R" 13 "WAITING_FOR_FWD_OBST_TO_PASS_L" 14 "WAITING_FOR_FWD_OBST_TO_PASS_R" 15 "ABORT_SIDE_OBSTACLE_PRESENT_L" 16 "ABORT_SIDE_OBSTACLE_PRESENT_R" 17 "ABORT_POOR_VIEW_RANGE" 18 "ABORT_LC_HEALTH_BAD" 19 "ABORT_BLINKER_TURNED_OFF" 20 "ABORT_OTHER_REASON" 21 "UNAVAILABLE_SOLID_LANE_LINE" 22 "BLOCKED_VEH_TTC_L" 23 "BLOCKED_VEH_TTC_AND_USS_L" 24 "BLOCKED_VEH_TTC_R" 25 "BLOCKED_VEH_TTC_AND_USS_R" 26 "BLOCKED_LANE_TYPE_L" 27 "BLOCKED_LANE_TYPE_R" 28 "WAITING_HANDS_ON" 29 "ABORT_TIMEOUT" 30 "ABORT_MISSION_PLAN_INVALID" 31 "SNA" ;
VAL_ 925 IBST_iBoosterStatus 0 "OFF" 1 "INIT" 2 "FAILURE" 3 "DIAGNOSTIC" 4 "ACTIVE_GOOD_CHECK" 5 "READY" 6 "ACTUATION" ;
VAL_ 925 IBST_driverBrakeApply 0 "NOT_INIT_OR_OFF" 1 "BRAKES_NOT_APPLIED" 2 "DRIVER_APPLYING_BRAKES" 3 "FAULT" ;
VAL_ 925 IBST_internalState 0 "NO_MODE_ACTIVE" 1 "PRE_DRIVE_CHECK" 2 "LOCAL_BRAKE_REQUEST" 3 "EXTERNAL_BRAKE_REQUEST" 4 "DIAGNOSTIC" 5 "TRANSITION_TO_IDLE" 6 "POST_DRIVE_CHECK" ;
VAL_ 929 VCFRONT_vehicleStatusMuxIndex 0 "MUX0" 1 "MUX1" ;
VAL_ 929 VCFRONT_3RowLeftUnbuckled 0 "NONE" 1 "OCCUPIED_AND_UNBUCKLED" 2 "SNA" ;
VAL_ 929 VCFRONT_APGlassHeaterState 0 "SNA" 1 "ON" 2 "OFF" 3 "OFF_UNAVAILABLE" 4 "FAULT" ;
VAL_ 929 VCFRONT_3RowRightUnbuckled 0 "NONE" 1 "OCCUPIED_AND_UNBUCKLED" 2 "SNA" ;
VAL_ 929 VCFRONT_thermalSystemType 0 "LEGACY_THERMAL_SYSTEM" 1 "HEAT_PUMP_THERMAL_SYSTEM" ;
VAL_ 929 VCFRONT_diPowerOnState 0 "POWERED_OFF" 1 "POWERED_ON_FOR_SUMMON" 2 "POWERED_ON_FOR_STATIONARY_HEAT" 3 "POWERED_ON_FOR_DRIVE" 4 "POWER_GOING_DOWN" 5 "POWERED_ON_FOR_WINCH" ;
VAL_ 929 VCFRONT_12vStatusForDrive 0 "NOT_READY_FOR_DRIVE_12V" 1 "READY_FOR_DRIVE_12V" 2 "EXIT_DRIVE_REQUESTED_12V" ;
VAL_ 929 VCFRONT_driverBuckleStatus 0 "UNBUCKLED" 1 "BUCKLED" ;
VAL_ 929 VCFRONT_driverDoorStatus 0 "OPEN" 1 "CLOSED" ;
VAL_ 929 VCFRONT_driverUnbuckled 0 "NONE" 1 "OCCUPIED_AND_UNBUCKLED" 2 "SNA" ;
VAL_ 929 VCFRONT_passengerUnbuckled 0 "NONE" 1 "OCCUPIED_AND_UNBUCKLED" 2 "SNA" ;
VAL_ 929 VCFRONT_2RowLeftUnbuckled 0 "NONE" 1 "OCCUPIED_AND_UNBUCKLED" 2 "SNA" ;
VAL_ 929 VCFRONT_2RowCenterUnbuckled 0 "NONE" 1 "OCCUPIED_AND_UNBUCKLED" 2 "SNA" ;
VAL_ 929 VCFRONT_2RowRightUnbuckled 0 "NONE" 1 "OCCUPIED_AND_UNBUCKLED" 2 "SNA" ;
VAL_ 929 VCFRONT_pcsEFuseVoltage 1023 "SNA" ;
VAL_ 930 VCLEFT_statusIndex 0 "MUX0" 1 "MUX1" ;
VAL_ 930 VCLEFT_trailerAuxCurrent 4095 "SNA" ;
VAL_ 930 VCLEFT_swcHeatTmp 4294967168 "SNA" ;
VAL_ 930 VCLEFT_swcInputVoltage 255 "SNA" ;
VAL_ 930 VCLEFT_swcHeatStatus 0 "SNA" 1 "ON" 2 "OFF" 3 "OFF_UNAVAILABLE" 4 "FAULT" ;
VAL_ 930 VCLEFT_swcPCBATemperature 4294967168 "SNA" ;
VAL_ 932 PCS_matrixIndex 0 "AlertMatrix0" 1 "AlertMatrix1" ;
VAL_ 936 VCLEFT_logging1HzIndex 0 "HVAC_ACTUATOR_VOLTAGES" 1 "HVAC_ACTUATOR_ENDSTOP" 2 "HVAC_ACTUATOR_ZEROSTOP" 3 "HVAC_ACTUATOR_OPERATION_MODE" 4 "END" ;
VAL_ 938 HVP_matrixIndex 0 "AlertMatrix0" 1 "AlertMatrix1" 2 "AlertMatrix2" ;
VAL_ 941 ICR_infoIndex 0 "DEPRECATED_0" 1 "DEPRECATED_1" 2 "DEPRECATED_2" 3 "DEPRECATED_3" 4 "DEPRECATED_4" 5 "DEPRECATED_5" 6 "DEPRECATED_6" 7 "DEPRECATED_7" 8 "DEPRECATED_8" 9 "DEPRECATED_9" 10 "BUILD_HWID_COMPONENTID" 11 "PCBAID_ASSYID_USAGEID" 13 "APP_CRC" 14 "BOOTLOADER_SVN" 15 "BOOTLOADER_CRC" 16 "SUBCOMPONENT" 17 "APP_GITHASH" 18 "BOOTLOADER_GITHASH" 19 "VERSION_DEPRECATED" 20 "UDS_PROTOCOL_BOOTCRC" 22 "VARIANTCRC" 25 "PACKAGE_PN_1_7" 26 "PACKAGE_PN_8_14" 27 "PACKAGE_PN_15_20" 29 "PACKAGE_SN_1_7" 30 "PACKAGE_SN_8_14" 31 "SUBCOMPONENT_GITHASH" 255 "END" ;
VAL_ 941 ICR_infoBuildType 0 "UNKNOWN_BUILD" 1 "PLATFORM_BUILD" 2 "LOCAL_BUILD" 3 "TRACEABLE_CI_BUILD" 4 "MFG_BUILD" ;
VAL_ 941 ICR_infoAssemblyId 1 "ASSEMBLY1" 255 "ASSEMBLY_SNA" ;
VAL_ 942 APP_summonState 0 "INIT" 1 "IDLE" 2 "ARMED" 3 "ACTIVE" 4 "COMPLETE" 5 "FAULT" 6 "UNAVAILABLE" ;
VAL_ 945 VCBATT_12vStatusForDrive 0 "NOT_READY_FOR_DRIVE_12V" 1 "READY_FOR_DRIVE_12V" 2 "EXIT_DRIVE_REQUESTED_12V" ;
